VERSION ""

NS_ :

BS_:

BU_: SOBDMB_AWDC BCMC_CPDB BECMB_EPM PACM GWM _delete BCM ACCM DCDC_HEV GENERIC TSTR

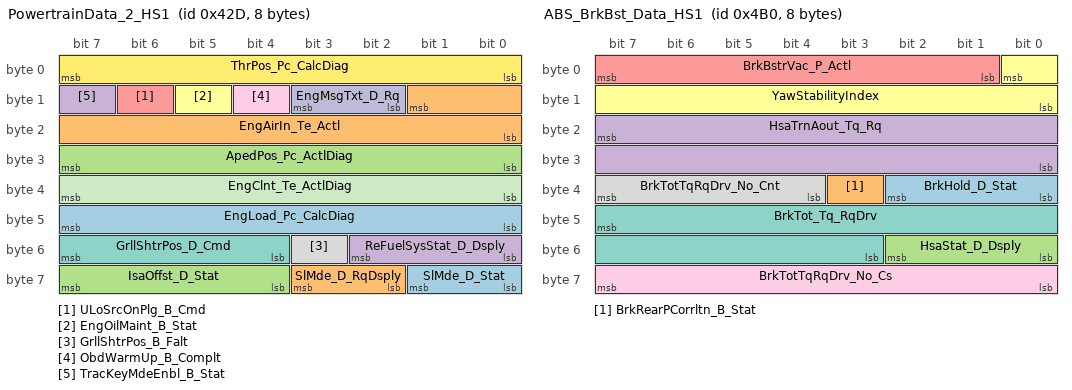
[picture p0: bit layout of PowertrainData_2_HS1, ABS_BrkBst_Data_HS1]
BO_ 1069 PowertrainData_2_HS1: 8 GWM
 SG_ SlMde_D_Stat : 57|2@0+ (1,0) [0|3] "SED" Vector__XXX
 SG_ SlMde_D_RqDsply : 59|2@0+ (1,0) [0|3] "SED" Vector__XXX
 SG_ IsaOffst_D_Stat : 63|4@0+ (1,0) [0|15] "SED" Vector__XXX
 SG_ ReFuelSysStat_D_Dsply : 50|3@0+ (1,0) [0|7] "SED" Vector__XXX
 SG_ ULoSrcOnPlg_B_Cmd : 14|1@0+ (1,0) [0|1] "SED"  DCDC_HEV
 SG_ EngOilMaint_B_Stat : 13|1@0+ (1,0) [0|1] "SED" Vector__XXX
 SG_ GrllShtrPos_D_Cmd : 55|4@0+ (1,0) [0|15] "SED"  BCM
 SG_ GrllShtrPos_B_Falt : 51|1@0+ (1,0) [0|1] "SED"  BCM
 SG_ ObdWarmUp_B_Complt : 12|1@0+ (1,0) [0|1] "SED"  SOBDMB_AWDC,DCDC_HEV
 SG_ EngMsgTxt_D_Rq : 11|2@0+ (1,0) [0|3] "SED" Vector__XXX
 SG_ EngClnt_Te_ActlDiag : 39|8@0+ (1,-40) [-40|215] "degC"  SOBDMB_AWDC
 SG_ ThrPos_Pc_CalcDiag : 7|8@0+ (0.392157,0) [0|100.000035] "%" Vector__XXX
 SG_ EngLoad_Pc_CalcDiag : 47|8@0+ (0.392157,0) [0|100.000035] "%"  SOBDMB_AWDC
 SG_ EngAirIn_Te_Actl : 9|10@0+ (0.25,-128) [-128|127.25] "degC"  BCM
 SG_ ApedPos_Pc_ActlDiag : 31|8@0+ (0.392157,0) [0|100.000035] "%"  SOBDMB_AWDC
 SG_ TracKeyMdeEnbl_B_Stat : 15|1@0+ (1,0) [0|1] "SED" Vector__XXX

BO_ 878 DCACA_Data4_HS1: 8 GWM
 SG_ PwBedPnlEnblScnd_B_Rq : 48|1@0+ (1,0) [0|1] "SED" Vector__XXX
 SG_ DcacSysScnd_B_Falt : 40|1@0+ (1,0) [0|1] "SED" Vector__XXX
 SG_ DcacOnScnd_B_Rq : 32|1@0+ (1,0) [0|1] "SED" Vector__XXX
 SG_ DcacGfciTestScnd_B_Rq : 24|1@0+ (1,0) [0|1] "SED" Vector__XXX
 SG_ EngExhMdeHrStrt_D_Stat : 53|5@0+ (1,0) [0|31] "SED" Vector__XXX
 SG_ EngExhMdeHrEnd_D_Stat : 63|5@0+ (1,0) [0|31] "SED" Vector__XXX
 SG_ EngExhMdeHrEnbl_D_Stat : 58|2@0+ (1,0) [0|3] "SED" Vector__XXX
 SG_ DcacGfciTest_B_Rq : 0|1@0+ (1,0) [0|1] "SED" Vector__XXX
 SG_ DcacOut_Pw_DsplyMx : 23|10@0+ (10,0) [0|10220] "watts"  GENERIC
 SG_ DcacOut1_Pw_Dsply : 39|7@0+ (100,0) [0|12600] "watts"  GENERIC
 SG_ DcacOut2_Pw_Dsply : 47|7@0+ (100,0) [0|12600] "watts"  GENERIC
 SG_ DcacHw_D_Confg : 11|4@0+ (1,0) [0|15] "SED"  GENERIC
 SG_ DcacFaltMsgTxt_D_Rq : 15|4@0+ (1,0) [0|15] "SED" Vector__XXX
 SG_ DcacLoFuelMsgTxt_D_Rq : 29|5@0+ (1,0) [0|31] "SED"  GENERIC
 SG_ DcacEngOnMsgTxt_D_Rq : 55|2@0+ (1,0) [0|3] "SED"  GENERIC
 SG_ DcacElPw_D_Stat : 2|2@0+ (1,0) [0|3] "SED" Vector__XXX
 SG_ PwBedPnlEnbl_B_Rq : 3|1@0+ (1,0) [0|1] "SED" Vector__XXX
 SG_ DcacOn_B_Rq : 4|1@0+ (1,0) [0|1] "SED" Vector__XXX
 SG_ DcacSys_B_Falt : 5|1@0+ (1,0) [0|1] "SED" Vector__XXX
 SG_ DcacLedCtl_D_Rq : 7|2@0+ (1,0) [0|3] "SED" Vector__XXX

BO_ 1200 ABS_BrkBst_Data_HS1: 8 GWM
 SG_ BrkHold_D_Stat : 34|3@0+ (1,0) [0|7] "SED" Vector__XXX
 SG_ BrkRearPCorrltn_B_Stat : 35|1@0+ (1,0) [0|1] "SED"  GENERIC
 SG_ HsaStat_D_Dsply : 50|3@0+ (1,0) [0|7] "SED"  GENERIC
 SG_ HsaTrnAout_Tq_Rq : 23|16@0+ (4,-131072) [-131072|131060] "Nm" Vector__XXX
 SG_ BrkBstrVac_P_Actl : 7|7@0+ (8,0) [0|1008] "Millibar" Vector__XXX
 SG_ YawStabilityIndex : 0|9@0+ (1,-256) [-256|255] "%"  GENERIC
 SG_ BrkTot_Tq_RqDrv : 47|13@0+ (4,0) [0|32760] "Nm" Vector__XXX
 SG_ BrkTotTqRqDrv_No_Cnt : 39|4@0+ (1,0) [0|15] "unitless" Vector__XXX
 SG_ BrkTotTqRqDrv_No_Cs : 63|8@0+ (1,0) [0|255] "unitless" Vector__XXX

BO_ 2015 TesterFunctionalReq_H1: 8 TSTR
 SG_ TesterFunctionalReq : 7|64@0+ (1,0) [0|1.84467E+019] "unitless"  SOBDMB_AWDC,BCMC_CPDB,BECMB_EPM,PACM,ACCM,GWM,GENERIC,DCDC_HEV,BCM

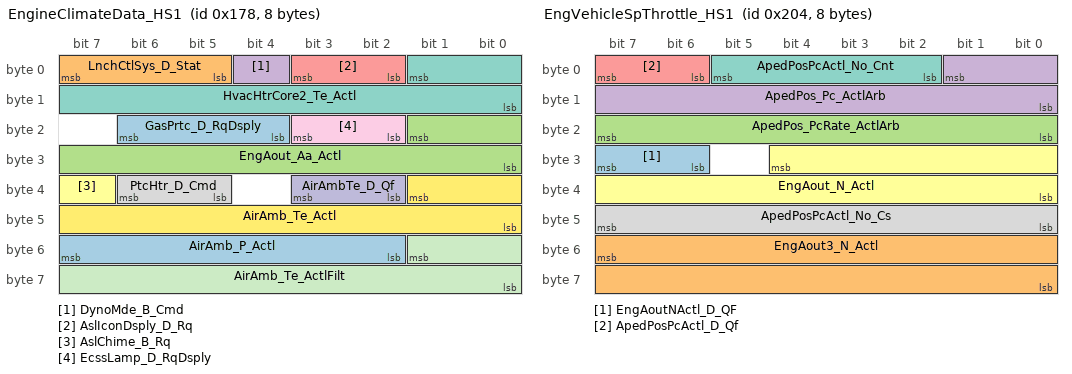
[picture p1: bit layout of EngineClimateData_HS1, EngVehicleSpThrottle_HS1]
BO_ 376 EngineClimateData_HS1: 8 GWM
 SG_ GasPrtc_D_RqDsply : 22|3@0+ (1,0) [0|7] "SED"  GENERIC
 SG_ LnchCtlSys_D_Stat : 7|3@0+ (1,0) [0|7] "SED"  GENERIC
 SG_ EngAout_Aa_Actl : 17|10@0+ (0.05,-25.6) [-25.6|25.55] "rpm/ms"  GENERIC
 SG_ DynoMde_B_Cmd : 4|1@0+ (1,0) [0|1] "SED"  GENERIC
 SG_ AslIconDsply_D_Rq : 3|2@0+ (1,0) [0|3] "SED"  GENERIC
 SG_ AslChime_B_Rq : 39|1@0+ (1,0) [0|1] "SED"  GENERIC
 SG_ HvacHtrCore2_Te_Actl : 1|10@0+ (0.25,-50) [-50|205.5] "degC"  GENERIC
 SG_ PtcHtr_D_Cmd : 38|2@0+ (1,0) [0|3] "SED"  GENERIC
 SG_ EcssLamp_D_RqDsply : 19|2@0+ (1,0) [0|3] "SED"  GENERIC
 SG_ AirAmbTe_D_Qf : 35|2@0+ (1,0) [0|3] "SED"  BCM
 SG_ AirAmb_Te_ActlFilt : 49|10@0+ (0.25,-128) [-128|127.75] "deg C"  GWM,ACCM,BCM
 SG_ AirAmb_Te_Actl : 33|10@0+ (0.25,-128) [-128|127.75] "degC"  BCM
 SG_ AirAmb_P_Actl : 55|6@0+ (10,500) [500|1110] "mbar"  BCM

BO_ 516 EngVehicleSpThrottle_HS1: 8 GWM
 SG_ EngAoutNActl_D_QF : 31|2@0+ (1,0) [0|3] "SED"  GENERIC
 SG_ EngAout3_N_Actl : 55|16@0+ (0.25,0) [0|16383.5] "RPM"  SOBDMB_AWDC
 SG_ ApedPos_PcRate_ActlArb : 23|8@0+ (0.04,-5) [-5|5.12] "%/ms"  GENERIC
 SG_ ApedPos_Pc_ActlArb : 1|10@0+ (0.1,0) [0|102.3] "%"  SOBDMB_AWDC,BCM
 SG_ ApedPosPcActl_D_Qf : 7|2@0+ (1,0) [0|3] "SED"  GENERIC
 SG_ EngAout_N_Actl : 28|13@0+ (2,0) [0|16382] "rpm"  BCM
 SG_ ApedPosPcActl_No_Cnt : 5|4@0+ (1,0) [0|15] "Unitless"  GENERIC
 SG_ ApedPosPcActl_No_Cs : 47|8@0+ (1,0) [0|255] "Unitless"  GENERIC

BO_ 377 EngineData_7_HS1: 8 GWM
 SG_ HvacAirFullOut_B_Rq : 23|1@0+ (1,0) [0|1] "SED"  GENERIC
 SG_ TrnManShif_D_IndDrv : 7|3@0+ (1,0) [0|7] "Unitless"  GENERIC
 SG_ EngAout_Tq_Actl : 2|11@0+ (1,-500) [-500|1547] "Nm"  GENERIC
 SG_ TrnManShifGear_D_IndDrv : 54|3@0+ (1,0) [0|7] "SED"  GENERIC
 SG_ EngFuelCutFull_B_Inhbt : 22|1@0+ (1,0) [0|1] "SED"  GENERIC
 SG_ EngDecelFuelCut_B_Allw : 21|1@0+ (1,0) [0|1] "SED"  GENERIC
 SG_ FuelFlw_Vl_Dsply : 49|10@0+ (25,0) [0|25575] "Micro_Liter"  GENERIC
 SG_ FuelFillInlet_B_Dsply : 32|1@0+ (1,0) [0|1] "SED"  GENERIC
 SG_ EngSrvcRqd_B_Rq : 19|1@0+ (1,0) [0|1] "SED"  GENERIC
 SG_ OdoCount : 47|8@0+ (0.2,0) [0|50.8] "Meters"  GENERIC
 SG_ EngOilLife_Pc_Actl : 39|7@0+ (1,0) [0|100] "Percent"  GENERIC
 SG_ EngTqSlwDly_T_Est : 18|11@0+ (1,0) [0|2047] "ms"  GENERIC
 SG_ TrnKickDown_B_RqDrv : 20|1@0+ (1,0) [0|1] "SED"  GENERIC
 SG_ FuelFilterLamp_B_Dsply : 50|1@0+ (1,0) [0|1] "SED"  GENERIC
 SG_ AirCondRec_B_Rq : 55|1@0+ (1,0) [0|1] "SED"  GENERIC
 SG_ AirCondClutch_B_Stats : 51|1@0+ (1,0) [0|1] "SED" Vector__XXX
 SG_ EngAoutTqActl_D_Qf : 4|2@0+ (1,0) [0|3] "SED"  GENERIC

BO_ 76 RCMStatusMessage2_HS1: 8 GWM
 SG_ RstrnPsngrOn_D_Stat : 39|4@0+ (1,0) [0|15] "SED"  GENERIC
 SG_ FirstRowBuckle_No_Cs : 47|8@0+ (1,0) [0|255] "unitless"  GENERIC
 SG_ RCMStatusMsg2_No_Cnt : 35|4@0+ (1,0) [0|15] "Unitless"  GENERIC
 SG_ PsngrFmidDetct_D_Actl : 26|2@0+ (1,0) [0|3] "SED"  GENERIC
 SG_ FirstRowBuckleMid : 28|2@0+ (1,0) [0|3] "SED"  GENERIC
 SG_ ThirdRowBucklePsngr : 17|2@0+ (1,0) [0|3] "SED"  GENERIC
 SG_ ThirdRowBuckleMid : 19|2@0+ (1,0) [0|3] "SED"  GENERIC
 SG_ ThirdRowBuckleDriver : 21|2@0+ (1,0) [0|3] "SED"  GENERIC
 SG_ SecondRowBucklePsngr : 23|2@0+ (1,0) [0|3] "SED"  GENERIC
 SG_ SecondRowBuckleMid : 9|2@0+ (1,0) [0|3] "SED"  GENERIC
 SG_ SecondRowBuckleDriver : 11|2@0+ (1,0) [0|3] "SED"  GENERIC
 SG_ FirstRowBuckleDriver : 15|2@0+ (1,0) [0|3] "SED"  BCM
 SG_ RILReq : 7|2@0+ (1,0) [0|3] "SED"  GENERIC
 SG_ FirstRowBucklePsngr : 13|2@0+ (1,0) [0|3] "SED" Vector__XXX
 SG_ RstrnImpactEvntStatus : 3|3@0+ (1,0) [0|7] "SED"  ACCM,BCM
 SG_ PsngrFrntDetct_D_Actl : 5|2@0+ (1,0) [0|3] "SED"  GENERIC
 SG_ EDRTriggerEvntSync : 29|1@0+ (1,0) [0|1] "SED"  GENERIC
 SG_ PassRstrnInd_Req : 31|2@0+ (1,0) [0|3] "SED"  GENERIC

BO_ 1870 TesterPhysicalResDCDC: 8 DCDC_HEV
 SG_ TesterPhysicalResDCDC : 7|64@0+ (1,0) [0|1.84467E+019] "unitless"  TSTR

BO_ 1862 TesterPhysicalReqDCDC: 8 TSTR
 SG_ TesterPhysicalReqDCDC : 7|64@0+ (1,0) [0|1.84467E+019] "unitless"  DCDC_HEV

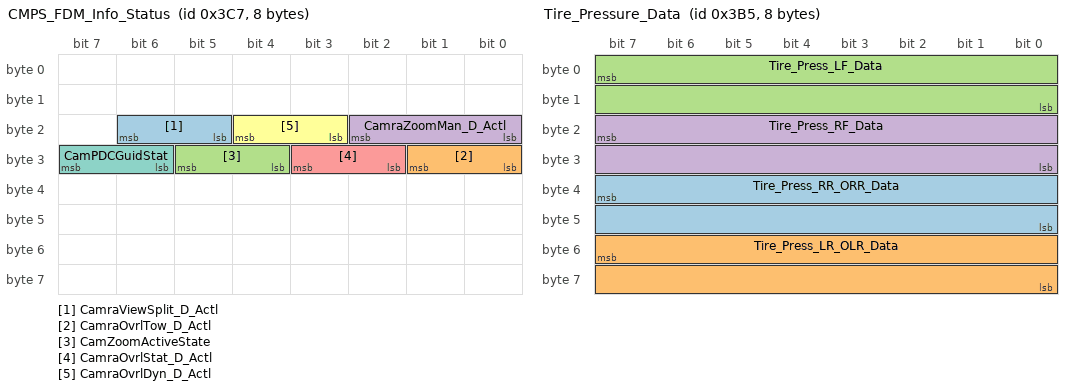
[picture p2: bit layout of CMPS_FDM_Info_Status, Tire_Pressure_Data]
BO_ 967 CMPS_FDM_Info_Status: 8 BCM
 SG_ CamraViewSplit_D_Actl : 22|2@0+ (1,0) [0|3] "SED"  GWM
 SG_ CamraOvrlTow_D_Actl : 25|2@0+ (1,0) [0|3] "SED"  GENERIC,GWM
 SG_ CamZoomActiveState : 29|2@0+ (1,0) [0|3] "SED"  GWM
 SG_ CamraZoomMan_D_Actl : 18|3@0+ (1,0) [0|7] "SED"  GWM
 SG_ CamraOvrlStat_D_Actl : 27|2@0+ (1,0) [0|3] "SED"  GWM
 SG_ CamraOvrlDyn_D_Actl : 20|2@0+ (1,0) [0|3] "SED"  GWM
 SG_ CamPDCGuidStat : 31|2@0+ (1,0) [0|3] "SED"  GWM

BO_ 949 Tire_Pressure_Data: 8 BCM
 SG_ Tire_Press_RR_ORR_Data : 39|16@0+ (1,0) [0|65533] "kilopascal"  GWM
 SG_ Tire_Press_LR_OLR_Data : 55|16@0+ (1,0) [0|65533] "kilopascal"  GWM
 SG_ Tire_Press_LF_Data : 7|16@0+ (1,0) [0|65533] "kilopascal"  GWM
 SG_ Tire_Press_RF_Data : 23|16@0+ (1,0) [0|65533] "kilopascal"  GWM

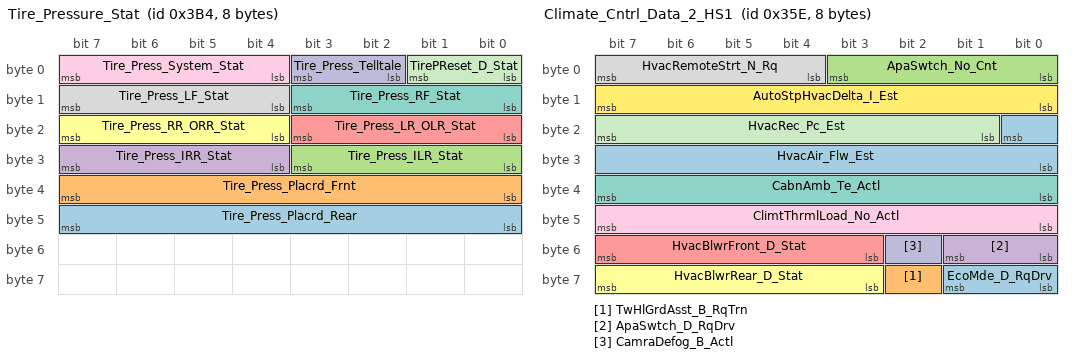
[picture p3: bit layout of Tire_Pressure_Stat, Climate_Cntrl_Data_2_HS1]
BO_ 948 Tire_Pressure_Stat: 8 BCM
 SG_ Tire_Press_Placrd_Rear : 47|8@0+ (1,0) [0|255] "pounds/inch^2"  GWM
 SG_ Tire_Press_Placrd_Frnt : 39|8@0+ (1,0) [0|255] "pounds/inch^2"  GWM
 SG_ Tire_Press_ILR_Stat : 27|4@0+ (1,0) [0|15] "SED"  GWM
 SG_ Tire_Press_IRR_Stat : 31|4@0+ (1,0) [0|15] "SED"  GWM
 SG_ Tire_Press_LR_OLR_Stat : 19|4@0+ (1,0) [0|15] "SED"  GWM
 SG_ Tire_Press_RR_ORR_Stat : 23|4@0+ (1,0) [0|15] "SED"  GWM
 SG_ Tire_Press_RF_Stat : 11|4@0+ (1,0) [0|15] "SED"  GWM
 SG_ Tire_Press_LF_Stat : 15|4@0+ (1,0) [0|15] "SED"  GWM
 SG_ Tire_Press_System_Stat : 7|4@0+ (1,0) [0|15] "SED"  GWM
 SG_ Tire_Press_Telltale : 3|2@0+ (1,0) [0|3] "SED"  GWM
 SG_ TirePReset_D_Stat : 1|2@0+ (1,0) [0|3] "Discrete"  GWM

BO_ 1077 Cluster_Info4_HS1: 8 GWM
 SG_ PrkLckCtlEnbl_D_RqIpc_UB : 48|1@0+ (1,0) [0|1] "SED"  BCM
 SG_ PrkLckCtlEnbl_D_RqIpc : 50|2@0+ (1,0) [0|3] "SED"  BCM
 SG_ FuelLvl_Pc_Dsply_UB : 45|1@0+ (1,0) [0|1] "SED"  GENERIC
 SG_ PtWakeupActv1_B_Rq : 44|1@0+ (1,0) [0|1] "SED"  BCM
 SG_ PtWakeupActv1_B_Rq_UB : 43|1@0+ (1,0) [0|1] "SED"  BCM
 SG_ Remote_Start_Req_UB : 23|1@0+ (1,0) [0|1] "SED"  BCM
 SG_ Remote_Start_Req : 9|2@0+ (1,0) [0|3] "SED"  BCM
 SG_ TurnLampTrlrRr_B_Stat_UB : 16|1@0+ (1,0) [0|1] "SED"  BCM
 SG_ DistanceBarSetting_UB : 12|1@0+ (1,0) [0|1] "SED"  BCM
 SG_ CamraZoomMan_D_Rq_UB : 14|1@0+ (1,0) [0|1] "SED"  BCM
 SG_ CamraOvrlStat_D_Rq_UB : 2|1@0+ (1,0) [0|1] "SED"  BCM
 SG_ CamraOvrlDyn_D_Rq_UB : 4|1@0+ (1,0) [0|1] "SED"  BCM
 SG_ CamAutoTowbarZoom_UB : 6|1@0+ (1,0) [0|1] "SED"  BCM
 SG_ DistanceBarSetting : 13|1@0+ (1,0) [0|1] "SED"  BCM
 SG_ CamraZoomMan_D_Rq : 1|3@0+ (1,0) [0|7] "SED"  BCM
 SG_ CamraOvrlStat_D_Rq : 3|1@0+ (1,0) [0|1] "SED"  BCM
 SG_ CamraOvrlDyn_D_Rq : 5|1@0+ (1,0) [0|1] "SED"  BCM
 SG_ CamAutoTowbarZoom : 7|1@0+ (1,0) [0|1] "SED"  BCM
 SG_ PwLftgtIntSw_B_Stat_UB : 10|1@0+ (1,0) [0|1] "SED"  BCM
 SG_ PwLftgtIntSw_B_Stat : 11|1@0+ (1,0) [0|1] "SED"  BCM
 SG_ TurnLampTrlrRl_B_Stat_UB : 18|1@0+ (1,0) [0|1] "SED"  BCM
 SG_ TurnLampTrlrRr_B_Stat : 17|1@0+ (1,0) [0|1] "SED"  BCM
 SG_ TurnLampTrlrRl_B_Stat : 22|1@0+ (1,0) [0|1] "SED"  BCM
 SG_ FuelLvl_Pc_Dsply : 25|10@0+ (0.108696,-5.217408) [-5.217408|105.9786] "Percent" Vector__XXX

BO_ 862 Climate_Cntrl_Data_2_HS1: 8 GWM
 SG_ EcoMde_D_RqDrv : 57|2@0+ (1,0) [0|3] "SED" Vector__XXX
 SG_ TwHlGrdAsst_B_RqTrn : 58|1@0+ (1,0) [0|1] "SED" Vector__XXX
 SG_ ApaSwtch_No_Cnt : 3|4@0+ (1,0) [0|15] "Unitless" Vector__XXX
 SG_ ApaSwtch_D_RqDrv : 49|2@0+ (1,0) [0|3] "SED" Vector__XXX
 SG_ HvacBlwrFront_D_Stat : 55|5@0+ (1,0) [0|31] "SED"  BCM
 SG_ HvacBlwrRear_D_Stat : 63|5@0+ (1,0) [0|31] "SED"  BCM
 SG_ CabnAmb_Te_Actl : 39|8@0+ (0.5,-57) [-57|70] "degreesC" Vector__XXX
 SG_ HvacRemoteStrt_N_Rq : 7|4@0+ (100,450) [450|1950] "RPM" Vector__XXX
 SG_ ClimtThrmlLoad_No_Actl : 47|8@0+ (1,0) [0|254] "unitless" Vector__XXX
 SG_ CamraDefog_B_Actl : 50|1@0+ (1,0) [0|1] "SED"  GENERIC
 SG_ HvacRec_Pc_Est : 23|7@0+ (1,0) [0|127] "Percent" Vector__XXX
 SG_ AutoStpHvacDelta_I_Est : 15|8@0+ (1,-192) [-192|62] "ampere"  BCM
 SG_ HvacAir_Flw_Est : 16|9@0+ (0.5,0) [0|255.5] "liter/second" Vector__XXX

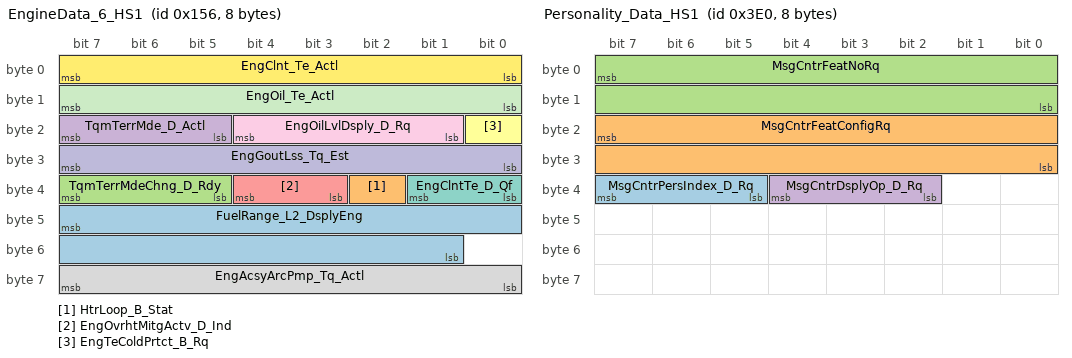
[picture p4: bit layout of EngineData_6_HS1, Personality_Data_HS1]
BO_ 342 EngineData_6_HS1: 8 GWM
 SG_ FuelRange_L2_DsplyEng : 47|15@0+ (0.1,0) [0|3276.7] "kilometer"  GENERIC
 SG_ HtrLoop_B_Stat : 34|1@0+ (1,0) [0|1] "SED"  GENERIC
 SG_ TqmTerrMdeChng_D_Rdy : 39|3@0+ (1,0) [0|7] "SED"  GENERIC
 SG_ TqmTerrMde_D_Actl : 23|3@0+ (1,0) [0|7] "SED"  GENERIC
 SG_ EngOvrhtMitgActv_D_Ind : 36|2@0+ (1,0) [0|3] "SED"  GENERIC
 SG_ EngTeColdPrtct_B_Rq : 16|1@0+ (1,0) [0|1] "SED"  GENERIC
 SG_ EngClntTe_D_Qf : 33|2@0+ (1,0) [0|3] "SED"  BCM
 SG_ EngAcsyArcPmp_Tq_Actl : 63|8@0+ (0.5,0) [0|126.5] "Nm"  GENERIC
 SG_ EngOilLvlDsply_D_Rq : 20|4@0+ (1,0) [0|15] "SED"  GENERIC
 SG_ EngGoutLss_Tq_Est : 31|8@0+ (1,0) [0|255] "Nm"  GENERIC
 SG_ EngOil_Te_Actl : 15|8@0+ (1,-60) [-60|193] "degC" Vector__XXX
 SG_ EngClnt_Te_Actl : 7|8@0+ (1,-60) [-60|195] "degC"  BCM

BO_ 992 Personality_Data_HS1: 8 GWM
 SG_ MsgCntrPersIndex_D_Rq : 39|3@0+ (1,0) [0|7] "SED"  BCM
 SG_ MsgCntrFeatConfigRq : 23|16@0+ (1,0) [0|65535] "unitless"  BCM
 SG_ MsgCntrFeatNoRq : 7|16@0+ (1,0) [0|65535] "Number"  BCM
 SG_ MsgCntrDsplyOp_D_Rq : 36|3@0+ (1,0) [0|7] "SED"  BCM

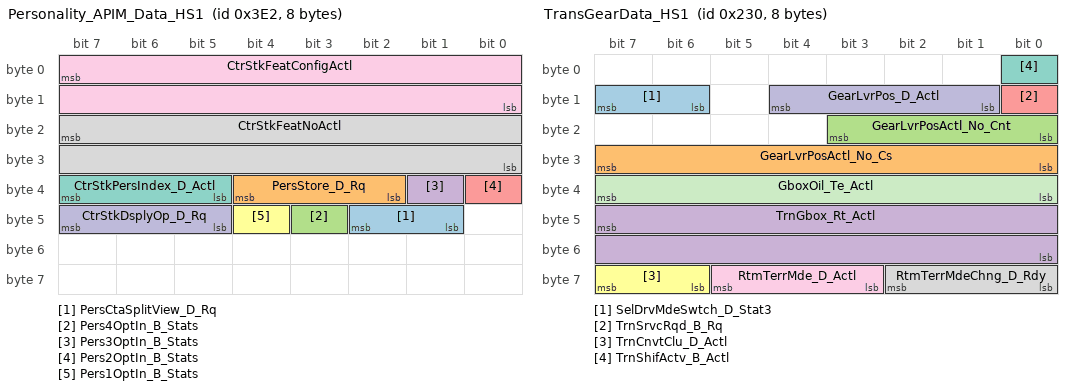
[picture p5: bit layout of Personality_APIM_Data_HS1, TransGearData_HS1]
BO_ 994 Personality_APIM_Data_HS1: 8 GWM
 SG_ PersCtaSplitView_D_Rq : 42|2@0+ (1,0) [0|3] "SED"  GENERIC
 SG_ PersStore_D_Rq : 36|3@0+ (1,0) [0|7] "SED"  GENERIC
 SG_ Pers4OptIn_B_Stats : 43|1@0+ (1,0) [0|1] "SED"  BCM
 SG_ Pers3OptIn_B_Stats : 33|1@0+ (1,0) [0|1] "SED"  BCM
 SG_ Pers2OptIn_B_Stats : 32|1@0+ (1,0) [0|1] "SED"  BCM
 SG_ Pers1OptIn_B_Stats : 44|1@0+ (1,0) [0|1] "SED"  BCM
 SG_ CtrStkPersIndex_D_Actl : 39|3@0+ (1,0) [0|7] "SED"  BCM
 SG_ CtrStkFeatNoActl : 23|16@0+ (1,0) [0|65535] "Undefined"  BCM
 SG_ CtrStkFeatConfigActl : 7|16@0+ (1,0) [0|65535] "Undefined"  BCM
 SG_ CtrStkDsplyOp_D_Rq : 47|3@0+ (1,0) [0|7] "SED"  BCM

BO_ 65 Global_PATS_Control_Info: 8 BCM
 SG_ immoControlData_T1 : 15|40@0+ (1,0) [0|1099511627775] "Encrypted"  GWM
 SG_ immoControlCmd_T1 : 7|3@0+ (1,0) [0|7] "SED"  GWM

BO_ 66 Global_PATS_Control_Info2: 8 BCM
 SG_ immoControlData_T2 : 15|40@0+ (1,0) [0|1099511627775] "Encrypted"  SOBDMB_AWDC,GWM
 SG_ immoControlCmd_T2 : 7|3@0+ (1,0) [0|7] "SED"  SOBDMB_AWDC,GWM

BO_ 1838 TesterPhysicalResBCM: 8 BCM
 SG_ TesterPhysicalResBCM : 7|64@0+ (1,0) [0|1.84467E+019] "unitless"  TSTR

BO_ 1830 TesterPhysicalReqBCM: 8 TSTR
 SG_ TesterPhysicalReqBCM : 7|64@0+ (1,0) [0|1.84467E+019] "unitless"  BCM

BO_ 560 TransGearData_HS1: 8 GWM
 SG_ SelDrvMdeSwtch_D_Stat3 : 15|2@0+ (1,0) [0|3] "SED" Vector__XXX
 SG_ GearLvrPosActl_No_Cs : 31|8@0+ (1,0) [0|255] "Unitless" Vector__XXX
 SG_ GearLvrPosActl_No_Cnt : 19|4@0+ (1,0) [0|15] "Unitless" Vector__XXX
 SG_ TrnGbox_Rt_Actl : 47|16@0+ (0.001,0) [0|65.533] "Unitless" Vector__XXX
 SG_ TrnSrvcRqd_B_Rq : 8|1@0+ (1,0) [0|1] "SED" Vector__XXX
 SG_ TrnCnvtClu_D_Actl : 63|2@0+ (1,0) [0|3] "SED" Vector__XXX
 SG_ TrnShifActv_B_Actl : 0|1@0+ (1,0) [0|1] "SED" Vector__XXX
 SG_ RtmTerrMdeChng_D_Rdy : 58|3@0+ (1,0) [0|7] "SED" Vector__XXX
 SG_ RtmTerrMde_D_Actl : 61|3@0+ (1,0) [0|7] "SED" Vector__XXX
 SG_ GearLvrPos_D_Actl : 12|4@0+ (1,0) [0|15] "SED"  PACM,DCDC_HEV,BCM
 SG_ GboxOil_Te_Actl : 39|8@0+ (1,-60) [-60|193] "degC" Vector__XXX

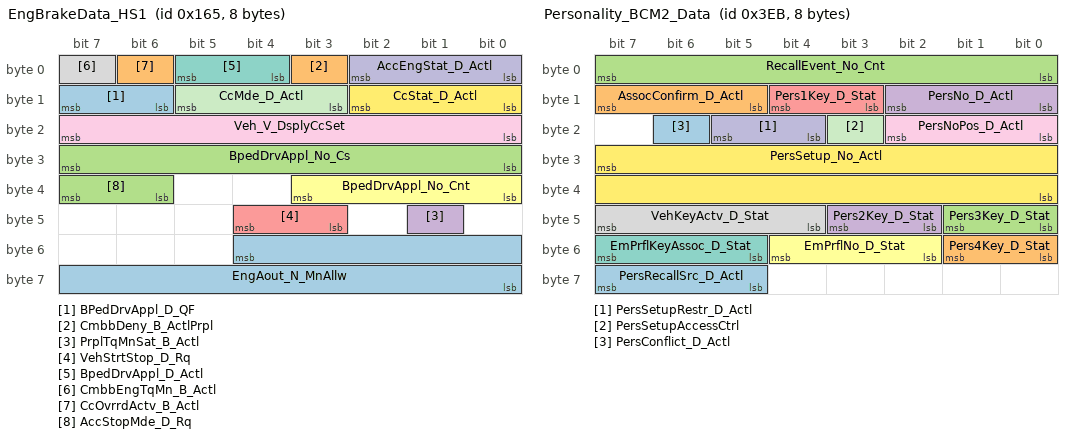
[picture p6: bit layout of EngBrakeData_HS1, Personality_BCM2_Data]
BO_ 357 EngBrakeData_HS1: 8 GWM
 SG_ BPedDrvAppl_D_QF : 15|2@0+ (1,0) [0|3] "SED"  GENERIC
 SG_ CmbbDeny_B_ActlPrpl : 3|1@0+ (1,0) [0|1] "SED"  GENERIC
 SG_ BpedDrvAppl_No_Cs : 31|8@0+ (1,0) [0|255] "Unitless"  GENERIC
 SG_ PrplTqMnSat_B_Actl : 41|1@0+ (1,0) [0|1] "SED"  GENERIC
 SG_ VehStrtStop_D_Rq : 44|2@0+ (1,0) [0|3] "SED"  GENERIC
 SG_ BpedDrvAppl_No_Cnt : 35|4@0+ (1,0) [0|15] "Unitless"  GENERIC
 SG_ BpedDrvAppl_D_Actl : 5|2@0+ (1,0) [0|3] "SED" Vector__XXX
 SG_ CmbbEngTqMn_B_Actl : 7|1@0+ (1,0) [0|1] "SED"  GENERIC
 SG_ Veh_V_DsplyCcSet : 23|8@0+ (1,0) [0|253] "Unitless"  GENERIC
 SG_ AccEngStat_D_Actl : 2|3@0+ (1,0) [0|7] "SED"  GENERIC
 SG_ CcMde_D_Actl : 13|3@0+ (1,0) [0|7] "SED" Vector__XXX
 SG_ CcStat_D_Actl : 10|3@0+ (1,0) [0|7] "SED"  GENERIC
 SG_ EngAout_N_MnAllw : 52|13@0+ (2,0) [0|16382] "rpm"  GENERIC
 SG_ CcOvrrdActv_B_Actl : 6|1@0+ (1,0) [0|1] "SED"  GENERIC
 SG_ AccStopMde_D_Rq : 39|2@0+ (1,0) [0|3] "SED"  GENERIC

BO_ 1003 Personality_BCM2_Data: 8 BCM
 SG_ PersRecallSrc_D_Actl : 63|3@0+ (1,0) [0|7] "SED"  GWM
 SG_ Pers4Key_D_Stat : 49|2@0+ (1,0) [0|3] "SED"  GWM
 SG_ Pers3Key_D_Stat : 41|2@0+ (1,0) [0|3] "SED"  GWM
 SG_ Pers2Key_D_Stat : 43|2@0+ (1,0) [0|3] "SED"  GWM
 SG_ Pers1Key_D_Stat : 12|2@0+ (1,0) [0|3] "SED"  GWM
 SG_ EmPrflNo_D_Stat : 52|3@0+ (1,0) [0|7] "SED"  GWM
 SG_ EmPrflKeyAssoc_D_Stat : 55|3@0+ (1,0) [0|7] "SED"  GWM
 SG_ VehKeyActv_D_Stat : 47|4@0+ (1,0) [0|15] "SED"  GWM
 SG_ PersNoPos_D_Actl : 18|3@0+ (1,0) [0|7] "SED"  GWM
 SG_ PersSetupRestr_D_Actl : 21|2@0+ (1,0) [0|3] "SED"  GWM
 SG_ PersSetupAccessCtrl : 19|1@0+ (1,0) [0|1] "SED"  GWM
 SG_ PersSetup_No_Actl : 31|16@0+ (1,0) [0|65535] "Number"  GWM
 SG_ PersConflict_D_Actl : 22|1@0+ (1,0) [0|1] "SED"  GWM
 SG_ AssocConfirm_D_Actl : 15|3@0+ (1,0) [0|7] "SED"  GWM
 SG_ RecallEvent_No_Cnt : 7|8@0+ (1,0) [0|255] "Counts"  GWM
 SG_ PersNo_D_Actl : 10|3@0+ (1,0) [0|7] "SED"  GWM

BO_ 1034 GGCC_Config_Mgmt_ID_1: 8 BCM
 SG_ VehicleGGCCData : 7|64@0+ (1,0) [0|1.84467E+019] "mixed"  SOBDMB_AWDC,ACCM,DCDC_HEV,GWM

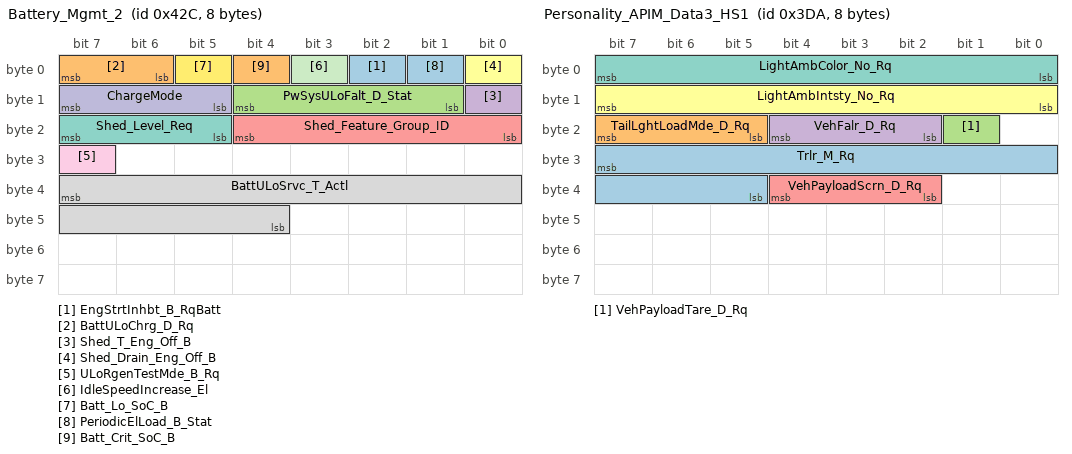
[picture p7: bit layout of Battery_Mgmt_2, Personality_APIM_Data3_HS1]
BO_ 1068 Battery_Mgmt_2: 8 BCM
 SG_ EngStrtInhbt_B_RqBatt : 2|1@0+ (1,0) [0|1] "SED"  GWM
 SG_ BattULoChrg_D_Rq : 7|2@0+ (1,0) [0|3] "SED"  GWM
 SG_ PwSysULoFalt_D_Stat : 12|4@0+ (1,0) [0|15] "SED"  GWM
 SG_ Shed_T_Eng_Off_B : 8|1@0+ (1,0) [0|1] "SED"  GWM
 SG_ Shed_Feature_Group_ID : 20|5@0+ (1,0) [0|31] "SED"  GWM
 SG_ Shed_Drain_Eng_Off_B : 0|1@0+ (1,0) [0|1] "SED"  GWM
 SG_ Shed_Level_Req : 23|3@0+ (1,0) [0|7] "SED"  GWM
 SG_ BattULoSrvc_T_Actl : 39|12@0+ (1,0) [0|4095] "days"  GWM
 SG_ ULoRgenTestMde_B_Rq : 31|1@0+ (1,0) [0|1] "SED"  GWM
 SG_ ChargeMode : 15|3@0+ (1,0) [0|7] "SED"  GWM
 SG_ IdleSpeedIncrease_El : 3|1@0+ (1,0) [0|1] "SED"  GWM
 SG_ Batt_Lo_SoC_B : 5|1@0+ (1,0) [0|1] "SED"  GWM
 SG_ PeriodicElLoad_B_Stat : 1|1@0+ (1,0) [0|1] "SED"  GWM
 SG_ Batt_Crit_SoC_B : 4|1@0+ (1,0) [0|1] "SED"  GWM

BO_ 947 BodyInfo_3: 8 BCM
 SG_ ValetMode_D_Mem : 16|1@0+ (1,0) [0|1] "SED"  GWM
 SG_ DimmingLvlEvnt_No_Actl : 18|2@0+ (1,0) [0|3] "unitless"  GWM
 SG_ DrStatDrvErrCnt_B_Stat : 19|1@0+ (1,0) [0|1] "SED"  GWM
 SG_ TurnLghtRight_D_Rq : 63|2@0+ (1,0) [0|3] "SED"  GWM
 SG_ TurnLghtRightOn_B_Stat : 35|1@0+ (1,0) [0|1] "SED"  GWM
 SG_ TurnLghtLeftOn_B_Stat : 54|1@0+ (1,0) [0|1] "SED"  GWM
 SG_ FogLghtRearOn_B_Stat : 1|1@0+ (1,0) [0|1] "SED"  GWM
 SG_ Backlit_LED_Status : 23|4@0+ (1,0) [0|15] "SED"  GWM
 SG_ TurnLghtLeft_D_Rq : 9|2@0+ (1,0) [0|3] "SED"  GWM
 SG_ FogLghtFrontOn_B_Stat : 56|1@0+ (1,0) [0|1] "SED"  GWM
 SG_ IgnKeyType_D_Actl : 39|4@0+ (1,0) [0|15] "SED"  GWM
 SG_ Parklamp_Status : 3|2@0+ (1,0) [0|3] "SED"  GWM
 SG_ Litval : 47|8@0+ (1,0) [0|253] "SED"  GWM
 SG_ Key_In_Ignition_Stat : 11|1@0+ (1,0) [0|1] "SED"  GWM
 SG_ Ignition_Status : 7|4@0+ (1,0) [0|15] "SED"  BCMC_CPDB,BECMB_EPM,PACM,DCDC_HEV,ACCM,GWM
 SG_ Dimming_Lvl : 31|8@0+ (1,0) [0|253] "SED"  GWM
 SG_ Day_Night_Status : 15|2@0+ (1,0) [0|3] "SED"  GWM
 SG_ Remote_Start_Status : 13|2@0+ (1,0) [0|3] "SED"  SOBDMB_AWDC,BCMC_CPDB,BECMB_EPM,GWM
 SG_ DrStatTgate_B_Actl : 0|1@0+ (1,0) [0|1] "SED"  GWM
 SG_ DrStatRr_B_Actl : 49|1@0+ (1,0) [0|1] "SED"  GWM
 SG_ DrStatRl_B_Actl : 48|1@0+ (1,0) [0|1] "SED"  GWM
 SG_ DrStatPsngr_B_Actl : 60|1@0+ (1,0) [0|1] "SED"  GWM
 SG_ DrStatInnrTgate_B_Actl : 58|1@0+ (1,0) [0|1] "SED"  GWM
 SG_ DrStatHood_B_Actl : 59|1@0+ (1,0) [0|1] "SED"  GWM
 SG_ DrStatDrv_B_Actl : 61|1@0+ (1,0) [0|1] "SED"  GWM
 SG_ PrkBrkActv_B_Actl : 55|1@0+ (1,0) [0|1] "SED"  GWM
 SG_ LifeCycMde_D_Actl : 53|4@0+ (1,0) [0|15] "SED"  SOBDMB_AWDC,BCMC_CPDB,PACM,GWM
 SG_ Delay_Accy : 57|1@0+ (1,0) [0|1] "SED"  GWM
 SG_ CrashEvnt_D_Stat : 34|2@0+ (1,0) [0|3] "SED"  GWM
 SG_ FuelPmpInhbt_B_Stat : 32|1@0+ (1,0) [0|1] "SED"  GWM
 SG_ BodySrvcRqd_B_Rq : 10|1@0+ (1,0) [0|1] "SED"  GWM

BO_ 986 Personality_APIM_Data3_HS1: 8 GWM
 SG_ Trlr_M_Rq : 31|11@0+ (10,0) [0|20450] "kilogram"  GENERIC
 SG_ TailLghtLoadMde_D_Rq : 23|3@0+ (1,0) [0|7] "SED" Vector__XXX
 SG_ VehPayloadTare_D_Rq : 17|1@0+ (1,0) [0|1] "SED"  GENERIC
 SG_ VehFalr_D_Rq : 20|3@0+ (1,0) [0|7] "SED"  GENERIC
 SG_ VehPayloadScrn_D_Rq : 36|3@0+ (1,0) [0|7] "SED"  GENERIC
 SG_ LightAmbIntsty_No_Rq : 15|8@0+ (1,0) [0|255] "unitless"  BCM
 SG_ LightAmbColor_No_Rq : 7|8@0+ (1,0) [0|255] "Discrete"  BCM

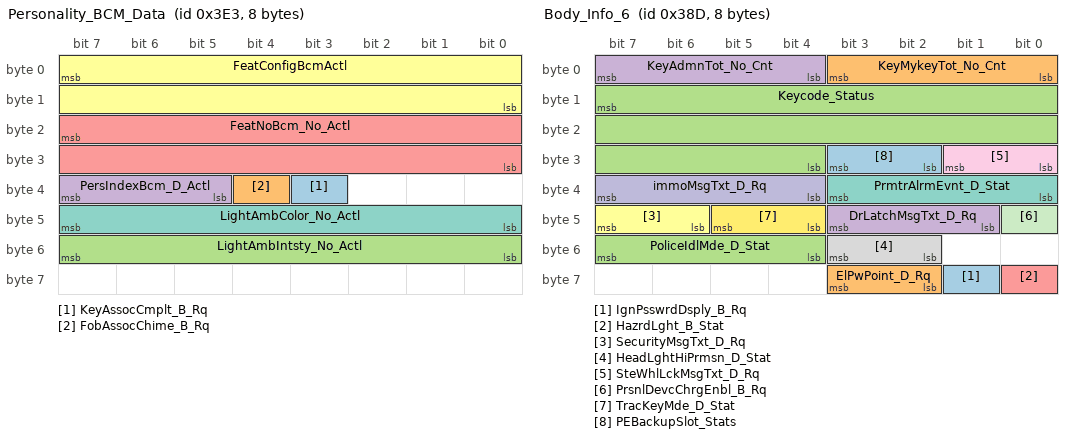
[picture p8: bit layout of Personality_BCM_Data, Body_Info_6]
BO_ 995 Personality_BCM_Data: 8 BCM
 SG_ KeyAssocCmplt_B_Rq : 35|1@0+ (1,0) [0|1] "SED"  GWM
 SG_ FobAssocChime_B_Rq : 36|1@0+ (1,0) [0|1] "SED"  GWM
 SG_ LightAmbIntsty_No_Actl : 55|8@0+ (1,0) [0|255] "unitless"  GWM
 SG_ PersIndexBcm_D_Actl : 39|3@0+ (1,0) [0|7] "SED"  GWM
 SG_ FeatNoBcm_No_Actl : 23|16@0+ (1,0) [0|65535] "Number"  GWM
 SG_ FeatConfigBcmActl : 7|16@0+ (1,0) [0|65535] "Undefined"  GWM
 SG_ LightAmbColor_No_Actl : 47|8@0+ (1,0) [0|255] "Discrete"  GWM

BO_ 963 BCM_Lamp_Stat: 8 BCM
 SG_ Illuminated_Entry_Stat : 63|2@0+ (1,0) [0|3] "SED"  GWM
 SG_ Dr_Courtesy_Light_Stat : 49|2@0+ (1,0) [0|3] "SED"  GWM
 SG_ Courtesy_Delay_Status : 51|2@0+ (1,0) [0|3] "SED"  GWM
 SG_ ImpactEvntFdbck_D_Stat : 53|2@0+ (1,0) [0|3] "SED"  GWM
 SG_ WrlssAcsyChrgInhbt_B_Rq : 40|1@0+ (1,0) [0|1] "SED"  GWM
 SG_ PudLampPsngr_D_Rq : 57|2@0+ (1,0) [0|3] "SED"  GWM
 SG_ HeadLampLoOut_B_Stat : 32|1@0+ (1,0) [0|1] "SED"  GWM
 SG_ CrnrLghtRight_Pc_Rq : 47|7@0+ (1,0) [0|100] "percent"  GWM
 SG_ CrnrLghtLeft_Pc_Rq : 39|7@0+ (1,0) [0|100] "percent"  GWM
 SG_ HeadLghtHiFdbck_D_Stat : 55|2@0+ (1,0) [0|3] "SED"  GWM
 SG_ PudLampDrv_D_Rq : 59|2@0+ (1,0) [0|3] "SED"  GWM
 SG_ TrnNotInPrkChime_B_Rq : 24|1@0+ (1,0) [0|1] "SED"  GWM
 SG_ PrkLightChime_B_Rq : 25|1@0+ (1,0) [0|1] "SED"  GWM
 SG_ KeyInIgnWarn_B_Cmd : 27|1@0+ (1,0) [0|1] "SED"  GWM
 SG_ HomeSafeLtChime_B_Rq : 28|1@0+ (1,0) [0|1] "SED"  GWM
 SG_ StopLghtOn_B_Stat : 8|1@0+ (1,0) [0|1] "SED"  GWM
 SG_ RvrseLghtOn_B_Stat : 9|1@0+ (1,0) [0|1] "SED"  GWM
 SG_ PrkLght_D_Stat : 13|2@0+ (1,0) [0|3] "SED"  GWM
 SG_ HeadLghtSwtch_D_Stat : 15|2@0+ (1,0) [0|3] "SED"  GWM
 SG_ HeadLampLoFrOn_B_Stat : 2|1@0+ (1,0) [0|1] "SED"  GWM
 SG_ HeadLampLoFlOn_B_Stat : 3|1@0+ (1,0) [0|1] "SED"  GWM
 SG_ HeadLampLoActv_B_Stat : 4|1@0+ (1,0) [0|1] "SED"  GWM
 SG_ Headlamp_On_Wrning_Cmd : 29|1@0+ (1,0) [0|1] "SED"  GWM
 SG_ Park_Brake_Chime_Rqst : 26|1@0+ (1,0) [0|1] "SED"  GWM
 SG_ HeadLghtHiOn_B_Stat : 1|1@0+ (1,0) [0|1] "SED"  GWM
 SG_ BrkWarnInd_B_Rq : 20|1@0+ (1,0) [0|1] "SED"  GWM
 SG_ Brk_Fluid_Lvl_Low : 31|2@0+ (1,0) [0|3] "SED"  GWM
 SG_ ReducedGuard_D_Stat : 19|2@0+ (1,0) [0|3] "SED"  GWM
 SG_ Perimeter_Alarm_Status : 17|2@0+ (1,0) [0|3] "SED"  BCMC_CPDB,GWM
 SG_ Courtesy_BSave_Stat : 7|2@0+ (1,0) [0|3] "SED"  GWM
 SG_ DrTgateLck_D_Stat : 61|2@0+ (1,0) [0|3] "SED"  GWM
 SG_ WndwGlbl_D_Cmd : 23|3@0+ (1,0) [0|7] "SED"  GWM
 SG_ PudLamp_D_Rq : 11|2@0+ (1,0) [0|3] "SED"  GWM
 SG_ DayRnngLampOn_B_Stat : 5|1@0+ (1,0) [0|1] "SED"  GWM
 SG_ PerimeterAlarmChimeRq : 0|1@0+ (1,0) [0|1] "SED"  GWM

BO_ 909 Body_Info_6: 8 BCM
 SG_ IgnPsswrdDsply_B_Rq : 57|1@0+ (1,0) [0|1] "SED"  GWM
 SG_ ElPwPoint_D_Rq : 59|2@0+ (1,0) [0|3] "SED"  GWM
 SG_ PoliceIdlMde_D_Stat : 55|4@0+ (1,0) [0|15] "SED"  GWM
 SG_ DrLatchMsgTxt_D_Rq : 43|3@0+ (1,0) [0|7] "SED"  GWM
 SG_ HazrdLght_B_Stat : 56|1@0+ (1,0) [0|1] "SED"  GWM
 SG_ SecurityMsgTxt_D_Rq : 47|2@0+ (1,0) [0|3] "SED"  GWM
 SG_ PrmtrAlrmEvnt_D_Stat : 35|4@0+ (1,0) [0|15] "SED"  GWM
 SG_ HeadLghtHiPrmsn_D_Stat : 51|2@0+ (1,0) [0|3] "SED"  GWM
 SG_ SteWhlLckMsgTxt_D_Rq : 25|2@0+ (1,0) [0|3] "SED"  GWM
 SG_ immoMsgTxt_D_Rq : 39|4@0+ (1,0) [0|15] "SED"  GWM
 SG_ PrsnlDevcChrgEnbl_B_Rq : 40|1@0+ (1,0) [0|1] "SED"  GWM
 SG_ TracKeyMde_D_Stat : 45|2@0+ (1,0) [0|3] "SED"  GWM
 SG_ PEBackupSlot_Stats : 27|2@0+ (1,0) [0|3] "SED"  GWM
 SG_ KeyMykeyTot_No_Cnt : 3|4@0+ (1,0) [0|15] "Counts"  GWM
 SG_ Keycode_Status : 15|20@0+ (1,0) [0|1048575] "unitless"  GWM
 SG_ KeyAdmnTot_No_Cnt : 7|4@0+ (1,0) [0|15] "Counts"  GWM

BO_ 936 ParkAid_Data_HS1: 8 GWM
 SG_ ApaButtnPrssd_B_Stat : 58|1@0+ (1,0) [0|1] "SED"  GENERIC
 SG_ ApaSys_D_Stat : 61|3@0+ (1,0) [0|7] "SED" Vector__XXX
 SG_ ApaSteWhl_D_RqDrv : 63|2@0+ (1,0) [0|3] "SED"  GENERIC
 SG_ ApaSteScanMde_D_Stat : 49|2@0+ (1,0) [0|3] "SED"  BCM
 SG_ ApaSelSapp_D_Stat : 51|2@0+ (1,0) [0|3] "SED"  GENERIC
 SG_ ApaSelPpa_D_Stat : 53|2@0+ (1,0) [0|3] "SED"  GENERIC
 SG_ ApaSelPoa_D_Stat : 55|2@0+ (1,0) [0|3] "SED"  GENERIC
 SG_ ApaScan_D_Stat : 41|2@0+ (1,0) [0|3] "SED"  GENERIC
 SG_ ApaLongCtl_D_RqDrv : 44|3@0+ (1,0) [0|7] "SED"  GENERIC
 SG_ ApaGearShif_D_RqDrv : 47|3@0+ (1,0) [0|7] "SED"  GENERIC
 SG_ ApaActvSide2_D_Stat : 33|2@0+ (1,0) [0|3] "SED"  GENERIC
 SG_ ApaAcsy_D_RqDrv : 36|3@0+ (1,0) [0|7] "SED"  GENERIC
 SG_ ApaTrgtDist_D_Stat : 11|4@0+ (1,0) [0|15] "SED"  GENERIC
 SG_ ApaMsgTxt_D_Rq : 15|4@0+ (1,0) [0|15] "SED"  GENERIC
 SG_ ApaChime_D_Rq : 39|3@0+ (1,0) [0|7] "SED"  GENERIC
 SG_ SAPPStatusCoding : 7|8@0+ (1,0) [0|255] "unitless"  BCM
 SG_ EPASExtAngleStatReq : 23|1@0+ (1,0) [0|1] "SED"  BCM
 SG_ ExtSteeringAngleReq2 : 22|15@0+ (0.1,-1000) [-1000|2276.5] "Degrees"  GENERIC

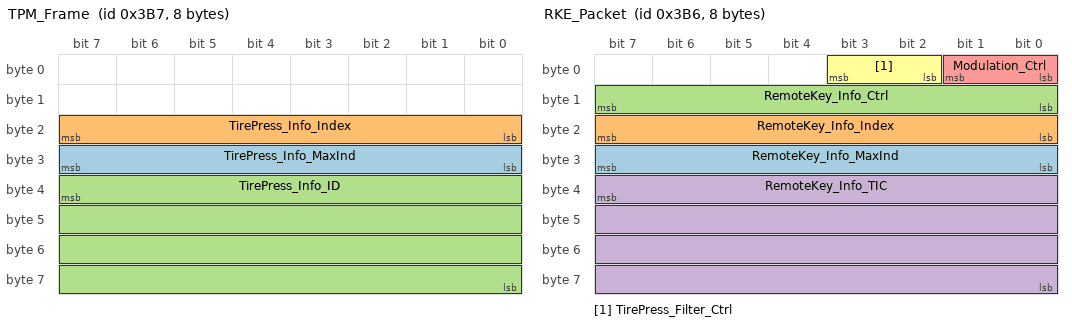
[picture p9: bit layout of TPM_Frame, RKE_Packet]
BO_ 951 TPM_Frame: 8 BCM
 SG_ TirePress_Info_MaxInd : 31|8@0+ (1,0) [0|255] "Unitless"  GWM
 SG_ TirePress_Info_Index : 23|8@0+ (1,0) [0|255] "Unitless"  GWM
 SG_ TirePress_Info_ID : 39|32@0+ (1,0) [0|4294967295] "Unitless"  GWM

BO_ 950 RKE_Packet: 8 BCM
 SG_ RemoteKey_Info_MaxInd : 31|8@0+ (1,0) [0|255] "Unitless"  GWM
 SG_ RemoteKey_Info_Index : 23|8@0+ (1,0) [0|255] "Unitless"  GWM
 SG_ RemoteKey_Info_Ctrl : 15|8@0+ (1,0) [0|255] "Unitless"  GWM
 SG_ RemoteKey_Info_TIC : 39|32@0+ (1,0) [0|4294967295] "Unitless"  GWM
 SG_ Modulation_Ctrl : 1|2@0+ (1,0) [0|3] "SED"  GWM
 SG_ TirePress_Filter_Ctrl : 3|2@0+ (1,0) [0|3] "SED"  GWM

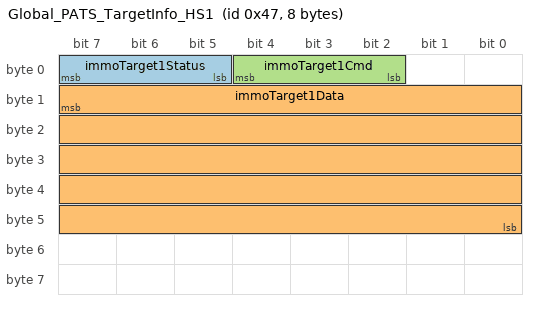
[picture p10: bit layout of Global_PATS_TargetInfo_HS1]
BO_ 71 Global_PATS_TargetInfo_HS1: 8 GWM
 SG_ immoTarget1Status : 7|3@0+ (1,0) [0|7] "SED"  BCM
 SG_ immoTarget1Data : 15|40@0+ (1,0) [0|1099511627775] "Encrypted"  BCM
 SG_ immoTarget1Cmd : 4|3@0+ (1,0) [0|7] "SED"  BCM

CM_ SG_ 1069 SlMde_D_Stat "IPC and HUD_ADV Receve from HS3 FGW 0x42D, not HS3 0x38A, MSG DCR 506.";
CM_ SG_ 1069 SlMde_D_RqDsply "IPC and HUD_ADV Receve from HS3 FGW 0x42D, not HS3 0x38A, MSG DCR 506.";
CM_ SG_ 1069 ObdWarmUp_B_Complt "Signal not transmitted on gas and diesel variants.";
CM_ SG_ 1069 EngMsgTxt_D_Rq "Signal not transmitted on diesel variants.";
CM_ SG_ 1069 EngClnt_Te_ActlDiag "Signal not transmitted on gas variants.";
CM_ SG_ 1069 EngLoad_Pc_CalcDiag "Signal not transmitted on gas variants.";
CM_ SG_ 1069 ApedPos_Pc_ActlDiag "Signal not transmitted on gas variants.";
CM_ BO_ 1200 "DCR 1836 to update Tx from GWM to EP100ms rejected due MPS6 TCM requires BrkTot_Tq_RqDrv at 20ms (bshu1).";
CM_ SG_ 1200 BrkTot_Tq_RqDrv "DCR 1836 to update Tx from GWM to EP100ms rejected due MPS6 TCM requires BrkTot_Tq_RqDrv at 20ms (bshu1).";
CM_ BO_ 2015 "OBDII Request ($7DF) messages are for FNOS 1.0.1 only.
Diagnostic Functional Addressing ($7DF) and Dual Rate Periodic messages are for FNOS I3 only.";
CM_ SG_ 376 EngAout_Aa_Actl "Signal not transmitted on HEV variants.";
CM_ SG_ 516 EngAout3_N_Actl "Signal not transmitted on gas and diesel variants.";
CM_ SG_ 516 ApedPosPcActl_No_Cnt "Signal not transmitted on gas and diesel variants.";
CM_ SG_ 516 ApedPosPcActl_No_Cs "Signal not transmitted on gas and diesel variants.";
CM_ SG_ 377 EngFuelCutFull_B_Inhbt "Signal not transmitted on diesel variants.";
CM_ SG_ 377 FuelFlw_Vl_Dsply "Signal not transmitted on diesel variants.";
CM_ SG_ 377 FuelFillInlet_B_Dsply "Signal not transmitted on diesel variants.";
CM_ SG_ 377 OdoCount "Signal not transmitted on diesel variants.";
CM_ SG_ 377 EngOilLife_Pc_Actl "Signal not transmitted on diesel variants.";
CM_ SG_ 377 TrnKickDown_B_RqDrv "Signal not transmitted on diesel variants.";
CM_ SG_ 377 AirCondRec_B_Rq "Signal not transmitted on diesel variants.";
CM_ SG_ 377 AirCondClutch_B_Stats "Signal not transmitted on diesel variants.";
CM_ BO_ 967 "2008' programs, Tx by IC;  updated on 5/6/05";
CM_ BO_ 949 "For 2010MY and beyond, use for SCT (non-CGEA) and CGEA modules";
CM_ BO_ 948 "$3B4 used by CGEA SPDJB";
CM_ SG_ 1077 PtWakeupActv1_B_Rq "ECG Application signal";
CM_ SG_ 1077 PtWakeupActv1_B_Rq_UB "ECG Application signal";
CM_ SG_ 342 EngOvrhtMitgActv_D_Ind "Signal not transmitted on diesel.";
CM_ SG_ 342 EngGoutLss_Tq_Est "Signal not transmitted on gas and diesel variants.";
CM_ BO_ 65 "Provide control function information to the target function of the Passive Anti-Theft Subsystem";
CM_ BO_ 66 "Provide control function information to the target function of the Passive Anti-Theft Subsystem";
CM_ SG_ 66 immoControlData_T2 "Not transmitted on all vehicle variants";
CM_ SG_ 66 immoControlCmd_T2 "Not transmitted on all vehicle variants";
CM_ BO_ 560 "MHT (U611/625) the HPCM will Rx 0x230 from the PCM_HEV
Powersplit FWD HEV’s (Cx482/3 430) the HPCM will Tx 0x230";
CM_ SG_ 560 SelDrvMdeSwtch_D_Stat3 "ECM_HEV does not support or Transmit signal.";
CM_ SG_ 560 GearLvrPosActl_No_Cs "Signal not transmitted on Gas & HEV variants. MHT(U611/625) HPCM Rx 0x230 from PCM_HEV. Powersplit FWD HEV’s(Cx482/3 430) HPCM Tx 0x230.";
CM_ SG_ 560 GearLvrPosActl_No_Cnt "Signal not transmitted on Gas & HEV variants. MHT(U611/625) HPCM Rx 0x230 from PCM_HEV. Powersplit FWD HEV’s(Cx482/3 430) HPCM Tx 0x230.";
CM_ SG_ 560 TrnGbox_Rt_Actl "Signal not transmitted on Gas & HEV variants. MHT(U611/625) HPCM Rx 0x230 from PCM_HEV. Powersplit FWD HEV’s(Cx482/3 430) HPCM Tx 0x230.";
CM_ SG_ 560 TrnSrvcRqd_B_Rq "Signal not transmitted on Diesel & HEV variants. MHT(U611/625) HPCM Rx 0x230 from PCM_HEV. Powersplit FWD HEV’s(Cx482/3 430) HPCM Tx 0x230.";
CM_ SG_ 560 TrnCnvtClu_D_Actl "Signal not transmitted on Gas & HEV variants. MHT(U611/625) HPCM Rx 0x230 from PCM_HEV. Powersplit FWD HEV’s(Cx482/3 430) HPCM Tx 0x230.";
CM_ SG_ 560 TrnShifActv_B_Actl "Signal not transmitted on HEV variants. MHT(U611/625) HPCM Rx 0x230 from PCM_HEV. Powersplit FWD HEV’s(Cx482/3 430) HPCM Tx 0x230.";
CM_ SG_ 560 GboxOil_Te_Actl "Signal not transmitted on HEV variants. MHT(U611/625) HPCM Rx 0x230 from PCM_HEV. Powersplit FWD HEV’s(Cx482/3 430) HPCM Tx 0x230.";
CM_ SG_ 1034 VehicleGGCCData "RCMGenSigTimeout=6000";
CM_ SG_ 947 Dimming_Lvl "Refer to Vehicle Interior Illum Dimming Ctrl Sys Eng Spec, Table 2

";
CM_ SG_ 947 PrkBrkActv_B_Actl "Signal not transmitted on vehicles with electric park brake. ";
CM_ BO_ 71 "Provide target function info. to control function of PATS";
BA_DEF_ BO_  "FrameRouting" STRING ;
BA_DEF_ BO_  "FrameGatewayNetwork" STRING ;
BA_DEF_ BO_  "NetworkInitialization" ENUM  "No","Yes";
BA_DEF_ BO_  "FrameGatewayId" HEX 0 1407;
BA_DEF_ BO_  "EventRateOfChange" INT 10 10000;
BA_DEF_ BO_  "GenMsgStartDelayTime" INT 0 10000;
BA_DEF_ BO_  "GenMsgNrOfRepetition" INT 0 100;
BA_DEF_ BO_  "GenMsgDelayTime" INT 0 1000;
BA_DEF_ BO_  "GenMsgCycleTime" INT 0 100000;
BA_DEF_ BO_  "GenMsgSendType" ENUM  "FixedPeriodic","Event","EnabledPeriodic","NotUsed","NotUsed","EventPeriodic","NotUsed","NotUsed","NoMsgSendType";
BA_DEF_ SG_  "U_CD764_MY2022_Tx" ENUM  "No","Yes";
BA_DEF_ SG_  "U_U55X_MY2022_Tx" ENUM  "No","Yes";
BA_DEF_ SG_  "U_CD542_MY2021_Tx" ENUM  "No","Yes";
BA_DEF_ SG_  "ECGUsedTxSignal" ENUM  "No","Yes";
BA_DEF_ SG_  "U_T6_MCA_MY2020_Tx" ENUM  "No","Yes";
BA_DEF_ SG_  "U_P702_MY2021_Tx" ENUM  "No","Yes";
BA_DEF_ SG_  "U_CX727_MY2021_Tx" ENUM  "No","Yes";
BA_DEF_ SG_  "U_CD764_MY2022_Rx" ENUM  "No","Yes";
BA_DEF_ SG_  "U_U55X_MY2022_Rx" ENUM  "No","Yes";
BA_DEF_ SG_  "U_CD542_MY2021_Rx" ENUM  "No","Yes";
BA_DEF_ SG_  "ECGUsedRxSignal" ENUM  "No","Yes";
BA_DEF_ SG_  "U_T6_MCA_MY2020_Rx" ENUM  "No","Yes";
BA_DEF_ SG_  "U_P702_MY2021_Rx" ENUM  "No","Yes";
BA_DEF_ SG_  "U_CX727_MY2021_Rx" ENUM  "No","Yes";
BA_DEF_ SG_  "GenSigStartValue" HEX 0 268435455;
BA_DEF_ SG_  "MetaData" ENUM  "No","Yes";
BA_DEF_ SG_  "ContentDependant" ENUM  "No","Yes";
BA_DEF_ SG_  "GenSigStartValueInteger" INT 0 1000000000;
BA_DEF_ SG_  "UsedOnPgmDBC" ENUM  "No","Yes";
BA_DEF_ SG_  "WakeupSignal" ENUM  "No","Yes";
BA_DEF_ SG_  "GenSigInactiveValue" INT 0 100000;
BA_DEF_ SG_  "GenSigSendType" ENUM  "Cyclic","OnWrite","vector_leerstring","OnChange","vector_leerstring","IfActive","vector_leerstring","NoSigSendType";
BA_DEF_ BO_  "OvtpPushApplication" ENUM  "FALSE","TRUE";
BA_DEF_ BO_  "SCP_FreshnessValueLength" INT 0 512;
BA_DEF_ BO_  "SCP_FreshnessValueTxLength" INT 0 512;
BA_DEF_ BO_  "SCP_AuthInfoTxLength" INT 0 512;
BA_DEF_ BO_  "GenMsgRoutingTimeoutTime" INT 0 5000;
BA_DEF_ BO_  "MessageGateway" ENUM  "No","Yes";
BA_DEF_ BO_  "NmAsrMessage" ENUM  "No","Yes";
BA_DEF_ BO_  "TpApplType" STRING ;
BA_DEF_ BO_  "DiagState" ENUM  "No","Yes";
BA_DEF_ BO_  "TpTxIndex" INT 0 536870911;
BA_DEF_ BO_  "DiagRequest" ENUM  "No","Yes";
BA_DEF_ BO_  "DiagResponse" ENUM  "No","Yes";
BA_DEF_ BO_  "GenMsgILSupport" ENUM  "No","Yes";
BA_DEF_DEF_  "FrameRouting" "";
BA_DEF_DEF_  "FrameGatewayNetwork" "NONE";
BA_DEF_DEF_  "NetworkInitialization" "Yes";
BA_DEF_DEF_  "FrameGatewayId" 0;
BA_DEF_DEF_  "EventRateOfChange" 10000;
BA_DEF_DEF_  "GenMsgStartDelayTime" 0;
BA_DEF_DEF_  "GenMsgNrOfRepetition" 1;
BA_DEF_DEF_  "GenMsgDelayTime" 20;
BA_DEF_DEF_  "GenMsgCycleTime" 0;
BA_DEF_DEF_  "GenMsgSendType" "NoMsgSendType";
BA_DEF_DEF_  "U_CD764_MY2022_Tx" "No";
BA_DEF_DEF_  "U_U55X_MY2022_Tx" "No";
BA_DEF_DEF_  "U_CD542_MY2021_Tx" "No";
BA_DEF_DEF_  "ECGUsedTxSignal" "No";
BA_DEF_DEF_  "U_T6_MCA_MY2020_Tx" "No";
BA_DEF_DEF_  "U_P702_MY2021_Tx" "No";
BA_DEF_DEF_  "U_CX727_MY2021_Tx" "No";
BA_DEF_DEF_  "U_CD764_MY2022_Rx" "No";
BA_DEF_DEF_  "U_U55X_MY2022_Rx" "No";
BA_DEF_DEF_  "U_CD542_MY2021_Rx" "No";
BA_DEF_DEF_  "ECGUsedRxSignal" "No";
BA_DEF_DEF_  "U_T6_MCA_MY2020_Rx" "No";
BA_DEF_DEF_  "U_P702_MY2021_Rx" "No";
BA_DEF_DEF_  "U_CX727_MY2021_Rx" "No";
BA_DEF_DEF_  "GenSigStartValue" 0;
BA_DEF_DEF_  "MetaData" "No";
BA_DEF_DEF_  "ContentDependant" "No";
BA_DEF_DEF_  "GenSigStartValueInteger" 0;
BA_DEF_DEF_  "UsedOnPgmDBC" "Yes";
BA_DEF_DEF_  "WakeupSignal" "No";
BA_DEF_DEF_  "GenSigInactiveValue" 0;
BA_DEF_DEF_  "GenSigSendType" "NoSigSendType";
BA_DEF_DEF_  "OvtpPushApplication" "FALSE";
BA_DEF_DEF_  "SCP_FreshnessValueLength" 64;
BA_DEF_DEF_  "SCP_FreshnessValueTxLength" 11;
BA_DEF_DEF_  "SCP_AuthInfoTxLength" 53;
BA_DEF_DEF_  "GenMsgRoutingTimeoutTime" 0;
BA_DEF_DEF_  "MessageGateway" "No";
BA_DEF_DEF_  "NmAsrMessage" "No";
BA_DEF_DEF_  "TpApplType" "";
BA_DEF_DEF_  "DiagState" "No";
BA_DEF_DEF_  "TpTxIndex" 0;
BA_DEF_DEF_  "DiagRequest" "No";
BA_DEF_DEF_  "DiagResponse" "No";
BA_DEF_DEF_  "GenMsgILSupport" "Yes";
BA_ "FrameGatewayId" BO_ 1069 1069;
BA_ "FrameGatewayNetwork" BO_ 1069 "FD1_CAN";
BA_ "FrameRouting" BO_ 1069 "FD1_CAN,0x42D;";
BA_ "FrameGatewayId" BO_ 878 878;
BA_ "FrameGatewayNetwork" BO_ 878 "FD1_CAN";
BA_ "FrameRouting" BO_ 878 "FD1_CAN,0x36E;";
BA_ "GenMsgDelayTime" BO_ 1200 10;
BA_ "FrameGatewayId" BO_ 1200 1200;
BA_ "FrameGatewayNetwork" BO_ 1200 "FD1_CAN";
BA_ "FrameRouting" BO_ 1200 "FD1_CAN,0x4B0;";
BA_ "GenMsgILSupport" BO_ 2015 0;
BA_ "DiagState" BO_ 2015 1;
BA_ "GenMsgSendType" BO_ 2015 1;
BA_ "GenMsgDelayTime" BO_ 2015 0;
BA_ "NetworkInitialization" BO_ 2015 0;
BA_ "FrameGatewayId" BO_ 376 376;
BA_ "FrameGatewayNetwork" BO_ 376 "FD1_CAN";
BA_ "FrameRouting" BO_ 376 "FD1_CAN,0x178;";
BA_ "FrameGatewayId" BO_ 516 516;
BA_ "FrameGatewayNetwork" BO_ 516 "FD1_CAN";
BA_ "FrameRouting" BO_ 516 "FD1_CAN,0x204;";
BA_ "FrameGatewayId" BO_ 377 377;
BA_ "FrameGatewayNetwork" BO_ 377 "FD1_CAN";
BA_ "FrameRouting" BO_ 377 "FD1_CAN,0x179;";
BA_ "GenMsgDelayTime" BO_ 76 10;
BA_ "FrameGatewayId" BO_ 76 76;
BA_ "FrameGatewayNetwork" BO_ 76 "HS2_CAN";
BA_ "FrameRouting" BO_ 76 "HS2_CAN,0x4C;";
BA_ "GenMsgILSupport" BO_ 1870 0;
BA_ "DiagResponse" BO_ 1870 1;
BA_ "GenMsgSendType" BO_ 1870 1;
BA_ "GenMsgDelayTime" BO_ 1870 0;
BA_ "NetworkInitialization" BO_ 1870 0;
BA_ "GenMsgILSupport" BO_ 1862 0;
BA_ "DiagRequest" BO_ 1862 1;
BA_ "GenMsgSendType" BO_ 1862 1;
BA_ "GenMsgDelayTime" BO_ 1862 0;
BA_ "NetworkInitialization" BO_ 1862 0;
BA_ "GenMsgSendType" BO_ 967 5;
BA_ "GenMsgCycleTime" BO_ 967 1000;
BA_ "GenMsgStartDelayTime" BO_ 967 80;
BA_ "GenMsgSendType" BO_ 949 0;
BA_ "GenMsgCycleTime" BO_ 949 500;
BA_ "GenMsgStartDelayTime" BO_ 949 60;
BA_ "GenMsgSendType" BO_ 948 5;
BA_ "GenMsgCycleTime" BO_ 948 1000;
BA_ "GenMsgStartDelayTime" BO_ 948 50;
BA_ "GenMsgSendType" BO_ 1077 5;
BA_ "GenMsgCycleTime" BO_ 1077 100;
BA_ "FrameGatewayId" BO_ 862 862;
BA_ "FrameGatewayNetwork" BO_ 862 "MS1_CAN";
BA_ "FrameRouting" BO_ 862 "MS1_CAN,0x35E;";
BA_ "FrameGatewayId" BO_ 342 342;
BA_ "FrameGatewayNetwork" BO_ 342 "FD1_CAN";
BA_ "FrameRouting" BO_ 342 "FD1_CAN,0x156;";
BA_ "FrameGatewayId" BO_ 992 992;
BA_ "FrameGatewayNetwork" BO_ 992 "HS3_CAN";
BA_ "FrameRouting" BO_ 992 "HS3_CAN,0x3E0;";
BA_ "FrameGatewayId" BO_ 994 994;
BA_ "FrameGatewayNetwork" BO_ 994 "HS3_CAN";
BA_ "FrameRouting" BO_ 994 "HS3_CAN,0x3E2;";
BA_ "GenMsgSendType" BO_ 65 0;
BA_ "GenMsgCycleTime" BO_ 65 20;
BA_ "GenMsgDelayTime" BO_ 65 10;
BA_ "GenMsgSendType" BO_ 66 0;
BA_ "GenMsgCycleTime" BO_ 66 20;
BA_ "GenMsgDelayTime" BO_ 66 10;
BA_ "GenMsgILSupport" BO_ 1838 0;
BA_ "DiagResponse" BO_ 1838 1;
BA_ "GenMsgSendType" BO_ 1838 1;
BA_ "GenMsgDelayTime" BO_ 1838 0;
BA_ "NetworkInitialization" BO_ 1838 0;
BA_ "GenMsgILSupport" BO_ 1830 0;
BA_ "DiagRequest" BO_ 1830 1;
BA_ "GenMsgSendType" BO_ 1830 1;
BA_ "GenMsgDelayTime" BO_ 1830 0;
BA_ "NetworkInitialization" BO_ 1830 0;
BA_ "FrameGatewayId" BO_ 560 560;
BA_ "FrameGatewayNetwork" BO_ 560 "FD1_CAN";
BA_ "FrameRouting" BO_ 560 "FD1_CAN,0x230;";
BA_ "FrameGatewayId" BO_ 357 357;
BA_ "FrameGatewayNetwork" BO_ 357 "FD1_CAN";
BA_ "FrameRouting" BO_ 357 "FD1_CAN,0x165;";
BA_ "GenMsgSendType" BO_ 1003 5;
BA_ "GenMsgCycleTime" BO_ 1003 1000;
BA_ "GenMsgSendType" BO_ 1034 0;
BA_ "GenMsgCycleTime" BO_ 1034 200;
BA_ "GenMsgSendType" BO_ 1068 0;
BA_ "GenMsgCycleTime" BO_ 1068 50;
BA_ "GenMsgSendType" BO_ 947 5;
BA_ "GenMsgCycleTime" BO_ 947 500;
BA_ "GenMsgStartDelayTime" BO_ 947 100;
BA_ "FrameGatewayId" BO_ 986 986;
BA_ "FrameGatewayNetwork" BO_ 986 "HS3_CAN";
BA_ "FrameRouting" BO_ 986 "HS3_CAN,0x3DA;";
BA_ "GenMsgSendType" BO_ 995 5;
BA_ "GenMsgCycleTime" BO_ 995 1000;
BA_ "GenMsgSendType" BO_ 963 5;
BA_ "GenMsgCycleTime" BO_ 963 1000;
BA_ "GenMsgStartDelayTime" BO_ 963 100;
BA_ "GenMsgSendType" BO_ 909 5;
BA_ "GenMsgCycleTime" BO_ 909 1000;
BA_ "FrameRouting" BO_ 936 "FD1_CAN,0x3A8;";
BA_ "GenMsgSendType" BO_ 951 0;
BA_ "GenMsgCycleTime" BO_ 951 250;
BA_ "GenMsgSendType" BO_ 950 5;
BA_ "GenMsgCycleTime" BO_ 950 250;
BA_ "FrameGatewayId" BO_ 71 71;
BA_ "FrameGatewayNetwork" BO_ 71 "FD1_CAN";
BA_ "FrameRouting" BO_ 71 "FD1_CAN,0x47;";
BA_ "WakeupSignal" SG_ 1069 ReFuelSysStat_D_Dsply 1;
BA_ "U_CD542_MY2021_Rx" SG_ 1069 ULoSrcOnPlg_B_Cmd 1;
BA_ "U_CX727_MY2021_Rx" SG_ 1069 ULoSrcOnPlg_B_Cmd 1;
BA_ "U_CX727_MY2021_Rx" SG_ 1069 GrllShtrPos_D_Cmd 1;
BA_ "U_P702_MY2021_Rx" SG_ 1069 GrllShtrPos_D_Cmd 1;
BA_ "U_T6_MCA_MY2020_Rx" SG_ 1069 GrllShtrPos_D_Cmd 1;
BA_ "U_CD542_MY2021_Rx" SG_ 1069 GrllShtrPos_D_Cmd 1;
BA_ "U_U55X_MY2022_Rx" SG_ 1069 GrllShtrPos_D_Cmd 1;
BA_ "U_CD764_MY2022_Rx" SG_ 1069 GrllShtrPos_D_Cmd 1;
BA_ "U_CX727_MY2021_Rx" SG_ 1069 GrllShtrPos_B_Falt 1;
BA_ "U_P702_MY2021_Rx" SG_ 1069 GrllShtrPos_B_Falt 1;
BA_ "U_T6_MCA_MY2020_Rx" SG_ 1069 GrllShtrPos_B_Falt 1;
BA_ "U_CD542_MY2021_Rx" SG_ 1069 GrllShtrPos_B_Falt 1;
BA_ "U_U55X_MY2022_Rx" SG_ 1069 GrllShtrPos_B_Falt 1;
BA_ "U_CD764_MY2022_Rx" SG_ 1069 GrllShtrPos_B_Falt 1;
BA_ "ContentDependant" SG_ 1069 ObdWarmUp_B_Complt 1;
BA_ "U_CX727_MY2021_Rx" SG_ 1069 ObdWarmUp_B_Complt 1;
BA_ "U_P702_MY2021_Rx" SG_ 1069 ObdWarmUp_B_Complt 1;
BA_ "U_CD542_MY2021_Rx" SG_ 1069 ObdWarmUp_B_Complt 1;
BA_ "ContentDependant" SG_ 1069 EngMsgTxt_D_Rq 1;
BA_ "ContentDependant" SG_ 1069 EngClnt_Te_ActlDiag 1;
BA_ "U_CX727_MY2021_Rx" SG_ 1069 EngClnt_Te_ActlDiag 1;
BA_ "U_P702_MY2021_Rx" SG_ 1069 EngClnt_Te_ActlDiag 1;
BA_ "U_CD542_MY2021_Rx" SG_ 1069 EngClnt_Te_ActlDiag 1;
BA_ "ContentDependant" SG_ 1069 EngLoad_Pc_CalcDiag 1;
BA_ "U_CX727_MY2021_Rx" SG_ 1069 EngLoad_Pc_CalcDiag 1;
BA_ "U_P702_MY2021_Rx" SG_ 1069 EngLoad_Pc_CalcDiag 1;
BA_ "U_CD542_MY2021_Rx" SG_ 1069 EngLoad_Pc_CalcDiag 1;
BA_ "U_CX727_MY2021_Rx" SG_ 1069 EngAirIn_Te_Actl 1;
BA_ "U_P702_MY2021_Rx" SG_ 1069 EngAirIn_Te_Actl 1;
BA_ "U_T6_MCA_MY2020_Rx" SG_ 1069 EngAirIn_Te_Actl 1;
BA_ "U_CD542_MY2021_Rx" SG_ 1069 EngAirIn_Te_Actl 1;
BA_ "U_U55X_MY2022_Rx" SG_ 1069 EngAirIn_Te_Actl 1;
BA_ "U_CD764_MY2022_Rx" SG_ 1069 EngAirIn_Te_Actl 1;
BA_ "ContentDependant" SG_ 1069 ApedPos_Pc_ActlDiag 1;
BA_ "U_CX727_MY2021_Rx" SG_ 1069 ApedPos_Pc_ActlDiag 1;
BA_ "U_P702_MY2021_Rx" SG_ 1069 ApedPos_Pc_ActlDiag 1;
BA_ "U_CD542_MY2021_Rx" SG_ 1069 ApedPos_Pc_ActlDiag 1;
BA_ "GenSigStartValueInteger" SG_ 878 DcacHw_D_Confg 1;
BA_ "GenSigStartValueInteger" SG_ 878 DcacFaltMsgTxt_D_Rq 1;
BA_ "U_T6_MCA_MY2020_Rx" SG_ 878 DcacFaltMsgTxt_D_Rq 1;
BA_ "U_U55X_MY2022_Rx" SG_ 878 DcacFaltMsgTxt_D_Rq 1;
BA_ "GenSigStartValueInteger" SG_ 878 DcacElPw_D_Stat 1;
BA_ "GenSigStartValue" SG_ 878 DcacElPw_D_Stat 1;
BA_ "U_T6_MCA_MY2020_Rx" SG_ 878 DcacElPw_D_Stat 1;
BA_ "U_U55X_MY2022_Rx" SG_ 878 DcacElPw_D_Stat 1;
BA_ "U_P702_MY2021_Rx" SG_ 878 DcacOn_B_Rq 1;
BA_ "U_T6_MCA_MY2020_Rx" SG_ 878 DcacSys_B_Falt 1;
BA_ "U_U55X_MY2022_Rx" SG_ 878 DcacSys_B_Falt 1;
BA_ "U_P702_MY2021_Rx" SG_ 878 DcacSys_B_Falt 1;
BA_ "U_P702_MY2021_Rx" SG_ 878 DcacLedCtl_D_Rq 1;
BA_ "U_U55X_MY2022_Rx" SG_ 1200 BrkHold_D_Stat 1;
BA_ "GenSigStartValueInteger" SG_ 1200 HsaTrnAout_Tq_Rq 32768;
BA_ "GenSigStartValueInteger" SG_ 1200 BrkBstrVac_P_Actl 127;
BA_ "GenSigStartValue" SG_ 1200 BrkBstrVac_P_Actl 127;
BA_ "GenSigStartValueInteger" SG_ 1200 YawStabilityIndex 256;
BA_ "U_U55X_MY2022_Rx" SG_ 1200 BrkTot_Tq_RqDrv 1;
BA_ "MetaData" SG_ 1200 BrkTotTqRqDrv_No_Cnt 1;
BA_ "U_U55X_MY2022_Rx" SG_ 1200 BrkTotTqRqDrv_No_Cnt 1;
BA_ "MetaData" SG_ 1200 BrkTotTqRqDrv_No_Cs 1;
BA_ "U_U55X_MY2022_Rx" SG_ 1200 BrkTotTqRqDrv_No_Cs 1;
BA_ "GenSigSendType" SG_ 2015 TesterFunctionalReq 3;
BA_ "U_CX727_MY2021_Rx" SG_ 2015 TesterFunctionalReq 1;
BA_ "U_P702_MY2021_Rx" SG_ 2015 TesterFunctionalReq 1;
BA_ "U_T6_MCA_MY2020_Rx" SG_ 2015 TesterFunctionalReq 1;
BA_ "U_CD542_MY2021_Rx" SG_ 2015 TesterFunctionalReq 1;
BA_ "U_U55X_MY2022_Rx" SG_ 2015 TesterFunctionalReq 1;
BA_ "U_CD764_MY2022_Rx" SG_ 2015 TesterFunctionalReq 1;
BA_ "ECGUsedRxSignal" SG_ 2015 TesterFunctionalReq 1;
BA_ "ContentDependant" SG_ 376 EngAout_Aa_Actl 1;
BA_ "GenSigStartValueInteger" SG_ 376 HvacHtrCore2_Te_Actl 200;
BA_ "GenSigStartValueInteger" SG_ 376 AirAmbTe_D_Qf 1;
BA_ "MetaData" SG_ 376 AirAmbTe_D_Qf 1;
BA_ "GenSigStartValue" SG_ 376 AirAmbTe_D_Qf 1;
BA_ "U_CX727_MY2021_Rx" SG_ 376 AirAmbTe_D_Qf 1;
BA_ "U_P702_MY2021_Rx" SG_ 376 AirAmbTe_D_Qf 1;
BA_ "U_T6_MCA_MY2020_Rx" SG_ 376 AirAmbTe_D_Qf 1;
BA_ "U_CD542_MY2021_Rx" SG_ 376 AirAmbTe_D_Qf 1;
BA_ "U_U55X_MY2022_Rx" SG_ 376 AirAmbTe_D_Qf 1;
BA_ "U_CD764_MY2022_Rx" SG_ 376 AirAmbTe_D_Qf 1;
BA_ "GenSigStartValueInteger" SG_ 376 AirAmb_Te_ActlFilt 512;
BA_ "U_CX727_MY2021_Rx" SG_ 376 AirAmb_Te_ActlFilt 1;
BA_ "U_P702_MY2021_Rx" SG_ 376 AirAmb_Te_ActlFilt 1;
BA_ "U_T6_MCA_MY2020_Rx" SG_ 376 AirAmb_Te_ActlFilt 1;
BA_ "U_CD542_MY2021_Rx" SG_ 376 AirAmb_Te_ActlFilt 1;
BA_ "U_U55X_MY2022_Rx" SG_ 376 AirAmb_Te_ActlFilt 1;
BA_ "U_CD764_MY2022_Rx" SG_ 376 AirAmb_Te_ActlFilt 1;
BA_ "ECGUsedRxSignal" SG_ 376 AirAmb_Te_ActlFilt 1;
BA_ "GenSigStartValueInteger" SG_ 376 AirAmb_Te_Actl 512;
BA_ "U_CX727_MY2021_Rx" SG_ 376 AirAmb_Te_Actl 1;
BA_ "U_CD542_MY2021_Rx" SG_ 376 AirAmb_Te_Actl 1;
BA_ "U_U55X_MY2022_Rx" SG_ 376 AirAmb_Te_Actl 1;
BA_ "U_CD764_MY2022_Rx" SG_ 376 AirAmb_Te_Actl 1;
BA_ "U_P702_MY2021_Rx" SG_ 376 AirAmb_Te_Actl 1;
BA_ "U_CX727_MY2021_Rx" SG_ 376 AirAmb_P_Actl 1;
BA_ "U_P702_MY2021_Rx" SG_ 376 AirAmb_P_Actl 1;
BA_ "U_T6_MCA_MY2020_Rx" SG_ 376 AirAmb_P_Actl 1;
BA_ "U_CD542_MY2021_Rx" SG_ 376 AirAmb_P_Actl 1;
BA_ "U_U55X_MY2022_Rx" SG_ 376 AirAmb_P_Actl 1;
BA_ "U_CD764_MY2022_Rx" SG_ 376 AirAmb_P_Actl 1;
BA_ "GenSigStartValueInteger" SG_ 516 EngAoutNActl_D_QF 1;
BA_ "MetaData" SG_ 516 EngAoutNActl_D_QF 1;
BA_ "GenSigStartValue" SG_ 516 EngAoutNActl_D_QF 1;
BA_ "ContentDependant" SG_ 516 EngAout3_N_Actl 1;
BA_ "U_CX727_MY2021_Rx" SG_ 516 EngAout3_N_Actl 1;
BA_ "U_CX727_MY2021_Rx" SG_ 516 ApedPos_Pc_ActlArb 1;
BA_ "U_P702_MY2021_Rx" SG_ 516 ApedPos_Pc_ActlArb 1;
BA_ "U_T6_MCA_MY2020_Rx" SG_ 516 ApedPos_Pc_ActlArb 1;
BA_ "U_CD542_MY2021_Rx" SG_ 516 ApedPos_Pc_ActlArb 1;
BA_ "U_U55X_MY2022_Rx" SG_ 516 ApedPos_Pc_ActlArb 1;
BA_ "U_CD764_MY2022_Rx" SG_ 516 ApedPos_Pc_ActlArb 1;
BA_ "GenSigStartValueInteger" SG_ 516 ApedPosPcActl_D_Qf 1;
BA_ "MetaData" SG_ 516 ApedPosPcActl_D_Qf 1;
BA_ "GenSigStartValue" SG_ 516 ApedPosPcActl_D_Qf 1;
BA_ "U_CX727_MY2021_Rx" SG_ 516 EngAout_N_Actl 1;
BA_ "U_P702_MY2021_Rx" SG_ 516 EngAout_N_Actl 1;
BA_ "U_T6_MCA_MY2020_Rx" SG_ 516 EngAout_N_Actl 1;
BA_ "U_CD542_MY2021_Rx" SG_ 516 EngAout_N_Actl 1;
BA_ "U_U55X_MY2022_Rx" SG_ 516 EngAout_N_Actl 1;
BA_ "U_CD764_MY2022_Rx" SG_ 516 EngAout_N_Actl 1;
BA_ "ContentDependant" SG_ 516 ApedPosPcActl_No_Cnt 1;
BA_ "MetaData" SG_ 516 ApedPosPcActl_No_Cnt 1;
BA_ "ContentDependant" SG_ 516 ApedPosPcActl_No_Cs 1;
BA_ "MetaData" SG_ 516 ApedPosPcActl_No_Cs 1;
BA_ "ContentDependant" SG_ 377 EngFuelCutFull_B_Inhbt 1;
BA_ "ContentDependant" SG_ 377 FuelFlw_Vl_Dsply 1;
BA_ "ContentDependant" SG_ 377 FuelFillInlet_B_Dsply 1;
BA_ "ContentDependant" SG_ 377 OdoCount 1;
BA_ "ContentDependant" SG_ 377 EngOilLife_Pc_Actl 1;
BA_ "ContentDependant" SG_ 377 TrnKickDown_B_RqDrv 1;
BA_ "ContentDependant" SG_ 377 AirCondRec_B_Rq 1;
BA_ "ContentDependant" SG_ 377 AirCondClutch_B_Stats 1;
BA_ "MetaData" SG_ 377 EngAoutTqActl_D_Qf 1;
BA_ "MetaData" SG_ 76 FirstRowBuckle_No_Cs 1;
BA_ "MetaData" SG_ 76 RCMStatusMsg2_No_Cnt 1;
BA_ "GenSigStartValueInteger" SG_ 76 PsngrFmidDetct_D_Actl 3;
BA_ "GenSigStartValue" SG_ 76 PsngrFmidDetct_D_Actl 3;
BA_ "GenSigStartValueInteger" SG_ 76 FirstRowBuckleMid 3;
BA_ "GenSigStartValue" SG_ 76 FirstRowBuckleMid 3;
BA_ "GenSigStartValueInteger" SG_ 76 ThirdRowBucklePsngr 3;
BA_ "GenSigStartValue" SG_ 76 ThirdRowBucklePsngr 3;
BA_ "GenSigStartValueInteger" SG_ 76 ThirdRowBuckleMid 3;
BA_ "GenSigStartValue" SG_ 76 ThirdRowBuckleMid 3;
BA_ "GenSigStartValueInteger" SG_ 76 ThirdRowBuckleDriver 3;
BA_ "GenSigStartValue" SG_ 76 ThirdRowBuckleDriver 3;
BA_ "GenSigStartValueInteger" SG_ 76 SecondRowBucklePsngr 3;
BA_ "GenSigStartValue" SG_ 76 SecondRowBucklePsngr 3;
BA_ "GenSigStartValueInteger" SG_ 76 SecondRowBuckleMid 3;
BA_ "GenSigStartValue" SG_ 76 SecondRowBuckleMid 3;
BA_ "GenSigStartValueInteger" SG_ 76 SecondRowBuckleDriver 3;
BA_ "GenSigStartValue" SG_ 76 SecondRowBuckleDriver 3;
BA_ "GenSigStartValueInteger" SG_ 76 FirstRowBuckleDriver 3;
BA_ "GenSigStartValue" SG_ 76 FirstRowBuckleDriver 3;
BA_ "U_CX727_MY2021_Rx" SG_ 76 FirstRowBuckleDriver 1;
BA_ "U_P702_MY2021_Rx" SG_ 76 FirstRowBuckleDriver 1;
BA_ "U_T6_MCA_MY2020_Rx" SG_ 76 FirstRowBuckleDriver 1;
BA_ "U_CD542_MY2021_Rx" SG_ 76 FirstRowBuckleDriver 1;
BA_ "U_U55X_MY2022_Rx" SG_ 76 FirstRowBuckleDriver 1;
BA_ "U_CD764_MY2022_Rx" SG_ 76 FirstRowBuckleDriver 1;
BA_ "GenSigStartValueInteger" SG_ 76 FirstRowBucklePsngr 3;
BA_ "GenSigStartValue" SG_ 76 FirstRowBucklePsngr 3;
BA_ "U_T6_MCA_MY2020_Rx" SG_ 76 FirstRowBucklePsngr 1;
BA_ "U_U55X_MY2022_Rx" SG_ 76 FirstRowBucklePsngr 1;
BA_ "WakeupSignal" SG_ 76 RstrnImpactEvntStatus 1;
BA_ "U_CX727_MY2021_Rx" SG_ 76 RstrnImpactEvntStatus 1;
BA_ "U_P702_MY2021_Rx" SG_ 76 RstrnImpactEvntStatus 1;
BA_ "U_CD542_MY2021_Rx" SG_ 76 RstrnImpactEvntStatus 1;
BA_ "U_T6_MCA_MY2020_Rx" SG_ 76 RstrnImpactEvntStatus 1;
BA_ "U_U55X_MY2022_Rx" SG_ 76 RstrnImpactEvntStatus 1;
BA_ "U_CD764_MY2022_Rx" SG_ 76 RstrnImpactEvntStatus 1;
BA_ "GenSigStartValueInteger" SG_ 76 PsngrFrntDetct_D_Actl 3;
BA_ "GenSigStartValue" SG_ 76 PsngrFrntDetct_D_Actl 3;
BA_ "GenSigStartValueInteger" SG_ 76 PassRstrnInd_Req 3;
BA_ "GenSigStartValue" SG_ 76 PassRstrnInd_Req 3;
BA_ "GenSigSendType" SG_ 1870 TesterPhysicalResDCDC 3;
BA_ "U_CX727_MY2021_Tx" SG_ 1870 TesterPhysicalResDCDC 1;
BA_ "U_P702_MY2021_Tx" SG_ 1870 TesterPhysicalResDCDC 1;
BA_ "U_CD542_MY2021_Tx" SG_ 1870 TesterPhysicalResDCDC 1;
BA_ "U_T6_MCA_MY2020_Tx" SG_ 1870 TesterPhysicalResDCDC 1;
BA_ "GenSigSendType" SG_ 1862 TesterPhysicalReqDCDC 3;
BA_ "U_CX727_MY2021_Rx" SG_ 1862 TesterPhysicalReqDCDC 1;
BA_ "U_P702_MY2021_Rx" SG_ 1862 TesterPhysicalReqDCDC 1;
BA_ "U_CD542_MY2021_Rx" SG_ 1862 TesterPhysicalReqDCDC 1;
BA_ "U_T6_MCA_MY2020_Rx" SG_ 1862 TesterPhysicalReqDCDC 1;
BA_ "GenSigStartValueInteger" SG_ 967 CamraViewSplit_D_Actl 2;
BA_ "GenSigStartValue" SG_ 967 CamraViewSplit_D_Actl 2;
BA_ "GenSigSendType" SG_ 967 CamraViewSplit_D_Actl 3;
BA_ "U_CX727_MY2021_Tx" SG_ 967 CamraViewSplit_D_Actl 1;
BA_ "U_P702_MY2021_Tx" SG_ 967 CamraViewSplit_D_Actl 1;
BA_ "U_T6_MCA_MY2020_Tx" SG_ 967 CamraViewSplit_D_Actl 1;
BA_ "U_CD542_MY2021_Tx" SG_ 967 CamraViewSplit_D_Actl 1;
BA_ "U_U55X_MY2022_Tx" SG_ 967 CamraViewSplit_D_Actl 1;
BA_ "U_CD764_MY2022_Tx" SG_ 967 CamraViewSplit_D_Actl 1;
BA_ "GenSigSendType" SG_ 967 CamraOvrlTow_D_Actl 3;
BA_ "U_CX727_MY2021_Tx" SG_ 967 CamraOvrlTow_D_Actl 1;
BA_ "U_P702_MY2021_Tx" SG_ 967 CamraOvrlTow_D_Actl 1;
BA_ "U_T6_MCA_MY2020_Tx" SG_ 967 CamraOvrlTow_D_Actl 1;
BA_ "U_CD542_MY2021_Tx" SG_ 967 CamraOvrlTow_D_Actl 1;
BA_ "U_U55X_MY2022_Tx" SG_ 967 CamraOvrlTow_D_Actl 1;
BA_ "U_CD764_MY2022_Tx" SG_ 967 CamraOvrlTow_D_Actl 1;
BA_ "GenSigSendType" SG_ 967 CamZoomActiveState 3;
BA_ "U_CX727_MY2021_Tx" SG_ 967 CamZoomActiveState 1;
BA_ "U_P702_MY2021_Tx" SG_ 967 CamZoomActiveState 1;
BA_ "U_T6_MCA_MY2020_Tx" SG_ 967 CamZoomActiveState 1;
BA_ "U_CD542_MY2021_Tx" SG_ 967 CamZoomActiveState 1;
BA_ "U_U55X_MY2022_Tx" SG_ 967 CamZoomActiveState 1;
BA_ "U_CD764_MY2022_Tx" SG_ 967 CamZoomActiveState 1;
BA_ "GenSigSendType" SG_ 967 CamraZoomMan_D_Actl 3;
BA_ "U_CX727_MY2021_Tx" SG_ 967 CamraZoomMan_D_Actl 1;
BA_ "U_P702_MY2021_Tx" SG_ 967 CamraZoomMan_D_Actl 1;
BA_ "U_T6_MCA_MY2020_Tx" SG_ 967 CamraZoomMan_D_Actl 1;
BA_ "U_CD542_MY2021_Tx" SG_ 967 CamraZoomMan_D_Actl 1;
BA_ "U_U55X_MY2022_Tx" SG_ 967 CamraZoomMan_D_Actl 1;
BA_ "U_CD764_MY2022_Tx" SG_ 967 CamraZoomMan_D_Actl 1;
BA_ "GenSigSendType" SG_ 967 CamraOvrlStat_D_Actl 3;
BA_ "U_CX727_MY2021_Tx" SG_ 967 CamraOvrlStat_D_Actl 1;
BA_ "U_P702_MY2021_Tx" SG_ 967 CamraOvrlStat_D_Actl 1;
BA_ "U_T6_MCA_MY2020_Tx" SG_ 967 CamraOvrlStat_D_Actl 1;
BA_ "U_CD542_MY2021_Tx" SG_ 967 CamraOvrlStat_D_Actl 1;
BA_ "U_U55X_MY2022_Tx" SG_ 967 CamraOvrlStat_D_Actl 1;
BA_ "U_CD764_MY2022_Tx" SG_ 967 CamraOvrlStat_D_Actl 1;
BA_ "GenSigSendType" SG_ 967 CamraOvrlDyn_D_Actl 3;
BA_ "U_CX727_MY2021_Tx" SG_ 967 CamraOvrlDyn_D_Actl 1;
BA_ "U_P702_MY2021_Tx" SG_ 967 CamraOvrlDyn_D_Actl 1;
BA_ "U_T6_MCA_MY2020_Tx" SG_ 967 CamraOvrlDyn_D_Actl 1;
BA_ "U_CD542_MY2021_Tx" SG_ 967 CamraOvrlDyn_D_Actl 1;
BA_ "U_U55X_MY2022_Tx" SG_ 967 CamraOvrlDyn_D_Actl 1;
BA_ "U_CD764_MY2022_Tx" SG_ 967 CamraOvrlDyn_D_Actl 1;
BA_ "GenSigSendType" SG_ 967 CamPDCGuidStat 3;
BA_ "U_CX727_MY2021_Tx" SG_ 967 CamPDCGuidStat 1;
BA_ "U_P702_MY2021_Tx" SG_ 967 CamPDCGuidStat 1;
BA_ "U_T6_MCA_MY2020_Tx" SG_ 967 CamPDCGuidStat 1;
BA_ "U_CD542_MY2021_Tx" SG_ 967 CamPDCGuidStat 1;
BA_ "U_U55X_MY2022_Tx" SG_ 967 CamPDCGuidStat 1;
BA_ "U_CD764_MY2022_Tx" SG_ 967 CamPDCGuidStat 1;
BA_ "GenSigStartValueInteger" SG_ 949 Tire_Press_RR_ORR_Data 65533;
BA_ "GenSigStartValue" SG_ 949 Tire_Press_RR_ORR_Data 65533;
BA_ "U_T6_MCA_MY2020_Rx" SG_ 949 Tire_Press_RR_ORR_Data 1;
BA_ "ECGUsedRxSignal" SG_ 949 Tire_Press_RR_ORR_Data 1;
BA_ "U_CD542_MY2021_Rx" SG_ 949 Tire_Press_RR_ORR_Data 1;
BA_ "U_U55X_MY2022_Rx" SG_ 949 Tire_Press_RR_ORR_Data 1;
BA_ "U_CD764_MY2022_Rx" SG_ 949 Tire_Press_RR_ORR_Data 1;
BA_ "U_CX727_MY2021_Tx" SG_ 949 Tire_Press_RR_ORR_Data 1;
BA_ "U_P702_MY2021_Tx" SG_ 949 Tire_Press_RR_ORR_Data 1;
BA_ "U_T6_MCA_MY2020_Tx" SG_ 949 Tire_Press_RR_ORR_Data 1;
BA_ "U_CD542_MY2021_Tx" SG_ 949 Tire_Press_RR_ORR_Data 1;
BA_ "U_U55X_MY2022_Tx" SG_ 949 Tire_Press_RR_ORR_Data 1;
BA_ "U_CD764_MY2022_Tx" SG_ 949 Tire_Press_RR_ORR_Data 1;
BA_ "GenSigStartValueInteger" SG_ 949 Tire_Press_LR_OLR_Data 65533;
BA_ "GenSigStartValue" SG_ 949 Tire_Press_LR_OLR_Data 65533;
BA_ "U_T6_MCA_MY2020_Rx" SG_ 949 Tire_Press_LR_OLR_Data 1;
BA_ "ECGUsedRxSignal" SG_ 949 Tire_Press_LR_OLR_Data 1;
BA_ "U_CD542_MY2021_Rx" SG_ 949 Tire_Press_LR_OLR_Data 1;
BA_ "U_U55X_MY2022_Rx" SG_ 949 Tire_Press_LR_OLR_Data 1;
BA_ "U_CD764_MY2022_Rx" SG_ 949 Tire_Press_LR_OLR_Data 1;
BA_ "U_CX727_MY2021_Tx" SG_ 949 Tire_Press_LR_OLR_Data 1;
BA_ "U_P702_MY2021_Tx" SG_ 949 Tire_Press_LR_OLR_Data 1;
BA_ "U_T6_MCA_MY2020_Tx" SG_ 949 Tire_Press_LR_OLR_Data 1;
BA_ "U_CD542_MY2021_Tx" SG_ 949 Tire_Press_LR_OLR_Data 1;
BA_ "U_U55X_MY2022_Tx" SG_ 949 Tire_Press_LR_OLR_Data 1;
BA_ "U_CD764_MY2022_Tx" SG_ 949 Tire_Press_LR_OLR_Data 1;
BA_ "GenSigStartValueInteger" SG_ 949 Tire_Press_LF_Data 65533;
BA_ "GenSigStartValue" SG_ 949 Tire_Press_LF_Data 65533;
BA_ "U_T6_MCA_MY2020_Rx" SG_ 949 Tire_Press_LF_Data 1;
BA_ "ECGUsedRxSignal" SG_ 949 Tire_Press_LF_Data 1;
BA_ "U_CD542_MY2021_Rx" SG_ 949 Tire_Press_LF_Data 1;
BA_ "U_U55X_MY2022_Rx" SG_ 949 Tire_Press_LF_Data 1;
BA_ "U_CD764_MY2022_Rx" SG_ 949 Tire_Press_LF_Data 1;
BA_ "U_CX727_MY2021_Tx" SG_ 949 Tire_Press_LF_Data 1;
BA_ "U_P702_MY2021_Tx" SG_ 949 Tire_Press_LF_Data 1;
BA_ "U_T6_MCA_MY2020_Tx" SG_ 949 Tire_Press_LF_Data 1;
BA_ "U_CD542_MY2021_Tx" SG_ 949 Tire_Press_LF_Data 1;
BA_ "U_U55X_MY2022_Tx" SG_ 949 Tire_Press_LF_Data 1;
BA_ "U_CD764_MY2022_Tx" SG_ 949 Tire_Press_LF_Data 1;
BA_ "GenSigStartValueInteger" SG_ 949 Tire_Press_RF_Data 65533;
BA_ "GenSigStartValue" SG_ 949 Tire_Press_RF_Data 65533;
BA_ "U_T6_MCA_MY2020_Rx" SG_ 949 Tire_Press_RF_Data 1;
BA_ "ECGUsedRxSignal" SG_ 949 Tire_Press_RF_Data 1;
BA_ "U_CD542_MY2021_Rx" SG_ 949 Tire_Press_RF_Data 1;
BA_ "U_U55X_MY2022_Rx" SG_ 949 Tire_Press_RF_Data 1;
BA_ "U_CD764_MY2022_Rx" SG_ 949 Tire_Press_RF_Data 1;
BA_ "U_CX727_MY2021_Tx" SG_ 949 Tire_Press_RF_Data 1;
BA_ "U_P702_MY2021_Tx" SG_ 949 Tire_Press_RF_Data 1;
BA_ "U_T6_MCA_MY2020_Tx" SG_ 949 Tire_Press_RF_Data 1;
BA_ "U_CD542_MY2021_Tx" SG_ 949 Tire_Press_RF_Data 1;
BA_ "U_U55X_MY2022_Tx" SG_ 949 Tire_Press_RF_Data 1;
BA_ "U_CD764_MY2022_Tx" SG_ 949 Tire_Press_RF_Data 1;
BA_ "GenSigStartValueInteger" SG_ 948 Tire_Press_Placrd_Rear 255;
BA_ "GenSigStartValue" SG_ 948 Tire_Press_Placrd_Rear 255;
BA_ "GenSigSendType" SG_ 948 Tire_Press_Placrd_Rear 3;
BA_ "U_T6_MCA_MY2020_Rx" SG_ 948 Tire_Press_Placrd_Rear 1;
BA_ "ECGUsedRxSignal" SG_ 948 Tire_Press_Placrd_Rear 1;
BA_ "U_CD542_MY2021_Rx" SG_ 948 Tire_Press_Placrd_Rear 1;
BA_ "U_U55X_MY2022_Rx" SG_ 948 Tire_Press_Placrd_Rear 1;
BA_ "U_CD764_MY2022_Rx" SG_ 948 Tire_Press_Placrd_Rear 1;
BA_ "U_CX727_MY2021_Tx" SG_ 948 Tire_Press_Placrd_Rear 1;
BA_ "U_P702_MY2021_Tx" SG_ 948 Tire_Press_Placrd_Rear 1;
BA_ "U_T6_MCA_MY2020_Tx" SG_ 948 Tire_Press_Placrd_Rear 1;
BA_ "U_CD542_MY2021_Tx" SG_ 948 Tire_Press_Placrd_Rear 1;
BA_ "U_U55X_MY2022_Tx" SG_ 948 Tire_Press_Placrd_Rear 1;
BA_ "U_CD764_MY2022_Tx" SG_ 948 Tire_Press_Placrd_Rear 1;
BA_ "GenSigStartValueInteger" SG_ 948 Tire_Press_Placrd_Frnt 255;
BA_ "GenSigStartValue" SG_ 948 Tire_Press_Placrd_Frnt 255;
BA_ "GenSigSendType" SG_ 948 Tire_Press_Placrd_Frnt 3;
BA_ "U_T6_MCA_MY2020_Rx" SG_ 948 Tire_Press_Placrd_Frnt 1;
BA_ "ECGUsedRxSignal" SG_ 948 Tire_Press_Placrd_Frnt 1;
BA_ "U_CD542_MY2021_Rx" SG_ 948 Tire_Press_Placrd_Frnt 1;
BA_ "U_U55X_MY2022_Rx" SG_ 948 Tire_Press_Placrd_Frnt 1;
BA_ "U_CD764_MY2022_Rx" SG_ 948 Tire_Press_Placrd_Frnt 1;
BA_ "U_CX727_MY2021_Tx" SG_ 948 Tire_Press_Placrd_Frnt 1;
BA_ "U_P702_MY2021_Tx" SG_ 948 Tire_Press_Placrd_Frnt 1;
BA_ "U_T6_MCA_MY2020_Tx" SG_ 948 Tire_Press_Placrd_Frnt 1;
BA_ "U_CD542_MY2021_Tx" SG_ 948 Tire_Press_Placrd_Frnt 1;
BA_ "U_U55X_MY2022_Tx" SG_ 948 Tire_Press_Placrd_Frnt 1;
BA_ "U_CD764_MY2022_Tx" SG_ 948 Tire_Press_Placrd_Frnt 1;
BA_ "GenSigSendType" SG_ 948 Tire_Press_ILR_Stat 3;
BA_ "U_T6_MCA_MY2020_Rx" SG_ 948 Tire_Press_ILR_Stat 1;
BA_ "ECGUsedRxSignal" SG_ 948 Tire_Press_ILR_Stat 1;
BA_ "U_CD542_MY2021_Rx" SG_ 948 Tire_Press_ILR_Stat 1;
BA_ "U_U55X_MY2022_Rx" SG_ 948 Tire_Press_ILR_Stat 1;
BA_ "U_CD764_MY2022_Rx" SG_ 948 Tire_Press_ILR_Stat 1;
BA_ "U_CX727_MY2021_Tx" SG_ 948 Tire_Press_ILR_Stat 1;
BA_ "U_P702_MY2021_Tx" SG_ 948 Tire_Press_ILR_Stat 1;
BA_ "U_T6_MCA_MY2020_Tx" SG_ 948 Tire_Press_ILR_Stat 1;
BA_ "U_CD542_MY2021_Tx" SG_ 948 Tire_Press_ILR_Stat 1;
BA_ "U_U55X_MY2022_Tx" SG_ 948 Tire_Press_ILR_Stat 1;
BA_ "U_CD764_MY2022_Tx" SG_ 948 Tire_Press_ILR_Stat 1;
BA_ "GenSigSendType" SG_ 948 Tire_Press_IRR_Stat 3;
BA_ "U_T6_MCA_MY2020_Rx" SG_ 948 Tire_Press_IRR_Stat 1;
BA_ "ECGUsedRxSignal" SG_ 948 Tire_Press_IRR_Stat 1;
BA_ "U_CD542_MY2021_Rx" SG_ 948 Tire_Press_IRR_Stat 1;
BA_ "U_U55X_MY2022_Rx" SG_ 948 Tire_Press_IRR_Stat 1;
BA_ "U_CD764_MY2022_Rx" SG_ 948 Tire_Press_IRR_Stat 1;
BA_ "U_CX727_MY2021_Tx" SG_ 948 Tire_Press_IRR_Stat 1;
BA_ "U_P702_MY2021_Tx" SG_ 948 Tire_Press_IRR_Stat 1;
BA_ "U_T6_MCA_MY2020_Tx" SG_ 948 Tire_Press_IRR_Stat 1;
BA_ "U_CD542_MY2021_Tx" SG_ 948 Tire_Press_IRR_Stat 1;
BA_ "U_U55X_MY2022_Tx" SG_ 948 Tire_Press_IRR_Stat 1;
BA_ "U_CD764_MY2022_Tx" SG_ 948 Tire_Press_IRR_Stat 1;
BA_ "GenSigSendType" SG_ 948 Tire_Press_LR_OLR_Stat 3;
BA_ "U_T6_MCA_MY2020_Rx" SG_ 948 Tire_Press_LR_OLR_Stat 1;
BA_ "ECGUsedRxSignal" SG_ 948 Tire_Press_LR_OLR_Stat 1;
BA_ "U_CD542_MY2021_Rx" SG_ 948 Tire_Press_LR_OLR_Stat 1;
BA_ "U_U55X_MY2022_Rx" SG_ 948 Tire_Press_LR_OLR_Stat 1;
BA_ "U_CD764_MY2022_Rx" SG_ 948 Tire_Press_LR_OLR_Stat 1;
BA_ "U_CX727_MY2021_Tx" SG_ 948 Tire_Press_LR_OLR_Stat 1;
BA_ "U_P702_MY2021_Tx" SG_ 948 Tire_Press_LR_OLR_Stat 1;
BA_ "U_T6_MCA_MY2020_Tx" SG_ 948 Tire_Press_LR_OLR_Stat 1;
BA_ "U_CD542_MY2021_Tx" SG_ 948 Tire_Press_LR_OLR_Stat 1;
BA_ "U_U55X_MY2022_Tx" SG_ 948 Tire_Press_LR_OLR_Stat 1;
BA_ "U_CD764_MY2022_Tx" SG_ 948 Tire_Press_LR_OLR_Stat 1;
BA_ "GenSigSendType" SG_ 948 Tire_Press_RR_ORR_Stat 3;
BA_ "U_T6_MCA_MY2020_Rx" SG_ 948 Tire_Press_RR_ORR_Stat 1;
BA_ "ECGUsedRxSignal" SG_ 948 Tire_Press_RR_ORR_Stat 1;
BA_ "U_CD542_MY2021_Rx" SG_ 948 Tire_Press_RR_ORR_Stat 1;
BA_ "U_U55X_MY2022_Rx" SG_ 948 Tire_Press_RR_ORR_Stat 1;
BA_ "U_CD764_MY2022_Rx" SG_ 948 Tire_Press_RR_ORR_Stat 1;
BA_ "U_CX727_MY2021_Tx" SG_ 948 Tire_Press_RR_ORR_Stat 1;
BA_ "U_P702_MY2021_Tx" SG_ 948 Tire_Press_RR_ORR_Stat 1;
BA_ "U_T6_MCA_MY2020_Tx" SG_ 948 Tire_Press_RR_ORR_Stat 1;
BA_ "U_CD542_MY2021_Tx" SG_ 948 Tire_Press_RR_ORR_Stat 1;
BA_ "U_U55X_MY2022_Tx" SG_ 948 Tire_Press_RR_ORR_Stat 1;
BA_ "U_CD764_MY2022_Tx" SG_ 948 Tire_Press_RR_ORR_Stat 1;
BA_ "GenSigSendType" SG_ 948 Tire_Press_RF_Stat 3;
BA_ "U_T6_MCA_MY2020_Rx" SG_ 948 Tire_Press_RF_Stat 1;
BA_ "ECGUsedRxSignal" SG_ 948 Tire_Press_RF_Stat 1;
BA_ "U_CD542_MY2021_Rx" SG_ 948 Tire_Press_RF_Stat 1;
BA_ "U_U55X_MY2022_Rx" SG_ 948 Tire_Press_RF_Stat 1;
BA_ "U_CD764_MY2022_Rx" SG_ 948 Tire_Press_RF_Stat 1;
BA_ "U_CX727_MY2021_Tx" SG_ 948 Tire_Press_RF_Stat 1;
BA_ "U_P702_MY2021_Tx" SG_ 948 Tire_Press_RF_Stat 1;
BA_ "U_T6_MCA_MY2020_Tx" SG_ 948 Tire_Press_RF_Stat 1;
BA_ "U_CD542_MY2021_Tx" SG_ 948 Tire_Press_RF_Stat 1;
BA_ "U_U55X_MY2022_Tx" SG_ 948 Tire_Press_RF_Stat 1;
BA_ "U_CD764_MY2022_Tx" SG_ 948 Tire_Press_RF_Stat 1;
BA_ "GenSigSendType" SG_ 948 Tire_Press_LF_Stat 3;
BA_ "U_T6_MCA_MY2020_Rx" SG_ 948 Tire_Press_LF_Stat 1;
BA_ "ECGUsedRxSignal" SG_ 948 Tire_Press_LF_Stat 1;
BA_ "U_CD542_MY2021_Rx" SG_ 948 Tire_Press_LF_Stat 1;
BA_ "U_U55X_MY2022_Rx" SG_ 948 Tire_Press_LF_Stat 1;
BA_ "U_CD764_MY2022_Rx" SG_ 948 Tire_Press_LF_Stat 1;
BA_ "U_CX727_MY2021_Tx" SG_ 948 Tire_Press_LF_Stat 1;
BA_ "U_P702_MY2021_Tx" SG_ 948 Tire_Press_LF_Stat 1;
BA_ "U_T6_MCA_MY2020_Tx" SG_ 948 Tire_Press_LF_Stat 1;
BA_ "U_CD542_MY2021_Tx" SG_ 948 Tire_Press_LF_Stat 1;
BA_ "U_U55X_MY2022_Tx" SG_ 948 Tire_Press_LF_Stat 1;
BA_ "U_CD764_MY2022_Tx" SG_ 948 Tire_Press_LF_Stat 1;
BA_ "GenSigSendType" SG_ 948 Tire_Press_System_Stat 3;
BA_ "U_T6_MCA_MY2020_Rx" SG_ 948 Tire_Press_System_Stat 1;
BA_ "ECGUsedRxSignal" SG_ 948 Tire_Press_System_Stat 1;
BA_ "U_CD542_MY2021_Rx" SG_ 948 Tire_Press_System_Stat 1;
BA_ "U_U55X_MY2022_Rx" SG_ 948 Tire_Press_System_Stat 1;
BA_ "U_CD764_MY2022_Rx" SG_ 948 Tire_Press_System_Stat 1;
BA_ "U_CX727_MY2021_Tx" SG_ 948 Tire_Press_System_Stat 1;
BA_ "U_P702_MY2021_Tx" SG_ 948 Tire_Press_System_Stat 1;
BA_ "U_T6_MCA_MY2020_Tx" SG_ 948 Tire_Press_System_Stat 1;
BA_ "U_CD542_MY2021_Tx" SG_ 948 Tire_Press_System_Stat 1;
BA_ "U_U55X_MY2022_Tx" SG_ 948 Tire_Press_System_Stat 1;
BA_ "U_CD764_MY2022_Tx" SG_ 948 Tire_Press_System_Stat 1;
BA_ "GenSigSendType" SG_ 948 Tire_Press_Telltale 3;
BA_ "U_CX727_MY2021_Tx" SG_ 948 Tire_Press_Telltale 1;
BA_ "U_P702_MY2021_Tx" SG_ 948 Tire_Press_Telltale 1;
BA_ "U_T6_MCA_MY2020_Tx" SG_ 948 Tire_Press_Telltale 1;
BA_ "U_CD542_MY2021_Tx" SG_ 948 Tire_Press_Telltale 1;
BA_ "U_U55X_MY2022_Tx" SG_ 948 Tire_Press_Telltale 1;
BA_ "U_CD764_MY2022_Tx" SG_ 948 Tire_Press_Telltale 1;
BA_ "GenSigSendType" SG_ 948 TirePReset_D_Stat 3;
BA_ "U_CX727_MY2021_Tx" SG_ 948 TirePReset_D_Stat 1;
BA_ "U_P702_MY2021_Tx" SG_ 948 TirePReset_D_Stat 1;
BA_ "U_T6_MCA_MY2020_Tx" SG_ 948 TirePReset_D_Stat 1;
BA_ "U_CD542_MY2021_Tx" SG_ 948 TirePReset_D_Stat 1;
BA_ "U_U55X_MY2022_Tx" SG_ 948 TirePReset_D_Stat 1;
BA_ "U_CD764_MY2022_Tx" SG_ 948 TirePReset_D_Stat 1;
BA_ "U_CX727_MY2021_Rx" SG_ 1077 PrkLckCtlEnbl_D_RqIpc_UB 1;
BA_ "U_P702_MY2021_Rx" SG_ 1077 PrkLckCtlEnbl_D_RqIpc_UB 1;
BA_ "U_T6_MCA_MY2020_Rx" SG_ 1077 PrkLckCtlEnbl_D_RqIpc_UB 1;
BA_ "U_CD542_MY2021_Rx" SG_ 1077 PrkLckCtlEnbl_D_RqIpc_UB 1;
BA_ "U_U55X_MY2022_Rx" SG_ 1077 PrkLckCtlEnbl_D_RqIpc_UB 1;
BA_ "U_CD764_MY2022_Rx" SG_ 1077 PrkLckCtlEnbl_D_RqIpc_UB 1;
BA_ "U_T6_MCA_MY2020_Tx" SG_ 1077 PrkLckCtlEnbl_D_RqIpc_UB 1;
BA_ "U_CD542_MY2021_Tx" SG_ 1077 PrkLckCtlEnbl_D_RqIpc_UB 1;
BA_ "U_U55X_MY2022_Tx" SG_ 1077 PrkLckCtlEnbl_D_RqIpc_UB 1;
BA_ "U_CD764_MY2022_Tx" SG_ 1077 PrkLckCtlEnbl_D_RqIpc_UB 1;
BA_ "GenSigSendType" SG_ 1077 PrkLckCtlEnbl_D_RqIpc 3;
BA_ "U_CX727_MY2021_Rx" SG_ 1077 PrkLckCtlEnbl_D_RqIpc 1;
BA_ "U_P702_MY2021_Rx" SG_ 1077 PrkLckCtlEnbl_D_RqIpc 1;
BA_ "U_T6_MCA_MY2020_Rx" SG_ 1077 PrkLckCtlEnbl_D_RqIpc 1;
BA_ "U_CD542_MY2021_Rx" SG_ 1077 PrkLckCtlEnbl_D_RqIpc 1;
BA_ "U_U55X_MY2022_Rx" SG_ 1077 PrkLckCtlEnbl_D_RqIpc 1;
BA_ "U_CD764_MY2022_Rx" SG_ 1077 PrkLckCtlEnbl_D_RqIpc 1;
BA_ "U_T6_MCA_MY2020_Tx" SG_ 1077 PrkLckCtlEnbl_D_RqIpc 1;
BA_ "U_CD542_MY2021_Tx" SG_ 1077 PrkLckCtlEnbl_D_RqIpc 1;
BA_ "U_U55X_MY2022_Tx" SG_ 1077 PrkLckCtlEnbl_D_RqIpc 1;
BA_ "U_CD764_MY2022_Tx" SG_ 1077 PrkLckCtlEnbl_D_RqIpc 1;
BA_ "U_T6_MCA_MY2020_Tx" SG_ 1077 FuelLvl_Pc_Dsply_UB 1;
BA_ "U_CD542_MY2021_Tx" SG_ 1077 FuelLvl_Pc_Dsply_UB 1;
BA_ "U_U55X_MY2022_Tx" SG_ 1077 FuelLvl_Pc_Dsply_UB 1;
BA_ "U_CD764_MY2022_Tx" SG_ 1077 FuelLvl_Pc_Dsply_UB 1;
BA_ "WakeupSignal" SG_ 1077 PtWakeupActv1_B_Rq 1;
BA_ "GenSigSendType" SG_ 1077 PtWakeupActv1_B_Rq 3;
BA_ "U_CX727_MY2021_Rx" SG_ 1077 PtWakeupActv1_B_Rq 1;
BA_ "U_P702_MY2021_Rx" SG_ 1077 PtWakeupActv1_B_Rq 1;
BA_ "U_T6_MCA_MY2020_Rx" SG_ 1077 PtWakeupActv1_B_Rq 1;
BA_ "U_CD542_MY2021_Rx" SG_ 1077 PtWakeupActv1_B_Rq 1;
BA_ "U_U55X_MY2022_Rx" SG_ 1077 PtWakeupActv1_B_Rq 1;
BA_ "U_CD764_MY2022_Rx" SG_ 1077 PtWakeupActv1_B_Rq 1;
BA_ "U_T6_MCA_MY2020_Tx" SG_ 1077 PtWakeupActv1_B_Rq 1;
BA_ "ECGUsedTxSignal" SG_ 1077 PtWakeupActv1_B_Rq 1;
BA_ "U_CD542_MY2021_Tx" SG_ 1077 PtWakeupActv1_B_Rq 1;
BA_ "U_U55X_MY2022_Tx" SG_ 1077 PtWakeupActv1_B_Rq 1;
BA_ "U_CD764_MY2022_Tx" SG_ 1077 PtWakeupActv1_B_Rq 1;
BA_ "U_CX727_MY2021_Rx" SG_ 1077 PtWakeupActv1_B_Rq_UB 1;
BA_ "U_P702_MY2021_Rx" SG_ 1077 PtWakeupActv1_B_Rq_UB 1;
BA_ "U_T6_MCA_MY2020_Rx" SG_ 1077 PtWakeupActv1_B_Rq_UB 1;
BA_ "U_CD542_MY2021_Rx" SG_ 1077 PtWakeupActv1_B_Rq_UB 1;
BA_ "U_U55X_MY2022_Rx" SG_ 1077 PtWakeupActv1_B_Rq_UB 1;
BA_ "U_CD764_MY2022_Rx" SG_ 1077 PtWakeupActv1_B_Rq_UB 1;
BA_ "U_T6_MCA_MY2020_Tx" SG_ 1077 PtWakeupActv1_B_Rq_UB 1;
BA_ "ECGUsedTxSignal" SG_ 1077 PtWakeupActv1_B_Rq_UB 1;
BA_ "U_CD542_MY2021_Tx" SG_ 1077 PtWakeupActv1_B_Rq_UB 1;
BA_ "U_U55X_MY2022_Tx" SG_ 1077 PtWakeupActv1_B_Rq_UB 1;
BA_ "U_CD764_MY2022_Tx" SG_ 1077 PtWakeupActv1_B_Rq_UB 1;
BA_ "U_CX727_MY2021_Rx" SG_ 1077 Remote_Start_Req_UB 1;
BA_ "U_P702_MY2021_Rx" SG_ 1077 Remote_Start_Req_UB 1;
BA_ "U_T6_MCA_MY2020_Rx" SG_ 1077 Remote_Start_Req_UB 1;
BA_ "U_CD542_MY2021_Rx" SG_ 1077 Remote_Start_Req_UB 1;
BA_ "U_U55X_MY2022_Rx" SG_ 1077 Remote_Start_Req_UB 1;
BA_ "U_CD764_MY2022_Rx" SG_ 1077 Remote_Start_Req_UB 1;
BA_ "U_T6_MCA_MY2020_Tx" SG_ 1077 Remote_Start_Req_UB 1;
BA_ "U_CD542_MY2021_Tx" SG_ 1077 Remote_Start_Req_UB 1;
BA_ "U_U55X_MY2022_Tx" SG_ 1077 Remote_Start_Req_UB 1;
BA_ "U_CD764_MY2022_Tx" SG_ 1077 Remote_Start_Req_UB 1;
BA_ "WakeupSignal" SG_ 1077 Remote_Start_Req 1;
BA_ "GenSigSendType" SG_ 1077 Remote_Start_Req 3;
BA_ "U_CX727_MY2021_Rx" SG_ 1077 Remote_Start_Req 1;
BA_ "U_P702_MY2021_Rx" SG_ 1077 Remote_Start_Req 1;
BA_ "U_T6_MCA_MY2020_Rx" SG_ 1077 Remote_Start_Req 1;
BA_ "U_CD542_MY2021_Rx" SG_ 1077 Remote_Start_Req 1;
BA_ "U_U55X_MY2022_Rx" SG_ 1077 Remote_Start_Req 1;
BA_ "U_CD764_MY2022_Rx" SG_ 1077 Remote_Start_Req 1;
BA_ "U_T6_MCA_MY2020_Tx" SG_ 1077 Remote_Start_Req 1;
BA_ "U_CD542_MY2021_Tx" SG_ 1077 Remote_Start_Req 1;
BA_ "U_U55X_MY2022_Tx" SG_ 1077 Remote_Start_Req 1;
BA_ "U_CD764_MY2022_Tx" SG_ 1077 Remote_Start_Req 1;
BA_ "U_CX727_MY2021_Rx" SG_ 1077 TurnLampTrlrRr_B_Stat_UB 1;
BA_ "U_P702_MY2021_Rx" SG_ 1077 TurnLampTrlrRr_B_Stat_UB 1;
BA_ "U_T6_MCA_MY2020_Rx" SG_ 1077 TurnLampTrlrRr_B_Stat_UB 1;
BA_ "U_CD542_MY2021_Rx" SG_ 1077 TurnLampTrlrRr_B_Stat_UB 1;
BA_ "U_U55X_MY2022_Rx" SG_ 1077 TurnLampTrlrRr_B_Stat_UB 1;
BA_ "U_CD764_MY2022_Rx" SG_ 1077 TurnLampTrlrRr_B_Stat_UB 1;
BA_ "U_T6_MCA_MY2020_Tx" SG_ 1077 TurnLampTrlrRr_B_Stat_UB 1;
BA_ "U_CD542_MY2021_Tx" SG_ 1077 TurnLampTrlrRr_B_Stat_UB 1;
BA_ "U_U55X_MY2022_Tx" SG_ 1077 TurnLampTrlrRr_B_Stat_UB 1;
BA_ "U_CD764_MY2022_Tx" SG_ 1077 TurnLampTrlrRr_B_Stat_UB 1;
BA_ "U_CX727_MY2021_Rx" SG_ 1077 DistanceBarSetting_UB 1;
BA_ "U_P702_MY2021_Rx" SG_ 1077 DistanceBarSetting_UB 1;
BA_ "U_T6_MCA_MY2020_Rx" SG_ 1077 DistanceBarSetting_UB 1;
BA_ "U_CD542_MY2021_Rx" SG_ 1077 DistanceBarSetting_UB 1;
BA_ "U_U55X_MY2022_Rx" SG_ 1077 DistanceBarSetting_UB 1;
BA_ "U_CD764_MY2022_Rx" SG_ 1077 DistanceBarSetting_UB 1;
BA_ "U_T6_MCA_MY2020_Tx" SG_ 1077 DistanceBarSetting_UB 1;
BA_ "U_CD542_MY2021_Tx" SG_ 1077 DistanceBarSetting_UB 1;
BA_ "U_U55X_MY2022_Tx" SG_ 1077 DistanceBarSetting_UB 1;
BA_ "U_CD764_MY2022_Tx" SG_ 1077 DistanceBarSetting_UB 1;
BA_ "U_CX727_MY2021_Rx" SG_ 1077 CamraZoomMan_D_Rq_UB 1;
BA_ "U_P702_MY2021_Rx" SG_ 1077 CamraZoomMan_D_Rq_UB 1;
BA_ "U_T6_MCA_MY2020_Rx" SG_ 1077 CamraZoomMan_D_Rq_UB 1;
BA_ "U_CD542_MY2021_Rx" SG_ 1077 CamraZoomMan_D_Rq_UB 1;
BA_ "U_U55X_MY2022_Rx" SG_ 1077 CamraZoomMan_D_Rq_UB 1;
BA_ "U_CD764_MY2022_Rx" SG_ 1077 CamraZoomMan_D_Rq_UB 1;
BA_ "U_T6_MCA_MY2020_Tx" SG_ 1077 CamraZoomMan_D_Rq_UB 1;
BA_ "U_CD542_MY2021_Tx" SG_ 1077 CamraZoomMan_D_Rq_UB 1;
BA_ "U_U55X_MY2022_Tx" SG_ 1077 CamraZoomMan_D_Rq_UB 1;
BA_ "U_CD764_MY2022_Tx" SG_ 1077 CamraZoomMan_D_Rq_UB 1;
BA_ "U_CX727_MY2021_Rx" SG_ 1077 CamraOvrlStat_D_Rq_UB 1;
BA_ "U_P702_MY2021_Rx" SG_ 1077 CamraOvrlStat_D_Rq_UB 1;
BA_ "U_T6_MCA_MY2020_Rx" SG_ 1077 CamraOvrlStat_D_Rq_UB 1;
BA_ "U_CD542_MY2021_Rx" SG_ 1077 CamraOvrlStat_D_Rq_UB 1;
BA_ "U_U55X_MY2022_Rx" SG_ 1077 CamraOvrlStat_D_Rq_UB 1;
BA_ "U_CD764_MY2022_Rx" SG_ 1077 CamraOvrlStat_D_Rq_UB 1;
BA_ "U_T6_MCA_MY2020_Tx" SG_ 1077 CamraOvrlStat_D_Rq_UB 1;
BA_ "U_CD542_MY2021_Tx" SG_ 1077 CamraOvrlStat_D_Rq_UB 1;
BA_ "U_U55X_MY2022_Tx" SG_ 1077 CamraOvrlStat_D_Rq_UB 1;
BA_ "U_CD764_MY2022_Tx" SG_ 1077 CamraOvrlStat_D_Rq_UB 1;
BA_ "U_CX727_MY2021_Rx" SG_ 1077 CamraOvrlDyn_D_Rq_UB 1;
BA_ "U_P702_MY2021_Rx" SG_ 1077 CamraOvrlDyn_D_Rq_UB 1;
BA_ "U_T6_MCA_MY2020_Rx" SG_ 1077 CamraOvrlDyn_D_Rq_UB 1;
BA_ "U_CD542_MY2021_Rx" SG_ 1077 CamraOvrlDyn_D_Rq_UB 1;
BA_ "U_U55X_MY2022_Rx" SG_ 1077 CamraOvrlDyn_D_Rq_UB 1;
BA_ "U_CD764_MY2022_Rx" SG_ 1077 CamraOvrlDyn_D_Rq_UB 1;
BA_ "U_T6_MCA_MY2020_Tx" SG_ 1077 CamraOvrlDyn_D_Rq_UB 1;
BA_ "U_CD542_MY2021_Tx" SG_ 1077 CamraOvrlDyn_D_Rq_UB 1;
BA_ "U_U55X_MY2022_Tx" SG_ 1077 CamraOvrlDyn_D_Rq_UB 1;
BA_ "U_CD764_MY2022_Tx" SG_ 1077 CamraOvrlDyn_D_Rq_UB 1;
BA_ "U_CX727_MY2021_Rx" SG_ 1077 CamAutoTowbarZoom_UB 1;
BA_ "U_P702_MY2021_Rx" SG_ 1077 CamAutoTowbarZoom_UB 1;
BA_ "U_T6_MCA_MY2020_Rx" SG_ 1077 CamAutoTowbarZoom_UB 1;
BA_ "U_CD542_MY2021_Rx" SG_ 1077 CamAutoTowbarZoom_UB 1;
BA_ "U_U55X_MY2022_Rx" SG_ 1077 CamAutoTowbarZoom_UB 1;
BA_ "U_CD764_MY2022_Rx" SG_ 1077 CamAutoTowbarZoom_UB 1;
BA_ "U_T6_MCA_MY2020_Tx" SG_ 1077 CamAutoTowbarZoom_UB 1;
BA_ "U_CD542_MY2021_Tx" SG_ 1077 CamAutoTowbarZoom_UB 1;
BA_ "U_U55X_MY2022_Tx" SG_ 1077 CamAutoTowbarZoom_UB 1;
BA_ "U_CD764_MY2022_Tx" SG_ 1077 CamAutoTowbarZoom_UB 1;
BA_ "GenSigSendType" SG_ 1077 DistanceBarSetting 3;
BA_ "U_CX727_MY2021_Rx" SG_ 1077 DistanceBarSetting 1;
BA_ "U_P702_MY2021_Rx" SG_ 1077 DistanceBarSetting 1;
BA_ "U_T6_MCA_MY2020_Rx" SG_ 1077 DistanceBarSetting 1;
BA_ "U_CD542_MY2021_Rx" SG_ 1077 DistanceBarSetting 1;
BA_ "U_U55X_MY2022_Rx" SG_ 1077 DistanceBarSetting 1;
BA_ "U_CD764_MY2022_Rx" SG_ 1077 DistanceBarSetting 1;
BA_ "U_T6_MCA_MY2020_Tx" SG_ 1077 DistanceBarSetting 1;
BA_ "U_CD542_MY2021_Tx" SG_ 1077 DistanceBarSetting 1;
BA_ "U_U55X_MY2022_Tx" SG_ 1077 DistanceBarSetting 1;
BA_ "U_CD764_MY2022_Tx" SG_ 1077 DistanceBarSetting 1;
BA_ "GenSigSendType" SG_ 1077 CamraZoomMan_D_Rq 3;
BA_ "U_CX727_MY2021_Rx" SG_ 1077 CamraZoomMan_D_Rq 1;
BA_ "U_P702_MY2021_Rx" SG_ 1077 CamraZoomMan_D_Rq 1;
BA_ "U_T6_MCA_MY2020_Rx" SG_ 1077 CamraZoomMan_D_Rq 1;
BA_ "U_CD542_MY2021_Rx" SG_ 1077 CamraZoomMan_D_Rq 1;
BA_ "U_U55X_MY2022_Rx" SG_ 1077 CamraZoomMan_D_Rq 1;
BA_ "U_CD764_MY2022_Rx" SG_ 1077 CamraZoomMan_D_Rq 1;
BA_ "U_T6_MCA_MY2020_Tx" SG_ 1077 CamraZoomMan_D_Rq 1;
BA_ "U_CD542_MY2021_Tx" SG_ 1077 CamraZoomMan_D_Rq 1;
BA_ "U_U55X_MY2022_Tx" SG_ 1077 CamraZoomMan_D_Rq 1;
BA_ "U_CD764_MY2022_Tx" SG_ 1077 CamraZoomMan_D_Rq 1;
BA_ "GenSigSendType" SG_ 1077 CamraOvrlStat_D_Rq 3;
BA_ "U_CX727_MY2021_Rx" SG_ 1077 CamraOvrlStat_D_Rq 1;
BA_ "U_P702_MY2021_Rx" SG_ 1077 CamraOvrlStat_D_Rq 1;
BA_ "U_T6_MCA_MY2020_Rx" SG_ 1077 CamraOvrlStat_D_Rq 1;
BA_ "U_CD542_MY2021_Rx" SG_ 1077 CamraOvrlStat_D_Rq 1;
BA_ "U_U55X_MY2022_Rx" SG_ 1077 CamraOvrlStat_D_Rq 1;
BA_ "U_CD764_MY2022_Rx" SG_ 1077 CamraOvrlStat_D_Rq 1;
BA_ "U_T6_MCA_MY2020_Tx" SG_ 1077 CamraOvrlStat_D_Rq 1;
BA_ "U_CD542_MY2021_Tx" SG_ 1077 CamraOvrlStat_D_Rq 1;
BA_ "U_U55X_MY2022_Tx" SG_ 1077 CamraOvrlStat_D_Rq 1;
BA_ "U_CD764_MY2022_Tx" SG_ 1077 CamraOvrlStat_D_Rq 1;
BA_ "GenSigSendType" SG_ 1077 CamraOvrlDyn_D_Rq 3;
BA_ "U_CX727_MY2021_Rx" SG_ 1077 CamraOvrlDyn_D_Rq 1;
BA_ "U_P702_MY2021_Rx" SG_ 1077 CamraOvrlDyn_D_Rq 1;
BA_ "U_T6_MCA_MY2020_Rx" SG_ 1077 CamraOvrlDyn_D_Rq 1;
BA_ "U_CD542_MY2021_Rx" SG_ 1077 CamraOvrlDyn_D_Rq 1;
BA_ "U_U55X_MY2022_Rx" SG_ 1077 CamraOvrlDyn_D_Rq 1;
BA_ "U_CD764_MY2022_Rx" SG_ 1077 CamraOvrlDyn_D_Rq 1;
BA_ "U_T6_MCA_MY2020_Tx" SG_ 1077 CamraOvrlDyn_D_Rq 1;
BA_ "U_CD542_MY2021_Tx" SG_ 1077 CamraOvrlDyn_D_Rq 1;
BA_ "U_U55X_MY2022_Tx" SG_ 1077 CamraOvrlDyn_D_Rq 1;
BA_ "U_CD764_MY2022_Tx" SG_ 1077 CamraOvrlDyn_D_Rq 1;
BA_ "GenSigSendType" SG_ 1077 CamAutoTowbarZoom 3;
BA_ "U_CX727_MY2021_Rx" SG_ 1077 CamAutoTowbarZoom 1;
BA_ "U_P702_MY2021_Rx" SG_ 1077 CamAutoTowbarZoom 1;
BA_ "U_T6_MCA_MY2020_Rx" SG_ 1077 CamAutoTowbarZoom 1;
BA_ "U_CD542_MY2021_Rx" SG_ 1077 CamAutoTowbarZoom 1;
BA_ "U_U55X_MY2022_Rx" SG_ 1077 CamAutoTowbarZoom 1;
BA_ "U_CD764_MY2022_Rx" SG_ 1077 CamAutoTowbarZoom 1;
BA_ "U_T6_MCA_MY2020_Tx" SG_ 1077 CamAutoTowbarZoom 1;
BA_ "U_CD542_MY2021_Tx" SG_ 1077 CamAutoTowbarZoom 1;
BA_ "U_U55X_MY2022_Tx" SG_ 1077 CamAutoTowbarZoom 1;
BA_ "U_CD764_MY2022_Tx" SG_ 1077 CamAutoTowbarZoom 1;
BA_ "U_CX727_MY2021_Rx" SG_ 1077 PwLftgtIntSw_B_Stat_UB 1;
BA_ "U_P702_MY2021_Rx" SG_ 1077 PwLftgtIntSw_B_Stat_UB 1;
BA_ "U_T6_MCA_MY2020_Rx" SG_ 1077 PwLftgtIntSw_B_Stat_UB 1;
BA_ "U_CD542_MY2021_Rx" SG_ 1077 PwLftgtIntSw_B_Stat_UB 1;
BA_ "U_U55X_MY2022_Rx" SG_ 1077 PwLftgtIntSw_B_Stat_UB 1;
BA_ "U_CD764_MY2022_Rx" SG_ 1077 PwLftgtIntSw_B_Stat_UB 1;
BA_ "U_T6_MCA_MY2020_Tx" SG_ 1077 PwLftgtIntSw_B_Stat_UB 1;
BA_ "U_CD542_MY2021_Tx" SG_ 1077 PwLftgtIntSw_B_Stat_UB 1;
BA_ "U_U55X_MY2022_Tx" SG_ 1077 PwLftgtIntSw_B_Stat_UB 1;
BA_ "U_CD764_MY2022_Tx" SG_ 1077 PwLftgtIntSw_B_Stat_UB 1;
BA_ "WakeupSignal" SG_ 1077 PwLftgtIntSw_B_Stat 1;
BA_ "GenSigSendType" SG_ 1077 PwLftgtIntSw_B_Stat 3;
BA_ "U_CX727_MY2021_Rx" SG_ 1077 PwLftgtIntSw_B_Stat 1;
BA_ "U_P702_MY2021_Rx" SG_ 1077 PwLftgtIntSw_B_Stat 1;
BA_ "U_T6_MCA_MY2020_Rx" SG_ 1077 PwLftgtIntSw_B_Stat 1;
BA_ "U_CD542_MY2021_Rx" SG_ 1077 PwLftgtIntSw_B_Stat 1;
BA_ "U_U55X_MY2022_Rx" SG_ 1077 PwLftgtIntSw_B_Stat 1;
BA_ "U_CD764_MY2022_Rx" SG_ 1077 PwLftgtIntSw_B_Stat 1;
BA_ "U_T6_MCA_MY2020_Tx" SG_ 1077 PwLftgtIntSw_B_Stat 1;
BA_ "U_CD542_MY2021_Tx" SG_ 1077 PwLftgtIntSw_B_Stat 1;
BA_ "U_U55X_MY2022_Tx" SG_ 1077 PwLftgtIntSw_B_Stat 1;
BA_ "U_CD764_MY2022_Tx" SG_ 1077 PwLftgtIntSw_B_Stat 1;
BA_ "U_CX727_MY2021_Rx" SG_ 1077 TurnLampTrlrRl_B_Stat_UB 1;
BA_ "U_P702_MY2021_Rx" SG_ 1077 TurnLampTrlrRl_B_Stat_UB 1;
BA_ "U_T6_MCA_MY2020_Rx" SG_ 1077 TurnLampTrlrRl_B_Stat_UB 1;
BA_ "U_CD542_MY2021_Rx" SG_ 1077 TurnLampTrlrRl_B_Stat_UB 1;
BA_ "U_U55X_MY2022_Rx" SG_ 1077 TurnLampTrlrRl_B_Stat_UB 1;
BA_ "U_CD764_MY2022_Rx" SG_ 1077 TurnLampTrlrRl_B_Stat_UB 1;
BA_ "U_T6_MCA_MY2020_Tx" SG_ 1077 TurnLampTrlrRl_B_Stat_UB 1;
BA_ "U_CD542_MY2021_Tx" SG_ 1077 TurnLampTrlrRl_B_Stat_UB 1;
BA_ "U_U55X_MY2022_Tx" SG_ 1077 TurnLampTrlrRl_B_Stat_UB 1;
BA_ "U_CD764_MY2022_Tx" SG_ 1077 TurnLampTrlrRl_B_Stat_UB 1;
BA_ "GenSigSendType" SG_ 1077 TurnLampTrlrRr_B_Stat 3;
BA_ "U_CX727_MY2021_Rx" SG_ 1077 TurnLampTrlrRr_B_Stat 1;
BA_ "U_P702_MY2021_Rx" SG_ 1077 TurnLampTrlrRr_B_Stat 1;
BA_ "U_T6_MCA_MY2020_Rx" SG_ 1077 TurnLampTrlrRr_B_Stat 1;
BA_ "U_CD542_MY2021_Rx" SG_ 1077 TurnLampTrlrRr_B_Stat 1;
BA_ "U_U55X_MY2022_Rx" SG_ 1077 TurnLampTrlrRr_B_Stat 1;
BA_ "U_CD764_MY2022_Rx" SG_ 1077 TurnLampTrlrRr_B_Stat 1;
BA_ "U_T6_MCA_MY2020_Tx" SG_ 1077 TurnLampTrlrRr_B_Stat 1;
BA_ "U_CD542_MY2021_Tx" SG_ 1077 TurnLampTrlrRr_B_Stat 1;
BA_ "U_U55X_MY2022_Tx" SG_ 1077 TurnLampTrlrRr_B_Stat 1;
BA_ "U_CD764_MY2022_Tx" SG_ 1077 TurnLampTrlrRr_B_Stat 1;
BA_ "GenSigSendType" SG_ 1077 TurnLampTrlrRl_B_Stat 3;
BA_ "U_CX727_MY2021_Rx" SG_ 1077 TurnLampTrlrRl_B_Stat 1;
BA_ "U_P702_MY2021_Rx" SG_ 1077 TurnLampTrlrRl_B_Stat 1;
BA_ "U_T6_MCA_MY2020_Rx" SG_ 1077 TurnLampTrlrRl_B_Stat 1;
BA_ "U_CD542_MY2021_Rx" SG_ 1077 TurnLampTrlrRl_B_Stat 1;
BA_ "U_U55X_MY2022_Rx" SG_ 1077 TurnLampTrlrRl_B_Stat 1;
BA_ "U_CD764_MY2022_Rx" SG_ 1077 TurnLampTrlrRl_B_Stat 1;
BA_ "U_T6_MCA_MY2020_Tx" SG_ 1077 TurnLampTrlrRl_B_Stat 1;
BA_ "U_CD542_MY2021_Tx" SG_ 1077 TurnLampTrlrRl_B_Stat 1;
BA_ "U_U55X_MY2022_Tx" SG_ 1077 TurnLampTrlrRl_B_Stat 1;
BA_ "U_CD764_MY2022_Tx" SG_ 1077 TurnLampTrlrRl_B_Stat 1;
BA_ "U_T6_MCA_MY2020_Tx" SG_ 1077 FuelLvl_Pc_Dsply 1;
BA_ "U_CD542_MY2021_Tx" SG_ 1077 FuelLvl_Pc_Dsply 1;
BA_ "U_U55X_MY2022_Tx" SG_ 1077 FuelLvl_Pc_Dsply 1;
BA_ "U_CD764_MY2022_Tx" SG_ 1077 FuelLvl_Pc_Dsply 1;
BA_ "MetaData" SG_ 862 ApaSwtch_No_Cnt 1;
BA_ "U_CX727_MY2021_Rx" SG_ 862 HvacBlwrFront_D_Stat 1;
BA_ "U_P702_MY2021_Rx" SG_ 862 HvacBlwrFront_D_Stat 1;
BA_ "U_T6_MCA_MY2020_Rx" SG_ 862 HvacBlwrFront_D_Stat 1;
BA_ "U_CD542_MY2021_Rx" SG_ 862 HvacBlwrFront_D_Stat 1;
BA_ "U_U55X_MY2022_Rx" SG_ 862 HvacBlwrFront_D_Stat 1;
BA_ "U_CD764_MY2022_Rx" SG_ 862 HvacBlwrFront_D_Stat 1;
BA_ "U_CX727_MY2021_Rx" SG_ 862 HvacBlwrRear_D_Stat 1;
BA_ "U_P702_MY2021_Rx" SG_ 862 HvacBlwrRear_D_Stat 1;
BA_ "U_T6_MCA_MY2020_Rx" SG_ 862 HvacBlwrRear_D_Stat 1;
BA_ "U_CD542_MY2021_Rx" SG_ 862 HvacBlwrRear_D_Stat 1;
BA_ "U_U55X_MY2022_Rx" SG_ 862 HvacBlwrRear_D_Stat 1;
BA_ "U_CD764_MY2022_Rx" SG_ 862 HvacBlwrRear_D_Stat 1;
BA_ "GenSigStartValueInteger" SG_ 862 CabnAmb_Te_Actl 114;
BA_ "U_CX727_MY2021_Rx" SG_ 862 CabnAmb_Te_Actl 1;
BA_ "U_CD542_MY2021_Rx" SG_ 862 CabnAmb_Te_Actl 1;
BA_ "GenSigStartValueInteger" SG_ 862 ClimtThrmlLoad_No_Actl 255;
BA_ "GenSigStartValue" SG_ 862 ClimtThrmlLoad_No_Actl 255;
BA_ "GenSigStartValueInteger" SG_ 862 AutoStpHvacDelta_I_Est 192;
BA_ "U_CX727_MY2021_Rx" SG_ 862 AutoStpHvacDelta_I_Est 1;
BA_ "U_P702_MY2021_Rx" SG_ 862 AutoStpHvacDelta_I_Est 1;
BA_ "U_T6_MCA_MY2020_Rx" SG_ 862 AutoStpHvacDelta_I_Est 1;
BA_ "U_CD542_MY2021_Rx" SG_ 862 AutoStpHvacDelta_I_Est 1;
BA_ "U_U55X_MY2022_Rx" SG_ 862 AutoStpHvacDelta_I_Est 1;
BA_ "U_CD764_MY2022_Rx" SG_ 862 AutoStpHvacDelta_I_Est 1;
BA_ "ContentDependant" SG_ 342 EngOvrhtMitgActv_D_Ind 1;
BA_ "MetaData" SG_ 342 EngClntTe_D_Qf 1;
BA_ "U_CX727_MY2021_Rx" SG_ 342 EngClntTe_D_Qf 1;
BA_ "U_P702_MY2021_Rx" SG_ 342 EngClntTe_D_Qf 1;
BA_ "U_T6_MCA_MY2020_Rx" SG_ 342 EngClntTe_D_Qf 1;
BA_ "U_CD542_MY2021_Rx" SG_ 342 EngClntTe_D_Qf 1;
BA_ "U_U55X_MY2022_Rx" SG_ 342 EngClntTe_D_Qf 1;
BA_ "U_CD764_MY2022_Rx" SG_ 342 EngClntTe_D_Qf 1;
BA_ "ContentDependant" SG_ 342 EngGoutLss_Tq_Est 1;
BA_ "U_CX727_MY2021_Rx" SG_ 342 EngClnt_Te_Actl 1;
BA_ "U_P702_MY2021_Rx" SG_ 342 EngClnt_Te_Actl 1;
BA_ "U_T6_MCA_MY2020_Rx" SG_ 342 EngClnt_Te_Actl 1;
BA_ "U_CD542_MY2021_Rx" SG_ 342 EngClnt_Te_Actl 1;
BA_ "U_U55X_MY2022_Rx" SG_ 342 EngClnt_Te_Actl 1;
BA_ "U_CD764_MY2022_Rx" SG_ 342 EngClnt_Te_Actl 1;
BA_ "GenSigStartValueInteger" SG_ 992 MsgCntrPersIndex_D_Rq 4;
BA_ "GenSigStartValue" SG_ 992 MsgCntrPersIndex_D_Rq 4;
BA_ "U_CX727_MY2021_Rx" SG_ 992 MsgCntrPersIndex_D_Rq 1;
BA_ "U_P702_MY2021_Rx" SG_ 992 MsgCntrPersIndex_D_Rq 1;
BA_ "U_T6_MCA_MY2020_Rx" SG_ 992 MsgCntrPersIndex_D_Rq 1;
BA_ "U_CD542_MY2021_Rx" SG_ 992 MsgCntrPersIndex_D_Rq 1;
BA_ "U_U55X_MY2022_Rx" SG_ 992 MsgCntrPersIndex_D_Rq 1;
BA_ "U_CD764_MY2022_Rx" SG_ 992 MsgCntrPersIndex_D_Rq 1;
BA_ "U_CX727_MY2021_Rx" SG_ 992 MsgCntrFeatConfigRq 1;
BA_ "U_P702_MY2021_Rx" SG_ 992 MsgCntrFeatConfigRq 1;
BA_ "U_T6_MCA_MY2020_Rx" SG_ 992 MsgCntrFeatConfigRq 1;
BA_ "U_CD542_MY2021_Rx" SG_ 992 MsgCntrFeatConfigRq 1;
BA_ "U_U55X_MY2022_Rx" SG_ 992 MsgCntrFeatConfigRq 1;
BA_ "U_CD764_MY2022_Rx" SG_ 992 MsgCntrFeatConfigRq 1;
BA_ "U_CX727_MY2021_Rx" SG_ 992 MsgCntrFeatNoRq 1;
BA_ "U_P702_MY2021_Rx" SG_ 992 MsgCntrFeatNoRq 1;
BA_ "U_T6_MCA_MY2020_Rx" SG_ 992 MsgCntrFeatNoRq 1;
BA_ "U_CD542_MY2021_Rx" SG_ 992 MsgCntrFeatNoRq 1;
BA_ "U_U55X_MY2022_Rx" SG_ 992 MsgCntrFeatNoRq 1;
BA_ "U_CD764_MY2022_Rx" SG_ 992 MsgCntrFeatNoRq 1;
BA_ "U_CX727_MY2021_Rx" SG_ 992 MsgCntrDsplyOp_D_Rq 1;
BA_ "U_P702_MY2021_Rx" SG_ 992 MsgCntrDsplyOp_D_Rq 1;
BA_ "U_T6_MCA_MY2020_Rx" SG_ 992 MsgCntrDsplyOp_D_Rq 1;
BA_ "U_CD542_MY2021_Rx" SG_ 992 MsgCntrDsplyOp_D_Rq 1;
BA_ "U_U55X_MY2022_Rx" SG_ 992 MsgCntrDsplyOp_D_Rq 1;
BA_ "U_CD764_MY2022_Rx" SG_ 992 MsgCntrDsplyOp_D_Rq 1;
BA_ "WakeupSignal" SG_ 994 Pers4OptIn_B_Stats 1;
BA_ "U_CX727_MY2021_Rx" SG_ 994 Pers4OptIn_B_Stats 1;
BA_ "U_P702_MY2021_Rx" SG_ 994 Pers4OptIn_B_Stats 1;
BA_ "U_T6_MCA_MY2020_Rx" SG_ 994 Pers4OptIn_B_Stats 1;
BA_ "U_CD542_MY2021_Rx" SG_ 994 Pers4OptIn_B_Stats 1;
BA_ "U_U55X_MY2022_Rx" SG_ 994 Pers4OptIn_B_Stats 1;
BA_ "U_CD764_MY2022_Rx" SG_ 994 Pers4OptIn_B_Stats 1;
BA_ "WakeupSignal" SG_ 994 Pers3OptIn_B_Stats 1;
BA_ "U_CX727_MY2021_Rx" SG_ 994 Pers3OptIn_B_Stats 1;
BA_ "U_P702_MY2021_Rx" SG_ 994 Pers3OptIn_B_Stats 1;
BA_ "U_T6_MCA_MY2020_Rx" SG_ 994 Pers3OptIn_B_Stats 1;
BA_ "U_CD542_MY2021_Rx" SG_ 994 Pers3OptIn_B_Stats 1;
BA_ "U_U55X_MY2022_Rx" SG_ 994 Pers3OptIn_B_Stats 1;
BA_ "U_CD764_MY2022_Rx" SG_ 994 Pers3OptIn_B_Stats 1;
BA_ "WakeupSignal" SG_ 994 Pers2OptIn_B_Stats 1;
BA_ "U_CX727_MY2021_Rx" SG_ 994 Pers2OptIn_B_Stats 1;
BA_ "U_P702_MY2021_Rx" SG_ 994 Pers2OptIn_B_Stats 1;
BA_ "U_T6_MCA_MY2020_Rx" SG_ 994 Pers2OptIn_B_Stats 1;
BA_ "U_CD542_MY2021_Rx" SG_ 994 Pers2OptIn_B_Stats 1;
BA_ "U_U55X_MY2022_Rx" SG_ 994 Pers2OptIn_B_Stats 1;
BA_ "U_CD764_MY2022_Rx" SG_ 994 Pers2OptIn_B_Stats 1;
BA_ "WakeupSignal" SG_ 994 Pers1OptIn_B_Stats 1;
BA_ "U_CX727_MY2021_Rx" SG_ 994 Pers1OptIn_B_Stats 1;
BA_ "U_P702_MY2021_Rx" SG_ 994 Pers1OptIn_B_Stats 1;
BA_ "U_T6_MCA_MY2020_Rx" SG_ 994 Pers1OptIn_B_Stats 1;
BA_ "U_CD542_MY2021_Rx" SG_ 994 Pers1OptIn_B_Stats 1;
BA_ "U_U55X_MY2022_Rx" SG_ 994 Pers1OptIn_B_Stats 1;
BA_ "U_CD764_MY2022_Rx" SG_ 994 Pers1OptIn_B_Stats 1;
BA_ "GenSigStartValueInteger" SG_ 994 CtrStkPersIndex_D_Actl 4;
BA_ "GenSigStartValue" SG_ 994 CtrStkPersIndex_D_Actl 4;
BA_ "U_CX727_MY2021_Rx" SG_ 994 CtrStkPersIndex_D_Actl 1;
BA_ "U_P702_MY2021_Rx" SG_ 994 CtrStkPersIndex_D_Actl 1;
BA_ "U_T6_MCA_MY2020_Rx" SG_ 994 CtrStkPersIndex_D_Actl 1;
BA_ "U_CD542_MY2021_Rx" SG_ 994 CtrStkPersIndex_D_Actl 1;
BA_ "U_U55X_MY2022_Rx" SG_ 994 CtrStkPersIndex_D_Actl 1;
BA_ "U_CD764_MY2022_Rx" SG_ 994 CtrStkPersIndex_D_Actl 1;
BA_ "U_CX727_MY2021_Rx" SG_ 994 CtrStkFeatNoActl 1;
BA_ "U_P702_MY2021_Rx" SG_ 994 CtrStkFeatNoActl 1;
BA_ "U_T6_MCA_MY2020_Rx" SG_ 994 CtrStkFeatNoActl 1;
BA_ "U_CD542_MY2021_Rx" SG_ 994 CtrStkFeatNoActl 1;
BA_ "U_U55X_MY2022_Rx" SG_ 994 CtrStkFeatNoActl 1;
BA_ "U_CD764_MY2022_Rx" SG_ 994 CtrStkFeatNoActl 1;
BA_ "U_CX727_MY2021_Rx" SG_ 994 CtrStkFeatConfigActl 1;
BA_ "U_P702_MY2021_Rx" SG_ 994 CtrStkFeatConfigActl 1;
BA_ "U_T6_MCA_MY2020_Rx" SG_ 994 CtrStkFeatConfigActl 1;
BA_ "U_CD542_MY2021_Rx" SG_ 994 CtrStkFeatConfigActl 1;
BA_ "U_U55X_MY2022_Rx" SG_ 994 CtrStkFeatConfigActl 1;
BA_ "U_CD764_MY2022_Rx" SG_ 994 CtrStkFeatConfigActl 1;
BA_ "U_CX727_MY2021_Rx" SG_ 994 CtrStkDsplyOp_D_Rq 1;
BA_ "U_P702_MY2021_Rx" SG_ 994 CtrStkDsplyOp_D_Rq 1;
BA_ "U_T6_MCA_MY2020_Rx" SG_ 994 CtrStkDsplyOp_D_Rq 1;
BA_ "U_CD542_MY2021_Rx" SG_ 994 CtrStkDsplyOp_D_Rq 1;
BA_ "U_U55X_MY2022_Rx" SG_ 994 CtrStkDsplyOp_D_Rq 1;
BA_ "U_CD764_MY2022_Rx" SG_ 994 CtrStkDsplyOp_D_Rq 1;
BA_ "U_CX727_MY2021_Tx" SG_ 65 immoControlData_T1 1;
BA_ "U_P702_MY2021_Tx" SG_ 65 immoControlData_T1 1;
BA_ "U_T6_MCA_MY2020_Tx" SG_ 65 immoControlData_T1 1;
BA_ "U_CD542_MY2021_Tx" SG_ 65 immoControlData_T1 1;
BA_ "U_U55X_MY2022_Tx" SG_ 65 immoControlData_T1 1;
BA_ "U_CD764_MY2022_Tx" SG_ 65 immoControlData_T1 1;
BA_ "U_CX727_MY2021_Tx" SG_ 65 immoControlCmd_T1 1;
BA_ "U_P702_MY2021_Tx" SG_ 65 immoControlCmd_T1 1;
BA_ "U_T6_MCA_MY2020_Tx" SG_ 65 immoControlCmd_T1 1;
BA_ "U_CD542_MY2021_Tx" SG_ 65 immoControlCmd_T1 1;
BA_ "U_U55X_MY2022_Tx" SG_ 65 immoControlCmd_T1 1;
BA_ "U_CD764_MY2022_Tx" SG_ 65 immoControlCmd_T1 1;
BA_ "ContentDependant" SG_ 66 immoControlData_T2 1;
BA_ "U_CX727_MY2021_Rx" SG_ 66 immoControlData_T2 1;
BA_ "U_CX727_MY2021_Tx" SG_ 66 immoControlData_T2 1;
BA_ "U_P702_MY2021_Tx" SG_ 66 immoControlData_T2 1;
BA_ "U_T6_MCA_MY2020_Tx" SG_ 66 immoControlData_T2 1;
BA_ "U_CD542_MY2021_Tx" SG_ 66 immoControlData_T2 1;
BA_ "U_U55X_MY2022_Tx" SG_ 66 immoControlData_T2 1;
BA_ "U_CD764_MY2022_Tx" SG_ 66 immoControlData_T2 1;
BA_ "ContentDependant" SG_ 66 immoControlCmd_T2 1;
BA_ "U_CX727_MY2021_Rx" SG_ 66 immoControlCmd_T2 1;
BA_ "U_CX727_MY2021_Tx" SG_ 66 immoControlCmd_T2 1;
BA_ "U_P702_MY2021_Tx" SG_ 66 immoControlCmd_T2 1;
BA_ "U_T6_MCA_MY2020_Tx" SG_ 66 immoControlCmd_T2 1;
BA_ "U_CD542_MY2021_Tx" SG_ 66 immoControlCmd_T2 1;
BA_ "U_U55X_MY2022_Tx" SG_ 66 immoControlCmd_T2 1;
BA_ "U_CD764_MY2022_Tx" SG_ 66 immoControlCmd_T2 1;
BA_ "GenSigSendType" SG_ 1838 TesterPhysicalResBCM 3;
BA_ "U_CX727_MY2021_Tx" SG_ 1838 TesterPhysicalResBCM 1;
BA_ "U_P702_MY2021_Tx" SG_ 1838 TesterPhysicalResBCM 1;
BA_ "U_T6_MCA_MY2020_Tx" SG_ 1838 TesterPhysicalResBCM 1;
BA_ "U_CD542_MY2021_Tx" SG_ 1838 TesterPhysicalResBCM 1;
BA_ "U_U55X_MY2022_Tx" SG_ 1838 TesterPhysicalResBCM 1;
BA_ "U_CD764_MY2022_Tx" SG_ 1838 TesterPhysicalResBCM 1;
BA_ "GenSigSendType" SG_ 1830 TesterPhysicalReqBCM 3;
BA_ "U_CX727_MY2021_Rx" SG_ 1830 TesterPhysicalReqBCM 1;
BA_ "U_P702_MY2021_Rx" SG_ 1830 TesterPhysicalReqBCM 1;
BA_ "U_T6_MCA_MY2020_Rx" SG_ 1830 TesterPhysicalReqBCM 1;
BA_ "U_CD542_MY2021_Rx" SG_ 1830 TesterPhysicalReqBCM 1;
BA_ "U_U55X_MY2022_Rx" SG_ 1830 TesterPhysicalReqBCM 1;
BA_ "U_CD764_MY2022_Rx" SG_ 1830 TesterPhysicalReqBCM 1;
BA_ "ContentDependant" SG_ 560 SelDrvMdeSwtch_D_Stat3 1;
BA_ "ContentDependant" SG_ 560 GearLvrPosActl_No_Cs 1;
BA_ "MetaData" SG_ 560 GearLvrPosActl_No_Cs 1;
BA_ "ContentDependant" SG_ 560 GearLvrPosActl_No_Cnt 1;
BA_ "MetaData" SG_ 560 GearLvrPosActl_No_Cnt 1;
BA_ "ContentDependant" SG_ 560 TrnGbox_Rt_Actl 1;
BA_ "ContentDependant" SG_ 560 TrnSrvcRqd_B_Rq 1;
BA_ "ContentDependant" SG_ 560 TrnCnvtClu_D_Actl 1;
BA_ "ContentDependant" SG_ 560 TrnShifActv_B_Actl 1;
BA_ "GenSigStartValueInteger" SG_ 560 GearLvrPos_D_Actl 14;
BA_ "GenSigStartValue" SG_ 560 GearLvrPos_D_Actl 14;
BA_ "U_CX727_MY2021_Rx" SG_ 560 GearLvrPos_D_Actl 1;
BA_ "U_P702_MY2021_Rx" SG_ 560 GearLvrPos_D_Actl 1;
BA_ "U_T6_MCA_MY2020_Rx" SG_ 560 GearLvrPos_D_Actl 1;
BA_ "U_CD542_MY2021_Rx" SG_ 560 GearLvrPos_D_Actl 1;
BA_ "U_U55X_MY2022_Rx" SG_ 560 GearLvrPos_D_Actl 1;
BA_ "U_CD764_MY2022_Rx" SG_ 560 GearLvrPos_D_Actl 1;
BA_ "GenSigStartValueInteger" SG_ 560 GboxOil_Te_Actl 254;
BA_ "ContentDependant" SG_ 560 GboxOil_Te_Actl 1;
BA_ "GenSigStartValue" SG_ 560 GboxOil_Te_Actl 254;
BA_ "GenSigStartValueInteger" SG_ 357 BPedDrvAppl_D_QF 1;
BA_ "MetaData" SG_ 357 BPedDrvAppl_D_QF 1;
BA_ "GenSigStartValue" SG_ 357 BPedDrvAppl_D_QF 1;
BA_ "MetaData" SG_ 357 BpedDrvAppl_No_Cs 1;
BA_ "MetaData" SG_ 357 BpedDrvAppl_No_Cnt 1;
BA_ "GenSigStartValueInteger" SG_ 357 BpedDrvAppl_D_Actl 1;
BA_ "GenSigStartValue" SG_ 357 BpedDrvAppl_D_Actl 1;
BA_ "GenSigSendType" SG_ 1003 PersRecallSrc_D_Actl 3;
BA_ "U_CX727_MY2021_Tx" SG_ 1003 PersRecallSrc_D_Actl 1;
BA_ "U_P702_MY2021_Tx" SG_ 1003 PersRecallSrc_D_Actl 1;
BA_ "U_T6_MCA_MY2020_Tx" SG_ 1003 PersRecallSrc_D_Actl 1;
BA_ "U_CD542_MY2021_Tx" SG_ 1003 PersRecallSrc_D_Actl 1;
BA_ "U_U55X_MY2022_Tx" SG_ 1003 PersRecallSrc_D_Actl 1;
BA_ "U_CD764_MY2022_Tx" SG_ 1003 PersRecallSrc_D_Actl 1;
BA_ "GenSigSendType" SG_ 1003 Pers4Key_D_Stat 3;
BA_ "U_CX727_MY2021_Tx" SG_ 1003 Pers4Key_D_Stat 1;
BA_ "U_P702_MY2021_Tx" SG_ 1003 Pers4Key_D_Stat 1;
BA_ "U_T6_MCA_MY2020_Tx" SG_ 1003 Pers4Key_D_Stat 1;
BA_ "U_CD542_MY2021_Tx" SG_ 1003 Pers4Key_D_Stat 1;
BA_ "U_U55X_MY2022_Tx" SG_ 1003 Pers4Key_D_Stat 1;
BA_ "U_CD764_MY2022_Tx" SG_ 1003 Pers4Key_D_Stat 1;
BA_ "GenSigSendType" SG_ 1003 Pers3Key_D_Stat 3;
BA_ "U_CX727_MY2021_Tx" SG_ 1003 Pers3Key_D_Stat 1;
BA_ "U_P702_MY2021_Tx" SG_ 1003 Pers3Key_D_Stat 1;
BA_ "U_T6_MCA_MY2020_Tx" SG_ 1003 Pers3Key_D_Stat 1;
BA_ "U_CD542_MY2021_Tx" SG_ 1003 Pers3Key_D_Stat 1;
BA_ "U_U55X_MY2022_Tx" SG_ 1003 Pers3Key_D_Stat 1;
BA_ "U_CD764_MY2022_Tx" SG_ 1003 Pers3Key_D_Stat 1;
BA_ "GenSigSendType" SG_ 1003 Pers2Key_D_Stat 3;
BA_ "U_CX727_MY2021_Tx" SG_ 1003 Pers2Key_D_Stat 1;
BA_ "U_P702_MY2021_Tx" SG_ 1003 Pers2Key_D_Stat 1;
BA_ "U_T6_MCA_MY2020_Tx" SG_ 1003 Pers2Key_D_Stat 1;
BA_ "U_CD542_MY2021_Tx" SG_ 1003 Pers2Key_D_Stat 1;
BA_ "U_U55X_MY2022_Tx" SG_ 1003 Pers2Key_D_Stat 1;
BA_ "U_CD764_MY2022_Tx" SG_ 1003 Pers2Key_D_Stat 1;
BA_ "GenSigSendType" SG_ 1003 Pers1Key_D_Stat 3;
BA_ "U_CX727_MY2021_Tx" SG_ 1003 Pers1Key_D_Stat 1;
BA_ "U_P702_MY2021_Tx" SG_ 1003 Pers1Key_D_Stat 1;
BA_ "U_T6_MCA_MY2020_Tx" SG_ 1003 Pers1Key_D_Stat 1;
BA_ "U_CD542_MY2021_Tx" SG_ 1003 Pers1Key_D_Stat 1;
BA_ "U_U55X_MY2022_Tx" SG_ 1003 Pers1Key_D_Stat 1;
BA_ "U_CD764_MY2022_Tx" SG_ 1003 Pers1Key_D_Stat 1;
BA_ "GenSigSendType" SG_ 1003 EmPrflNo_D_Stat 3;
BA_ "U_CX727_MY2021_Tx" SG_ 1003 EmPrflNo_D_Stat 1;
BA_ "U_P702_MY2021_Tx" SG_ 1003 EmPrflNo_D_Stat 1;
BA_ "U_T6_MCA_MY2020_Tx" SG_ 1003 EmPrflNo_D_Stat 1;
BA_ "U_CD542_MY2021_Tx" SG_ 1003 EmPrflNo_D_Stat 1;
BA_ "U_U55X_MY2022_Tx" SG_ 1003 EmPrflNo_D_Stat 1;
BA_ "U_CD764_MY2022_Tx" SG_ 1003 EmPrflNo_D_Stat 1;
BA_ "GenSigSendType" SG_ 1003 EmPrflKeyAssoc_D_Stat 3;
BA_ "U_CX727_MY2021_Tx" SG_ 1003 EmPrflKeyAssoc_D_Stat 1;
BA_ "U_P702_MY2021_Tx" SG_ 1003 EmPrflKeyAssoc_D_Stat 1;
BA_ "U_T6_MCA_MY2020_Tx" SG_ 1003 EmPrflKeyAssoc_D_Stat 1;
BA_ "U_CD542_MY2021_Tx" SG_ 1003 EmPrflKeyAssoc_D_Stat 1;
BA_ "U_U55X_MY2022_Tx" SG_ 1003 EmPrflKeyAssoc_D_Stat 1;
BA_ "U_CD764_MY2022_Tx" SG_ 1003 EmPrflKeyAssoc_D_Stat 1;
BA_ "GenSigSendType" SG_ 1003 VehKeyActv_D_Stat 3;
BA_ "U_T6_MCA_MY2020_Rx" SG_ 1003 VehKeyActv_D_Stat 1;
BA_ "ECGUsedRxSignal" SG_ 1003 VehKeyActv_D_Stat 1;
BA_ "U_CD542_MY2021_Rx" SG_ 1003 VehKeyActv_D_Stat 1;
BA_ "U_U55X_MY2022_Rx" SG_ 1003 VehKeyActv_D_Stat 1;
BA_ "U_CD764_MY2022_Rx" SG_ 1003 VehKeyActv_D_Stat 1;
BA_ "U_CX727_MY2021_Tx" SG_ 1003 VehKeyActv_D_Stat 1;
BA_ "U_P702_MY2021_Tx" SG_ 1003 VehKeyActv_D_Stat 1;
BA_ "U_T6_MCA_MY2020_Tx" SG_ 1003 VehKeyActv_D_Stat 1;
BA_ "U_CD542_MY2021_Tx" SG_ 1003 VehKeyActv_D_Stat 1;
BA_ "U_U55X_MY2022_Tx" SG_ 1003 VehKeyActv_D_Stat 1;
BA_ "U_CD764_MY2022_Tx" SG_ 1003 VehKeyActv_D_Stat 1;
BA_ "GenSigStartValueInteger" SG_ 1003 PersNoPos_D_Actl 4;
BA_ "GenSigStartValue" SG_ 1003 PersNoPos_D_Actl 4;
BA_ "GenSigSendType" SG_ 1003 PersNoPos_D_Actl 3;
BA_ "U_CX727_MY2021_Tx" SG_ 1003 PersNoPos_D_Actl 1;
BA_ "U_P702_MY2021_Tx" SG_ 1003 PersNoPos_D_Actl 1;
BA_ "U_T6_MCA_MY2020_Tx" SG_ 1003 PersNoPos_D_Actl 1;
BA_ "U_CD542_MY2021_Tx" SG_ 1003 PersNoPos_D_Actl 1;
BA_ "U_U55X_MY2022_Tx" SG_ 1003 PersNoPos_D_Actl 1;
BA_ "U_CD764_MY2022_Tx" SG_ 1003 PersNoPos_D_Actl 1;
BA_ "GenSigSendType" SG_ 1003 PersSetupRestr_D_Actl 3;
BA_ "U_CX727_MY2021_Tx" SG_ 1003 PersSetupRestr_D_Actl 1;
BA_ "U_P702_MY2021_Tx" SG_ 1003 PersSetupRestr_D_Actl 1;
BA_ "U_T6_MCA_MY2020_Tx" SG_ 1003 PersSetupRestr_D_Actl 1;
BA_ "U_CD542_MY2021_Tx" SG_ 1003 PersSetupRestr_D_Actl 1;
BA_ "U_U55X_MY2022_Tx" SG_ 1003 PersSetupRestr_D_Actl 1;
BA_ "U_CD764_MY2022_Tx" SG_ 1003 PersSetupRestr_D_Actl 1;
BA_ "GenSigSendType" SG_ 1003 PersSetupAccessCtrl 3;
BA_ "U_CX727_MY2021_Tx" SG_ 1003 PersSetupAccessCtrl 1;
BA_ "U_P702_MY2021_Tx" SG_ 1003 PersSetupAccessCtrl 1;
BA_ "U_T6_MCA_MY2020_Tx" SG_ 1003 PersSetupAccessCtrl 1;
BA_ "U_CD542_MY2021_Tx" SG_ 1003 PersSetupAccessCtrl 1;
BA_ "U_U55X_MY2022_Tx" SG_ 1003 PersSetupAccessCtrl 1;
BA_ "U_CD764_MY2022_Tx" SG_ 1003 PersSetupAccessCtrl 1;
BA_ "GenSigSendType" SG_ 1003 PersSetup_No_Actl 3;
BA_ "U_CX727_MY2021_Tx" SG_ 1003 PersSetup_No_Actl 1;
BA_ "U_P702_MY2021_Tx" SG_ 1003 PersSetup_No_Actl 1;
BA_ "U_T6_MCA_MY2020_Tx" SG_ 1003 PersSetup_No_Actl 1;
BA_ "U_CD542_MY2021_Tx" SG_ 1003 PersSetup_No_Actl 1;
BA_ "U_U55X_MY2022_Tx" SG_ 1003 PersSetup_No_Actl 1;
BA_ "U_CD764_MY2022_Tx" SG_ 1003 PersSetup_No_Actl 1;
BA_ "GenSigStartValueInteger" SG_ 1003 PersConflict_D_Actl 1;
BA_ "GenSigStartValue" SG_ 1003 PersConflict_D_Actl 1;
BA_ "GenSigSendType" SG_ 1003 PersConflict_D_Actl 3;
BA_ "U_CX727_MY2021_Tx" SG_ 1003 PersConflict_D_Actl 1;
BA_ "U_P702_MY2021_Tx" SG_ 1003 PersConflict_D_Actl 1;
BA_ "U_T6_MCA_MY2020_Tx" SG_ 1003 PersConflict_D_Actl 1;
BA_ "U_CD542_MY2021_Tx" SG_ 1003 PersConflict_D_Actl 1;
BA_ "U_U55X_MY2022_Tx" SG_ 1003 PersConflict_D_Actl 1;
BA_ "U_CD764_MY2022_Tx" SG_ 1003 PersConflict_D_Actl 1;
BA_ "GenSigSendType" SG_ 1003 AssocConfirm_D_Actl 3;
BA_ "U_CX727_MY2021_Tx" SG_ 1003 AssocConfirm_D_Actl 1;
BA_ "U_P702_MY2021_Tx" SG_ 1003 AssocConfirm_D_Actl 1;
BA_ "U_T6_MCA_MY2020_Tx" SG_ 1003 AssocConfirm_D_Actl 1;
BA_ "U_CD542_MY2021_Tx" SG_ 1003 AssocConfirm_D_Actl 1;
BA_ "U_U55X_MY2022_Tx" SG_ 1003 AssocConfirm_D_Actl 1;
BA_ "U_CD764_MY2022_Tx" SG_ 1003 AssocConfirm_D_Actl 1;
BA_ "MetaData" SG_ 1003 RecallEvent_No_Cnt 1;
BA_ "GenSigSendType" SG_ 1003 RecallEvent_No_Cnt 3;
BA_ "U_CX727_MY2021_Tx" SG_ 1003 RecallEvent_No_Cnt 1;
BA_ "U_P702_MY2021_Tx" SG_ 1003 RecallEvent_No_Cnt 1;
BA_ "U_T6_MCA_MY2020_Tx" SG_ 1003 RecallEvent_No_Cnt 1;
BA_ "U_CD542_MY2021_Tx" SG_ 1003 RecallEvent_No_Cnt 1;
BA_ "U_U55X_MY2022_Tx" SG_ 1003 RecallEvent_No_Cnt 1;
BA_ "GenSigStartValueInteger" SG_ 1003 PersNo_D_Actl 4;
BA_ "GenSigStartValue" SG_ 1003 PersNo_D_Actl 4;
BA_ "GenSigSendType" SG_ 1003 PersNo_D_Actl 3;
BA_ "U_CX727_MY2021_Tx" SG_ 1003 PersNo_D_Actl 1;
BA_ "U_P702_MY2021_Tx" SG_ 1003 PersNo_D_Actl 1;
BA_ "U_T6_MCA_MY2020_Tx" SG_ 1003 PersNo_D_Actl 1;
BA_ "U_CD542_MY2021_Tx" SG_ 1003 PersNo_D_Actl 1;
BA_ "U_U55X_MY2022_Tx" SG_ 1003 PersNo_D_Actl 1;
BA_ "U_CD764_MY2022_Tx" SG_ 1003 PersNo_D_Actl 1;
BA_ "U_CX727_MY2021_Rx" SG_ 1034 VehicleGGCCData 1;
BA_ "U_P702_MY2021_Rx" SG_ 1034 VehicleGGCCData 1;
BA_ "U_CD542_MY2021_Rx" SG_ 1034 VehicleGGCCData 1;
BA_ "U_U55X_MY2022_Rx" SG_ 1034 VehicleGGCCData 1;
BA_ "U_T6_MCA_MY2020_Rx" SG_ 1034 VehicleGGCCData 1;
BA_ "U_CX727_MY2021_Tx" SG_ 1034 VehicleGGCCData 1;
BA_ "U_P702_MY2021_Tx" SG_ 1034 VehicleGGCCData 1;
BA_ "U_T6_MCA_MY2020_Tx" SG_ 1034 VehicleGGCCData 1;
BA_ "U_CD542_MY2021_Tx" SG_ 1034 VehicleGGCCData 1;
BA_ "U_U55X_MY2022_Tx" SG_ 1034 VehicleGGCCData 1;
BA_ "U_CD764_MY2022_Tx" SG_ 1034 VehicleGGCCData 1;
BA_ "U_CX727_MY2021_Tx" SG_ 1068 EngStrtInhbt_B_RqBatt 1;
BA_ "U_P702_MY2021_Tx" SG_ 1068 EngStrtInhbt_B_RqBatt 1;
BA_ "U_T6_MCA_MY2020_Tx" SG_ 1068 EngStrtInhbt_B_RqBatt 1;
BA_ "U_CD542_MY2021_Tx" SG_ 1068 EngStrtInhbt_B_RqBatt 1;
BA_ "U_U55X_MY2022_Tx" SG_ 1068 EngStrtInhbt_B_RqBatt 1;
BA_ "U_CD764_MY2022_Tx" SG_ 1068 EngStrtInhbt_B_RqBatt 1;
BA_ "U_CX727_MY2021_Tx" SG_ 1068 BattULoChrg_D_Rq 1;
BA_ "U_P702_MY2021_Tx" SG_ 1068 BattULoChrg_D_Rq 1;
BA_ "U_T6_MCA_MY2020_Tx" SG_ 1068 BattULoChrg_D_Rq 1;
BA_ "U_CD542_MY2021_Tx" SG_ 1068 BattULoChrg_D_Rq 1;
BA_ "U_U55X_MY2022_Tx" SG_ 1068 BattULoChrg_D_Rq 1;
BA_ "U_CD764_MY2022_Tx" SG_ 1068 BattULoChrg_D_Rq 1;
BA_ "WakeupSignal" SG_ 1068 PwSysULoFalt_D_Stat 1;
BA_ "U_T6_MCA_MY2020_Rx" SG_ 1068 PwSysULoFalt_D_Stat 1;
BA_ "ECGUsedRxSignal" SG_ 1068 PwSysULoFalt_D_Stat 1;
BA_ "U_CD542_MY2021_Rx" SG_ 1068 PwSysULoFalt_D_Stat 1;
BA_ "U_U55X_MY2022_Rx" SG_ 1068 PwSysULoFalt_D_Stat 1;
BA_ "U_CD764_MY2022_Rx" SG_ 1068 PwSysULoFalt_D_Stat 1;
BA_ "U_CX727_MY2021_Tx" SG_ 1068 PwSysULoFalt_D_Stat 1;
BA_ "U_P702_MY2021_Tx" SG_ 1068 PwSysULoFalt_D_Stat 1;
BA_ "U_T6_MCA_MY2020_Tx" SG_ 1068 PwSysULoFalt_D_Stat 1;
BA_ "U_CD542_MY2021_Tx" SG_ 1068 PwSysULoFalt_D_Stat 1;
BA_ "U_U55X_MY2022_Tx" SG_ 1068 PwSysULoFalt_D_Stat 1;
BA_ "U_CD764_MY2022_Tx" SG_ 1068 PwSysULoFalt_D_Stat 1;
BA_ "U_CX727_MY2021_Tx" SG_ 1068 Shed_T_Eng_Off_B 1;
BA_ "U_P702_MY2021_Tx" SG_ 1068 Shed_T_Eng_Off_B 1;
BA_ "U_T6_MCA_MY2020_Tx" SG_ 1068 Shed_T_Eng_Off_B 1;
BA_ "U_CD542_MY2021_Tx" SG_ 1068 Shed_T_Eng_Off_B 1;
BA_ "U_U55X_MY2022_Tx" SG_ 1068 Shed_T_Eng_Off_B 1;
BA_ "U_CD764_MY2022_Tx" SG_ 1068 Shed_T_Eng_Off_B 1;
BA_ "WakeupSignal" SG_ 1068 Shed_Feature_Group_ID 1;
BA_ "U_T6_MCA_MY2020_Rx" SG_ 1068 Shed_Feature_Group_ID 1;
BA_ "U_CX727_MY2021_Tx" SG_ 1068 Shed_Feature_Group_ID 1;
BA_ "U_P702_MY2021_Tx" SG_ 1068 Shed_Feature_Group_ID 1;
BA_ "U_T6_MCA_MY2020_Tx" SG_ 1068 Shed_Feature_Group_ID 1;
BA_ "U_CD542_MY2021_Tx" SG_ 1068 Shed_Feature_Group_ID 1;
BA_ "U_U55X_MY2022_Tx" SG_ 1068 Shed_Feature_Group_ID 1;
BA_ "U_CD764_MY2022_Tx" SG_ 1068 Shed_Feature_Group_ID 1;
BA_ "U_CX727_MY2021_Tx" SG_ 1068 Shed_Drain_Eng_Off_B 1;
BA_ "U_P702_MY2021_Tx" SG_ 1068 Shed_Drain_Eng_Off_B 1;
BA_ "U_T6_MCA_MY2020_Tx" SG_ 1068 Shed_Drain_Eng_Off_B 1;
BA_ "U_CD542_MY2021_Tx" SG_ 1068 Shed_Drain_Eng_Off_B 1;
BA_ "U_U55X_MY2022_Tx" SG_ 1068 Shed_Drain_Eng_Off_B 1;
BA_ "U_CD764_MY2022_Tx" SG_ 1068 Shed_Drain_Eng_Off_B 1;
BA_ "WakeupSignal" SG_ 1068 Shed_Level_Req 1;
BA_ "U_T6_MCA_MY2020_Rx" SG_ 1068 Shed_Level_Req 1;
BA_ "ECGUsedRxSignal" SG_ 1068 Shed_Level_Req 1;
BA_ "U_CD542_MY2021_Rx" SG_ 1068 Shed_Level_Req 1;
BA_ "U_U55X_MY2022_Rx" SG_ 1068 Shed_Level_Req 1;
BA_ "U_CD764_MY2022_Rx" SG_ 1068 Shed_Level_Req 1;
BA_ "U_CX727_MY2021_Tx" SG_ 1068 Shed_Level_Req 1;
BA_ "U_P702_MY2021_Tx" SG_ 1068 Shed_Level_Req 1;
BA_ "U_T6_MCA_MY2020_Tx" SG_ 1068 Shed_Level_Req 1;
BA_ "U_CD542_MY2021_Tx" SG_ 1068 Shed_Level_Req 1;
BA_ "U_U55X_MY2022_Tx" SG_ 1068 Shed_Level_Req 1;
BA_ "U_CD764_MY2022_Tx" SG_ 1068 Shed_Level_Req 1;
BA_ "U_CX727_MY2021_Tx" SG_ 1068 BattULoSrvc_T_Actl 1;
BA_ "U_P702_MY2021_Tx" SG_ 1068 BattULoSrvc_T_Actl 1;
BA_ "U_T6_MCA_MY2020_Tx" SG_ 1068 BattULoSrvc_T_Actl 1;
BA_ "U_CD542_MY2021_Tx" SG_ 1068 BattULoSrvc_T_Actl 1;
BA_ "U_U55X_MY2022_Tx" SG_ 1068 BattULoSrvc_T_Actl 1;
BA_ "U_CD764_MY2022_Tx" SG_ 1068 BattULoSrvc_T_Actl 1;
BA_ "U_CX727_MY2021_Tx" SG_ 1068 ULoRgenTestMde_B_Rq 1;
BA_ "U_P702_MY2021_Tx" SG_ 1068 ULoRgenTestMde_B_Rq 1;
BA_ "U_T6_MCA_MY2020_Tx" SG_ 1068 ULoRgenTestMde_B_Rq 1;
BA_ "U_CD542_MY2021_Tx" SG_ 1068 ULoRgenTestMde_B_Rq 1;
BA_ "U_U55X_MY2022_Tx" SG_ 1068 ULoRgenTestMde_B_Rq 1;
BA_ "U_CD764_MY2022_Tx" SG_ 1068 ULoRgenTestMde_B_Rq 1;
BA_ "U_CX727_MY2021_Tx" SG_ 1068 ChargeMode 1;
BA_ "U_P702_MY2021_Tx" SG_ 1068 ChargeMode 1;
BA_ "U_T6_MCA_MY2020_Tx" SG_ 1068 ChargeMode 1;
BA_ "U_CD542_MY2021_Tx" SG_ 1068 ChargeMode 1;
BA_ "U_U55X_MY2022_Tx" SG_ 1068 ChargeMode 1;
BA_ "U_CD764_MY2022_Tx" SG_ 1068 ChargeMode 1;
BA_ "U_CX727_MY2021_Tx" SG_ 1068 IdleSpeedIncrease_El 1;
BA_ "U_P702_MY2021_Tx" SG_ 1068 IdleSpeedIncrease_El 1;
BA_ "U_T6_MCA_MY2020_Tx" SG_ 1068 IdleSpeedIncrease_El 1;
BA_ "U_CD542_MY2021_Tx" SG_ 1068 IdleSpeedIncrease_El 1;
BA_ "U_U55X_MY2022_Tx" SG_ 1068 IdleSpeedIncrease_El 1;
BA_ "U_CD764_MY2022_Tx" SG_ 1068 IdleSpeedIncrease_El 1;
BA_ "U_CX727_MY2021_Tx" SG_ 1068 Batt_Lo_SoC_B 1;
BA_ "U_P702_MY2021_Tx" SG_ 1068 Batt_Lo_SoC_B 1;
BA_ "U_T6_MCA_MY2020_Tx" SG_ 1068 Batt_Lo_SoC_B 1;
BA_ "U_CD542_MY2021_Tx" SG_ 1068 Batt_Lo_SoC_B 1;
BA_ "U_U55X_MY2022_Tx" SG_ 1068 Batt_Lo_SoC_B 1;
BA_ "U_CD764_MY2022_Tx" SG_ 1068 Batt_Lo_SoC_B 1;
BA_ "U_CX727_MY2021_Tx" SG_ 1068 PeriodicElLoad_B_Stat 1;
BA_ "U_P702_MY2021_Tx" SG_ 1068 PeriodicElLoad_B_Stat 1;
BA_ "U_T6_MCA_MY2020_Tx" SG_ 1068 PeriodicElLoad_B_Stat 1;
BA_ "U_CD542_MY2021_Tx" SG_ 1068 PeriodicElLoad_B_Stat 1;
BA_ "U_U55X_MY2022_Tx" SG_ 1068 PeriodicElLoad_B_Stat 1;
BA_ "U_CD764_MY2022_Tx" SG_ 1068 PeriodicElLoad_B_Stat 1;
BA_ "U_T6_MCA_MY2020_Rx" SG_ 1068 Batt_Crit_SoC_B 1;
BA_ "ECGUsedRxSignal" SG_ 1068 Batt_Crit_SoC_B 1;
BA_ "U_CD542_MY2021_Rx" SG_ 1068 Batt_Crit_SoC_B 1;
BA_ "U_U55X_MY2022_Rx" SG_ 1068 Batt_Crit_SoC_B 1;
BA_ "U_CD764_MY2022_Rx" SG_ 1068 Batt_Crit_SoC_B 1;
BA_ "U_CX727_MY2021_Tx" SG_ 1068 Batt_Crit_SoC_B 1;
BA_ "U_P702_MY2021_Tx" SG_ 1068 Batt_Crit_SoC_B 1;
BA_ "U_T6_MCA_MY2020_Tx" SG_ 1068 Batt_Crit_SoC_B 1;
BA_ "U_CD542_MY2021_Tx" SG_ 1068 Batt_Crit_SoC_B 1;
BA_ "U_U55X_MY2022_Tx" SG_ 1068 Batt_Crit_SoC_B 1;
BA_ "U_CD764_MY2022_Tx" SG_ 1068 Batt_Crit_SoC_B 1;
BA_ "GenSigSendType" SG_ 947 ValetMode_D_Mem 3;
BA_ "U_CX727_MY2021_Tx" SG_ 947 ValetMode_D_Mem 1;
BA_ "U_P702_MY2021_Tx" SG_ 947 ValetMode_D_Mem 1;
BA_ "U_T6_MCA_MY2020_Tx" SG_ 947 ValetMode_D_Mem 1;
BA_ "U_CD542_MY2021_Tx" SG_ 947 ValetMode_D_Mem 1;
BA_ "U_U55X_MY2022_Tx" SG_ 947 ValetMode_D_Mem 1;
BA_ "U_CD764_MY2022_Tx" SG_ 947 ValetMode_D_Mem 1;
BA_ "WakeupSignal" SG_ 947 DimmingLvlEvnt_No_Actl 1;
BA_ "GenSigSendType" SG_ 947 DimmingLvlEvnt_No_Actl 3;
BA_ "U_CX727_MY2021_Tx" SG_ 947 DimmingLvlEvnt_No_Actl 1;
BA_ "U_P702_MY2021_Tx" SG_ 947 DimmingLvlEvnt_No_Actl 1;
BA_ "U_T6_MCA_MY2020_Tx" SG_ 947 DimmingLvlEvnt_No_Actl 1;
BA_ "U_CD542_MY2021_Tx" SG_ 947 DimmingLvlEvnt_No_Actl 1;
BA_ "U_U55X_MY2022_Tx" SG_ 947 DimmingLvlEvnt_No_Actl 1;
BA_ "U_CD764_MY2022_Tx" SG_ 947 DimmingLvlEvnt_No_Actl 1;
BA_ "GenSigSendType" SG_ 947 DrStatDrvErrCnt_B_Stat 3;
BA_ "U_CX727_MY2021_Tx" SG_ 947 DrStatDrvErrCnt_B_Stat 1;
BA_ "U_P702_MY2021_Tx" SG_ 947 DrStatDrvErrCnt_B_Stat 1;
BA_ "U_T6_MCA_MY2020_Tx" SG_ 947 DrStatDrvErrCnt_B_Stat 1;
BA_ "U_CD542_MY2021_Tx" SG_ 947 DrStatDrvErrCnt_B_Stat 1;
BA_ "U_U55X_MY2022_Tx" SG_ 947 DrStatDrvErrCnt_B_Stat 1;
BA_ "U_CD764_MY2022_Tx" SG_ 947 DrStatDrvErrCnt_B_Stat 1;
BA_ "WakeupSignal" SG_ 947 TurnLghtRight_D_Rq 1;
BA_ "GenSigSendType" SG_ 947 TurnLghtRight_D_Rq 3;
BA_ "U_CX727_MY2021_Tx" SG_ 947 TurnLghtRight_D_Rq 1;
BA_ "U_P702_MY2021_Tx" SG_ 947 TurnLghtRight_D_Rq 1;
BA_ "U_T6_MCA_MY2020_Tx" SG_ 947 TurnLghtRight_D_Rq 1;
BA_ "U_CD542_MY2021_Tx" SG_ 947 TurnLghtRight_D_Rq 1;
BA_ "U_U55X_MY2022_Tx" SG_ 947 TurnLghtRight_D_Rq 1;
BA_ "U_CD764_MY2022_Tx" SG_ 947 TurnLghtRight_D_Rq 1;
BA_ "GenSigSendType" SG_ 947 TurnLghtRightOn_B_Stat 3;
BA_ "U_CX727_MY2021_Tx" SG_ 947 TurnLghtRightOn_B_Stat 1;
BA_ "U_P702_MY2021_Tx" SG_ 947 TurnLghtRightOn_B_Stat 1;
BA_ "U_T6_MCA_MY2020_Tx" SG_ 947 TurnLghtRightOn_B_Stat 1;
BA_ "U_CD542_MY2021_Tx" SG_ 947 TurnLghtRightOn_B_Stat 1;
BA_ "U_U55X_MY2022_Tx" SG_ 947 TurnLghtRightOn_B_Stat 1;
BA_ "U_CD764_MY2022_Tx" SG_ 947 TurnLghtRightOn_B_Stat 1;
BA_ "GenSigSendType" SG_ 947 TurnLghtLeftOn_B_Stat 3;
BA_ "U_CX727_MY2021_Tx" SG_ 947 TurnLghtLeftOn_B_Stat 1;
BA_ "U_P702_MY2021_Tx" SG_ 947 TurnLghtLeftOn_B_Stat 1;
BA_ "U_T6_MCA_MY2020_Tx" SG_ 947 TurnLghtLeftOn_B_Stat 1;
BA_ "U_CD542_MY2021_Tx" SG_ 947 TurnLghtLeftOn_B_Stat 1;
BA_ "U_U55X_MY2022_Tx" SG_ 947 TurnLghtLeftOn_B_Stat 1;
BA_ "U_CD764_MY2022_Tx" SG_ 947 TurnLghtLeftOn_B_Stat 1;
BA_ "GenSigSendType" SG_ 947 FogLghtRearOn_B_Stat 3;
BA_ "U_T6_MCA_MY2020_Rx" SG_ 947 FogLghtRearOn_B_Stat 1;
BA_ "ECGUsedRxSignal" SG_ 947 FogLghtRearOn_B_Stat 1;
BA_ "U_CD542_MY2021_Rx" SG_ 947 FogLghtRearOn_B_Stat 1;
BA_ "U_U55X_MY2022_Rx" SG_ 947 FogLghtRearOn_B_Stat 1;
BA_ "U_CD764_MY2022_Rx" SG_ 947 FogLghtRearOn_B_Stat 1;
BA_ "U_CX727_MY2021_Tx" SG_ 947 FogLghtRearOn_B_Stat 1;
BA_ "U_P702_MY2021_Tx" SG_ 947 FogLghtRearOn_B_Stat 1;
BA_ "U_T6_MCA_MY2020_Tx" SG_ 947 FogLghtRearOn_B_Stat 1;
BA_ "U_CD542_MY2021_Tx" SG_ 947 FogLghtRearOn_B_Stat 1;
BA_ "U_U55X_MY2022_Tx" SG_ 947 FogLghtRearOn_B_Stat 1;
BA_ "U_CD764_MY2022_Tx" SG_ 947 FogLghtRearOn_B_Stat 1;
BA_ "WakeupSignal" SG_ 947 Backlit_LED_Status 1;
BA_ "GenSigSendType" SG_ 947 Backlit_LED_Status 3;
BA_ "U_CX727_MY2021_Tx" SG_ 947 Backlit_LED_Status 1;
BA_ "U_P702_MY2021_Tx" SG_ 947 Backlit_LED_Status 1;
BA_ "U_T6_MCA_MY2020_Tx" SG_ 947 Backlit_LED_Status 1;
BA_ "U_CD542_MY2021_Tx" SG_ 947 Backlit_LED_Status 1;
BA_ "U_U55X_MY2022_Tx" SG_ 947 Backlit_LED_Status 1;
BA_ "U_CD764_MY2022_Tx" SG_ 947 Backlit_LED_Status 1;
BA_ "WakeupSignal" SG_ 947 TurnLghtLeft_D_Rq 1;
BA_ "GenSigSendType" SG_ 947 TurnLghtLeft_D_Rq 3;
BA_ "U_CX727_MY2021_Tx" SG_ 947 TurnLghtLeft_D_Rq 1;
BA_ "U_P702_MY2021_Tx" SG_ 947 TurnLghtLeft_D_Rq 1;
BA_ "U_T6_MCA_MY2020_Tx" SG_ 947 TurnLghtLeft_D_Rq 1;
BA_ "U_CD542_MY2021_Tx" SG_ 947 TurnLghtLeft_D_Rq 1;
BA_ "U_U55X_MY2022_Tx" SG_ 947 TurnLghtLeft_D_Rq 1;
BA_ "U_CD764_MY2022_Tx" SG_ 947 TurnLghtLeft_D_Rq 1;
BA_ "GenSigSendType" SG_ 947 FogLghtFrontOn_B_Stat 3;
BA_ "U_T6_MCA_MY2020_Rx" SG_ 947 FogLghtFrontOn_B_Stat 1;
BA_ "ECGUsedRxSignal" SG_ 947 FogLghtFrontOn_B_Stat 1;
BA_ "U_CD542_MY2021_Rx" SG_ 947 FogLghtFrontOn_B_Stat 1;
BA_ "U_U55X_MY2022_Rx" SG_ 947 FogLghtFrontOn_B_Stat 1;
BA_ "U_CD764_MY2022_Rx" SG_ 947 FogLghtFrontOn_B_Stat 1;
BA_ "U_CX727_MY2021_Tx" SG_ 947 FogLghtFrontOn_B_Stat 1;
BA_ "U_P702_MY2021_Tx" SG_ 947 FogLghtFrontOn_B_Stat 1;
BA_ "U_T6_MCA_MY2020_Tx" SG_ 947 FogLghtFrontOn_B_Stat 1;
BA_ "U_CD542_MY2021_Tx" SG_ 947 FogLghtFrontOn_B_Stat 1;
BA_ "U_U55X_MY2022_Tx" SG_ 947 FogLghtFrontOn_B_Stat 1;
BA_ "U_CD764_MY2022_Tx" SG_ 947 FogLghtFrontOn_B_Stat 1;
BA_ "GenSigStartValueInteger" SG_ 947 IgnKeyType_D_Actl 14;
BA_ "GenSigStartValue" SG_ 947 IgnKeyType_D_Actl 14;
BA_ "GenSigSendType" SG_ 947 IgnKeyType_D_Actl 3;
BA_ "U_CX727_MY2021_Tx" SG_ 947 IgnKeyType_D_Actl 1;
BA_ "U_P702_MY2021_Tx" SG_ 947 IgnKeyType_D_Actl 1;
BA_ "U_T6_MCA_MY2020_Tx" SG_ 947 IgnKeyType_D_Actl 1;
BA_ "U_CD542_MY2021_Tx" SG_ 947 IgnKeyType_D_Actl 1;
BA_ "U_U55X_MY2022_Tx" SG_ 947 IgnKeyType_D_Actl 1;
BA_ "U_CD764_MY2022_Tx" SG_ 947 IgnKeyType_D_Actl 1;
BA_ "WakeupSignal" SG_ 947 Parklamp_Status 1;
BA_ "GenSigStartValueInteger" SG_ 947 Parklamp_Status 1;
BA_ "GenSigStartValue" SG_ 947 Parklamp_Status 1;
BA_ "GenSigSendType" SG_ 947 Parklamp_Status 3;
BA_ "U_T6_MCA_MY2020_Rx" SG_ 947 Parklamp_Status 1;
BA_ "ECGUsedRxSignal" SG_ 947 Parklamp_Status 1;
BA_ "U_CD542_MY2021_Rx" SG_ 947 Parklamp_Status 1;
BA_ "U_U55X_MY2022_Rx" SG_ 947 Parklamp_Status 1;
BA_ "U_CD764_MY2022_Rx" SG_ 947 Parklamp_Status 1;
BA_ "U_CX727_MY2021_Tx" SG_ 947 Parklamp_Status 1;
BA_ "U_P702_MY2021_Tx" SG_ 947 Parklamp_Status 1;
BA_ "U_T6_MCA_MY2020_Tx" SG_ 947 Parklamp_Status 1;
BA_ "U_CD542_MY2021_Tx" SG_ 947 Parklamp_Status 1;
BA_ "U_U55X_MY2022_Tx" SG_ 947 Parklamp_Status 1;
BA_ "U_CD764_MY2022_Tx" SG_ 947 Parklamp_Status 1;
BA_ "WakeupSignal" SG_ 947 Litval 1;
BA_ "GenSigSendType" SG_ 947 Litval 3;
BA_ "U_CX727_MY2021_Tx" SG_ 947 Litval 1;
BA_ "U_P702_MY2021_Tx" SG_ 947 Litval 1;
BA_ "U_T6_MCA_MY2020_Tx" SG_ 947 Litval 1;
BA_ "U_CD542_MY2021_Tx" SG_ 947 Litval 1;
BA_ "U_U55X_MY2022_Tx" SG_ 947 Litval 1;
BA_ "U_CD764_MY2022_Tx" SG_ 947 Litval 1;
BA_ "WakeupSignal" SG_ 947 Key_In_Ignition_Stat 1;
BA_ "GenSigSendType" SG_ 947 Key_In_Ignition_Stat 3;
BA_ "U_CX727_MY2021_Tx" SG_ 947 Key_In_Ignition_Stat 1;
BA_ "U_P702_MY2021_Tx" SG_ 947 Key_In_Ignition_Stat 1;
BA_ "U_T6_MCA_MY2020_Tx" SG_ 947 Key_In_Ignition_Stat 1;
BA_ "U_CD542_MY2021_Tx" SG_ 947 Key_In_Ignition_Stat 1;
BA_ "U_U55X_MY2022_Tx" SG_ 947 Key_In_Ignition_Stat 1;
BA_ "U_CD764_MY2022_Tx" SG_ 947 Key_In_Ignition_Stat 1;
BA_ "WakeupSignal" SG_ 947 Ignition_Status 1;
BA_ "GenSigSendType" SG_ 947 Ignition_Status 3;
BA_ "U_CX727_MY2021_Rx" SG_ 947 Ignition_Status 1;
BA_ "U_P702_MY2021_Rx" SG_ 947 Ignition_Status 1;
BA_ "U_CD542_MY2021_Rx" SG_ 947 Ignition_Status 1;
BA_ "U_U55X_MY2022_Rx" SG_ 947 Ignition_Status 1;
BA_ "U_T6_MCA_MY2020_Rx" SG_ 947 Ignition_Status 1;
BA_ "U_CD764_MY2022_Rx" SG_ 947 Ignition_Status 1;
BA_ "ECGUsedRxSignal" SG_ 947 Ignition_Status 1;
BA_ "U_CX727_MY2021_Tx" SG_ 947 Ignition_Status 1;
BA_ "U_P702_MY2021_Tx" SG_ 947 Ignition_Status 1;
BA_ "U_T6_MCA_MY2020_Tx" SG_ 947 Ignition_Status 1;
BA_ "U_CD542_MY2021_Tx" SG_ 947 Ignition_Status 1;
BA_ "U_U55X_MY2022_Tx" SG_ 947 Ignition_Status 1;
BA_ "U_CD764_MY2022_Tx" SG_ 947 Ignition_Status 1;
BA_ "WakeupSignal" SG_ 947 Dimming_Lvl 1;
BA_ "GenSigStartValueInteger" SG_ 947 Dimming_Lvl 12;
BA_ "GenSigStartValue" SG_ 947 Dimming_Lvl 12;
BA_ "GenSigSendType" SG_ 947 Dimming_Lvl 3;
BA_ "U_P702_MY2021_Rx" SG_ 947 Dimming_Lvl 1;
BA_ "U_CX727_MY2021_Tx" SG_ 947 Dimming_Lvl 1;
BA_ "U_P702_MY2021_Tx" SG_ 947 Dimming_Lvl 1;
BA_ "U_T6_MCA_MY2020_Tx" SG_ 947 Dimming_Lvl 1;
BA_ "U_CD542_MY2021_Tx" SG_ 947 Dimming_Lvl 1;
BA_ "U_U55X_MY2022_Tx" SG_ 947 Dimming_Lvl 1;
BA_ "U_CD764_MY2022_Tx" SG_ 947 Dimming_Lvl 1;
BA_ "WakeupSignal" SG_ 947 Day_Night_Status 1;
BA_ "GenSigSendType" SG_ 947 Day_Night_Status 3;
BA_ "U_CX727_MY2021_Rx" SG_ 947 Day_Night_Status 1;
BA_ "U_CD542_MY2021_Rx" SG_ 947 Day_Night_Status 1;
BA_ "U_CX727_MY2021_Tx" SG_ 947 Day_Night_Status 1;
BA_ "U_P702_MY2021_Tx" SG_ 947 Day_Night_Status 1;
BA_ "U_T6_MCA_MY2020_Tx" SG_ 947 Day_Night_Status 1;
BA_ "U_CD542_MY2021_Tx" SG_ 947 Day_Night_Status 1;
BA_ "U_U55X_MY2022_Tx" SG_ 947 Day_Night_Status 1;
BA_ "U_CD764_MY2022_Tx" SG_ 947 Day_Night_Status 1;
BA_ "WakeupSignal" SG_ 947 Remote_Start_Status 1;
BA_ "GenSigSendType" SG_ 947 Remote_Start_Status 3;
BA_ "U_CX727_MY2021_Rx" SG_ 947 Remote_Start_Status 1;
BA_ "U_P702_MY2021_Rx" SG_ 947 Remote_Start_Status 1;
BA_ "U_T6_MCA_MY2020_Rx" SG_ 947 Remote_Start_Status 1;
BA_ "U_CD542_MY2021_Rx" SG_ 947 Remote_Start_Status 1;
BA_ "U_U55X_MY2022_Rx" SG_ 947 Remote_Start_Status 1;
BA_ "U_CD764_MY2022_Rx" SG_ 947 Remote_Start_Status 1;
BA_ "U_CX727_MY2021_Tx" SG_ 947 Remote_Start_Status 1;
BA_ "U_P702_MY2021_Tx" SG_ 947 Remote_Start_Status 1;
BA_ "U_T6_MCA_MY2020_Tx" SG_ 947 Remote_Start_Status 1;
BA_ "U_CD542_MY2021_Tx" SG_ 947 Remote_Start_Status 1;
BA_ "U_U55X_MY2022_Tx" SG_ 947 Remote_Start_Status 1;
BA_ "U_CD764_MY2022_Tx" SG_ 947 Remote_Start_Status 1;
BA_ "WakeupSignal" SG_ 947 DrStatTgate_B_Actl 1;
BA_ "GenSigSendType" SG_ 947 DrStatTgate_B_Actl 3;
BA_ "U_T6_MCA_MY2020_Rx" SG_ 947 DrStatTgate_B_Actl 1;
BA_ "ECGUsedRxSignal" SG_ 947 DrStatTgate_B_Actl 1;
BA_ "U_CD542_MY2021_Rx" SG_ 947 DrStatTgate_B_Actl 1;
BA_ "U_U55X_MY2022_Rx" SG_ 947 DrStatTgate_B_Actl 1;
BA_ "U_CD764_MY2022_Rx" SG_ 947 DrStatTgate_B_Actl 1;
BA_ "U_CX727_MY2021_Tx" SG_ 947 DrStatTgate_B_Actl 1;
BA_ "U_P702_MY2021_Tx" SG_ 947 DrStatTgate_B_Actl 1;
BA_ "U_T6_MCA_MY2020_Tx" SG_ 947 DrStatTgate_B_Actl 1;
BA_ "U_CD542_MY2021_Tx" SG_ 947 DrStatTgate_B_Actl 1;
BA_ "U_U55X_MY2022_Tx" SG_ 947 DrStatTgate_B_Actl 1;
BA_ "U_CD764_MY2022_Tx" SG_ 947 DrStatTgate_B_Actl 1;
BA_ "WakeupSignal" SG_ 947 DrStatRr_B_Actl 1;
BA_ "GenSigSendType" SG_ 947 DrStatRr_B_Actl 3;
BA_ "U_T6_MCA_MY2020_Rx" SG_ 947 DrStatRr_B_Actl 1;
BA_ "ECGUsedRxSignal" SG_ 947 DrStatRr_B_Actl 1;
BA_ "U_CD542_MY2021_Rx" SG_ 947 DrStatRr_B_Actl 1;
BA_ "U_U55X_MY2022_Rx" SG_ 947 DrStatRr_B_Actl 1;
BA_ "U_CD764_MY2022_Rx" SG_ 947 DrStatRr_B_Actl 1;
BA_ "U_CX727_MY2021_Tx" SG_ 947 DrStatRr_B_Actl 1;
BA_ "U_P702_MY2021_Tx" SG_ 947 DrStatRr_B_Actl 1;
BA_ "U_T6_MCA_MY2020_Tx" SG_ 947 DrStatRr_B_Actl 1;
BA_ "U_CD542_MY2021_Tx" SG_ 947 DrStatRr_B_Actl 1;
BA_ "U_U55X_MY2022_Tx" SG_ 947 DrStatRr_B_Actl 1;
BA_ "U_CD764_MY2022_Tx" SG_ 947 DrStatRr_B_Actl 1;
BA_ "WakeupSignal" SG_ 947 DrStatRl_B_Actl 1;
BA_ "GenSigSendType" SG_ 947 DrStatRl_B_Actl 3;
BA_ "U_T6_MCA_MY2020_Rx" SG_ 947 DrStatRl_B_Actl 1;
BA_ "ECGUsedRxSignal" SG_ 947 DrStatRl_B_Actl 1;
BA_ "U_CD542_MY2021_Rx" SG_ 947 DrStatRl_B_Actl 1;
BA_ "U_U55X_MY2022_Rx" SG_ 947 DrStatRl_B_Actl 1;
BA_ "U_CD764_MY2022_Rx" SG_ 947 DrStatRl_B_Actl 1;
BA_ "U_CX727_MY2021_Tx" SG_ 947 DrStatRl_B_Actl 1;
BA_ "U_P702_MY2021_Tx" SG_ 947 DrStatRl_B_Actl 1;
BA_ "U_T6_MCA_MY2020_Tx" SG_ 947 DrStatRl_B_Actl 1;
BA_ "U_CD542_MY2021_Tx" SG_ 947 DrStatRl_B_Actl 1;
BA_ "U_U55X_MY2022_Tx" SG_ 947 DrStatRl_B_Actl 1;
BA_ "U_CD764_MY2022_Tx" SG_ 947 DrStatRl_B_Actl 1;
BA_ "WakeupSignal" SG_ 947 DrStatPsngr_B_Actl 1;
BA_ "GenSigSendType" SG_ 947 DrStatPsngr_B_Actl 3;
BA_ "U_T6_MCA_MY2020_Rx" SG_ 947 DrStatPsngr_B_Actl 1;
BA_ "ECGUsedRxSignal" SG_ 947 DrStatPsngr_B_Actl 1;
BA_ "U_CD542_MY2021_Rx" SG_ 947 DrStatPsngr_B_Actl 1;
BA_ "U_U55X_MY2022_Rx" SG_ 947 DrStatPsngr_B_Actl 1;
BA_ "U_CD764_MY2022_Rx" SG_ 947 DrStatPsngr_B_Actl 1;
BA_ "U_CX727_MY2021_Tx" SG_ 947 DrStatPsngr_B_Actl 1;
BA_ "U_P702_MY2021_Tx" SG_ 947 DrStatPsngr_B_Actl 1;
BA_ "U_T6_MCA_MY2020_Tx" SG_ 947 DrStatPsngr_B_Actl 1;
BA_ "U_CD542_MY2021_Tx" SG_ 947 DrStatPsngr_B_Actl 1;
BA_ "U_U55X_MY2022_Tx" SG_ 947 DrStatPsngr_B_Actl 1;
BA_ "U_CD764_MY2022_Tx" SG_ 947 DrStatPsngr_B_Actl 1;
BA_ "WakeupSignal" SG_ 947 DrStatInnrTgate_B_Actl 1;
BA_ "GenSigSendType" SG_ 947 DrStatInnrTgate_B_Actl 3;
BA_ "U_T6_MCA_MY2020_Rx" SG_ 947 DrStatInnrTgate_B_Actl 1;
BA_ "ECGUsedRxSignal" SG_ 947 DrStatInnrTgate_B_Actl 1;
BA_ "U_CD542_MY2021_Rx" SG_ 947 DrStatInnrTgate_B_Actl 1;
BA_ "U_U55X_MY2022_Rx" SG_ 947 DrStatInnrTgate_B_Actl 1;
BA_ "U_CD764_MY2022_Rx" SG_ 947 DrStatInnrTgate_B_Actl 1;
BA_ "U_CX727_MY2021_Tx" SG_ 947 DrStatInnrTgate_B_Actl 1;
BA_ "U_P702_MY2021_Tx" SG_ 947 DrStatInnrTgate_B_Actl 1;
BA_ "U_T6_MCA_MY2020_Tx" SG_ 947 DrStatInnrTgate_B_Actl 1;
BA_ "U_CD542_MY2021_Tx" SG_ 947 DrStatInnrTgate_B_Actl 1;
BA_ "U_U55X_MY2022_Tx" SG_ 947 DrStatInnrTgate_B_Actl 1;
BA_ "U_CD764_MY2022_Tx" SG_ 947 DrStatInnrTgate_B_Actl 1;
BA_ "WakeupSignal" SG_ 947 DrStatHood_B_Actl 1;
BA_ "GenSigSendType" SG_ 947 DrStatHood_B_Actl 3;
BA_ "U_T6_MCA_MY2020_Rx" SG_ 947 DrStatHood_B_Actl 1;
BA_ "ECGUsedRxSignal" SG_ 947 DrStatHood_B_Actl 1;
BA_ "U_CD542_MY2021_Rx" SG_ 947 DrStatHood_B_Actl 1;
BA_ "U_U55X_MY2022_Rx" SG_ 947 DrStatHood_B_Actl 1;
BA_ "U_CD764_MY2022_Rx" SG_ 947 DrStatHood_B_Actl 1;
BA_ "U_CX727_MY2021_Tx" SG_ 947 DrStatHood_B_Actl 1;
BA_ "U_P702_MY2021_Tx" SG_ 947 DrStatHood_B_Actl 1;
BA_ "U_T6_MCA_MY2020_Tx" SG_ 947 DrStatHood_B_Actl 1;
BA_ "U_CD542_MY2021_Tx" SG_ 947 DrStatHood_B_Actl 1;
BA_ "U_U55X_MY2022_Tx" SG_ 947 DrStatHood_B_Actl 1;
BA_ "U_CD764_MY2022_Tx" SG_ 947 DrStatHood_B_Actl 1;
BA_ "WakeupSignal" SG_ 947 DrStatDrv_B_Actl 1;
BA_ "GenSigSendType" SG_ 947 DrStatDrv_B_Actl 3;
BA_ "U_T6_MCA_MY2020_Rx" SG_ 947 DrStatDrv_B_Actl 1;
BA_ "ECGUsedRxSignal" SG_ 947 DrStatDrv_B_Actl 1;
BA_ "U_CD542_MY2021_Rx" SG_ 947 DrStatDrv_B_Actl 1;
BA_ "U_U55X_MY2022_Rx" SG_ 947 DrStatDrv_B_Actl 1;
BA_ "U_CD764_MY2022_Rx" SG_ 947 DrStatDrv_B_Actl 1;
BA_ "U_CX727_MY2021_Tx" SG_ 947 DrStatDrv_B_Actl 1;
BA_ "U_P702_MY2021_Tx" SG_ 947 DrStatDrv_B_Actl 1;
BA_ "U_T6_MCA_MY2020_Tx" SG_ 947 DrStatDrv_B_Actl 1;
BA_ "U_CD542_MY2021_Tx" SG_ 947 DrStatDrv_B_Actl 1;
BA_ "U_U55X_MY2022_Tx" SG_ 947 DrStatDrv_B_Actl 1;
BA_ "U_CD764_MY2022_Tx" SG_ 947 DrStatDrv_B_Actl 1;
BA_ "WakeupSignal" SG_ 947 PrkBrkActv_B_Actl 1;
BA_ "ContentDependant" SG_ 947 PrkBrkActv_B_Actl 1;
BA_ "GenSigSendType" SG_ 947 PrkBrkActv_B_Actl 3;
BA_ "U_T6_MCA_MY2020_Rx" SG_ 947 PrkBrkActv_B_Actl 1;
BA_ "ECGUsedRxSignal" SG_ 947 PrkBrkActv_B_Actl 1;
BA_ "U_CD542_MY2021_Rx" SG_ 947 PrkBrkActv_B_Actl 1;
BA_ "U_U55X_MY2022_Rx" SG_ 947 PrkBrkActv_B_Actl 1;
BA_ "U_CD764_MY2022_Rx" SG_ 947 PrkBrkActv_B_Actl 1;
BA_ "U_CX727_MY2021_Tx" SG_ 947 PrkBrkActv_B_Actl 1;
BA_ "U_P702_MY2021_Tx" SG_ 947 PrkBrkActv_B_Actl 1;
BA_ "U_T6_MCA_MY2020_Tx" SG_ 947 PrkBrkActv_B_Actl 1;
BA_ "U_CD542_MY2021_Tx" SG_ 947 PrkBrkActv_B_Actl 1;
BA_ "U_U55X_MY2022_Tx" SG_ 947 PrkBrkActv_B_Actl 1;
BA_ "U_CD764_MY2022_Tx" SG_ 947 PrkBrkActv_B_Actl 1;
BA_ "GenSigSendType" SG_ 947 LifeCycMde_D_Actl 3;
BA_ "U_CX727_MY2021_Rx" SG_ 947 LifeCycMde_D_Actl 1;
BA_ "U_P702_MY2021_Rx" SG_ 947 LifeCycMde_D_Actl 1;
BA_ "U_CD542_MY2021_Rx" SG_ 947 LifeCycMde_D_Actl 1;
BA_ "U_T6_MCA_MY2020_Rx" SG_ 947 LifeCycMde_D_Actl 1;
BA_ "U_U55X_MY2022_Rx" SG_ 947 LifeCycMde_D_Actl 1;
BA_ "U_CD764_MY2022_Rx" SG_ 947 LifeCycMde_D_Actl 1;
BA_ "ECGUsedRxSignal" SG_ 947 LifeCycMde_D_Actl 1;
BA_ "U_CX727_MY2021_Tx" SG_ 947 LifeCycMde_D_Actl 1;
BA_ "U_P702_MY2021_Tx" SG_ 947 LifeCycMde_D_Actl 1;
BA_ "U_T6_MCA_MY2020_Tx" SG_ 947 LifeCycMde_D_Actl 1;
BA_ "U_CD542_MY2021_Tx" SG_ 947 LifeCycMde_D_Actl 1;
BA_ "U_U55X_MY2022_Tx" SG_ 947 LifeCycMde_D_Actl 1;
BA_ "U_CD764_MY2022_Tx" SG_ 947 LifeCycMde_D_Actl 1;
BA_ "WakeupSignal" SG_ 947 Delay_Accy 1;
BA_ "GenSigSendType" SG_ 947 Delay_Accy 3;
BA_ "U_T6_MCA_MY2020_Rx" SG_ 947 Delay_Accy 1;
BA_ "ECGUsedRxSignal" SG_ 947 Delay_Accy 1;
BA_ "U_CD542_MY2021_Rx" SG_ 947 Delay_Accy 1;
BA_ "U_U55X_MY2022_Rx" SG_ 947 Delay_Accy 1;
BA_ "U_CD764_MY2022_Rx" SG_ 947 Delay_Accy 1;
BA_ "U_CX727_MY2021_Tx" SG_ 947 Delay_Accy 1;
BA_ "U_P702_MY2021_Tx" SG_ 947 Delay_Accy 1;
BA_ "U_T6_MCA_MY2020_Tx" SG_ 947 Delay_Accy 1;
BA_ "U_CD542_MY2021_Tx" SG_ 947 Delay_Accy 1;
BA_ "U_U55X_MY2022_Tx" SG_ 947 Delay_Accy 1;
BA_ "U_CD764_MY2022_Tx" SG_ 947 Delay_Accy 1;
BA_ "WakeupSignal" SG_ 947 CrashEvnt_D_Stat 1;
BA_ "GenSigStartValueInteger" SG_ 947 CrashEvnt_D_Stat 3;
BA_ "GenSigStartValue" SG_ 947 CrashEvnt_D_Stat 3;
BA_ "GenSigSendType" SG_ 947 CrashEvnt_D_Stat 3;
BA_ "U_CX727_MY2021_Tx" SG_ 947 CrashEvnt_D_Stat 1;
BA_ "U_P702_MY2021_Tx" SG_ 947 CrashEvnt_D_Stat 1;
BA_ "U_T6_MCA_MY2020_Tx" SG_ 947 CrashEvnt_D_Stat 1;
BA_ "U_CD542_MY2021_Tx" SG_ 947 CrashEvnt_D_Stat 1;
BA_ "U_U55X_MY2022_Tx" SG_ 947 CrashEvnt_D_Stat 1;
BA_ "U_CD764_MY2022_Tx" SG_ 947 CrashEvnt_D_Stat 1;
BA_ "GenSigSendType" SG_ 947 FuelPmpInhbt_B_Stat 3;
BA_ "U_CX727_MY2021_Tx" SG_ 947 FuelPmpInhbt_B_Stat 1;
BA_ "U_P702_MY2021_Tx" SG_ 947 FuelPmpInhbt_B_Stat 1;
BA_ "U_T6_MCA_MY2020_Tx" SG_ 947 FuelPmpInhbt_B_Stat 1;
BA_ "U_CD542_MY2021_Tx" SG_ 947 FuelPmpInhbt_B_Stat 1;
BA_ "U_U55X_MY2022_Tx" SG_ 947 FuelPmpInhbt_B_Stat 1;
BA_ "U_CD764_MY2022_Tx" SG_ 947 FuelPmpInhbt_B_Stat 1;
BA_ "GenSigSendType" SG_ 947 BodySrvcRqd_B_Rq 3;
BA_ "U_CX727_MY2021_Tx" SG_ 947 BodySrvcRqd_B_Rq 1;
BA_ "U_P702_MY2021_Tx" SG_ 947 BodySrvcRqd_B_Rq 1;
BA_ "U_T6_MCA_MY2020_Tx" SG_ 947 BodySrvcRqd_B_Rq 1;
BA_ "U_CD542_MY2021_Tx" SG_ 947 BodySrvcRqd_B_Rq 1;
BA_ "U_U55X_MY2022_Tx" SG_ 947 BodySrvcRqd_B_Rq 1;
BA_ "U_CD764_MY2022_Tx" SG_ 947 BodySrvcRqd_B_Rq 1;
BA_ "GenSigStartValue" SG_ 986 Trlr_M_Rq 2046;
BA_ "U_CX727_MY2021_Rx" SG_ 986 LightAmbIntsty_No_Rq 1;
BA_ "U_P702_MY2021_Rx" SG_ 986 LightAmbIntsty_No_Rq 1;
BA_ "U_T6_MCA_MY2020_Rx" SG_ 986 LightAmbIntsty_No_Rq 1;
BA_ "U_CD542_MY2021_Rx" SG_ 986 LightAmbIntsty_No_Rq 1;
BA_ "U_U55X_MY2022_Rx" SG_ 986 LightAmbIntsty_No_Rq 1;
BA_ "U_CD764_MY2022_Rx" SG_ 986 LightAmbIntsty_No_Rq 1;
BA_ "U_CX727_MY2021_Rx" SG_ 986 LightAmbColor_No_Rq 1;
BA_ "U_P702_MY2021_Rx" SG_ 986 LightAmbColor_No_Rq 1;
BA_ "U_T6_MCA_MY2020_Rx" SG_ 986 LightAmbColor_No_Rq 1;
BA_ "U_CD542_MY2021_Rx" SG_ 986 LightAmbColor_No_Rq 1;
BA_ "U_U55X_MY2022_Rx" SG_ 986 LightAmbColor_No_Rq 1;
BA_ "U_CD764_MY2022_Rx" SG_ 986 LightAmbColor_No_Rq 1;
BA_ "GenSigSendType" SG_ 995 KeyAssocCmplt_B_Rq 3;
BA_ "U_P702_MY2021_Tx" SG_ 995 KeyAssocCmplt_B_Rq 1;
BA_ "U_T6_MCA_MY2020_Tx" SG_ 995 KeyAssocCmplt_B_Rq 1;
BA_ "U_CD542_MY2021_Tx" SG_ 995 KeyAssocCmplt_B_Rq 1;
BA_ "U_U55X_MY2022_Tx" SG_ 995 KeyAssocCmplt_B_Rq 1;
BA_ "U_CD764_MY2022_Tx" SG_ 995 KeyAssocCmplt_B_Rq 1;
BA_ "GenSigSendType" SG_ 995 FobAssocChime_B_Rq 3;
BA_ "U_CX727_MY2021_Tx" SG_ 995 FobAssocChime_B_Rq 1;
BA_ "U_P702_MY2021_Tx" SG_ 995 FobAssocChime_B_Rq 1;
BA_ "U_T6_MCA_MY2020_Tx" SG_ 995 FobAssocChime_B_Rq 1;
BA_ "U_CD542_MY2021_Tx" SG_ 995 FobAssocChime_B_Rq 1;
BA_ "U_U55X_MY2022_Tx" SG_ 995 FobAssocChime_B_Rq 1;
BA_ "U_CD764_MY2022_Tx" SG_ 995 FobAssocChime_B_Rq 1;
BA_ "GenSigSendType" SG_ 995 LightAmbIntsty_No_Actl 3;
BA_ "U_CX727_MY2021_Tx" SG_ 995 LightAmbIntsty_No_Actl 1;
BA_ "U_P702_MY2021_Tx" SG_ 995 LightAmbIntsty_No_Actl 1;
BA_ "U_T6_MCA_MY2020_Tx" SG_ 995 LightAmbIntsty_No_Actl 1;
BA_ "U_CD542_MY2021_Tx" SG_ 995 LightAmbIntsty_No_Actl 1;
BA_ "U_U55X_MY2022_Tx" SG_ 995 LightAmbIntsty_No_Actl 1;
BA_ "U_CD764_MY2022_Tx" SG_ 995 LightAmbIntsty_No_Actl 1;
BA_ "GenSigStartValueInteger" SG_ 995 PersIndexBcm_D_Actl 4;
BA_ "GenSigStartValue" SG_ 995 PersIndexBcm_D_Actl 4;
BA_ "GenSigSendType" SG_ 995 PersIndexBcm_D_Actl 3;
BA_ "U_CX727_MY2021_Tx" SG_ 995 PersIndexBcm_D_Actl 1;
BA_ "U_P702_MY2021_Tx" SG_ 995 PersIndexBcm_D_Actl 1;
BA_ "U_T6_MCA_MY2020_Tx" SG_ 995 PersIndexBcm_D_Actl 1;
BA_ "U_CD542_MY2021_Tx" SG_ 995 PersIndexBcm_D_Actl 1;
BA_ "U_U55X_MY2022_Tx" SG_ 995 PersIndexBcm_D_Actl 1;
BA_ "U_CD764_MY2022_Tx" SG_ 995 PersIndexBcm_D_Actl 1;
BA_ "GenSigSendType" SG_ 995 FeatNoBcm_No_Actl 3;
BA_ "U_CX727_MY2021_Tx" SG_ 995 FeatNoBcm_No_Actl 1;
BA_ "U_P702_MY2021_Tx" SG_ 995 FeatNoBcm_No_Actl 1;
BA_ "U_T6_MCA_MY2020_Tx" SG_ 995 FeatNoBcm_No_Actl 1;
BA_ "U_CD542_MY2021_Tx" SG_ 995 FeatNoBcm_No_Actl 1;
BA_ "U_U55X_MY2022_Tx" SG_ 995 FeatNoBcm_No_Actl 1;
BA_ "U_CD764_MY2022_Tx" SG_ 995 FeatNoBcm_No_Actl 1;
BA_ "GenSigSendType" SG_ 995 FeatConfigBcmActl 3;
BA_ "U_CX727_MY2021_Tx" SG_ 995 FeatConfigBcmActl 1;
BA_ "U_P702_MY2021_Tx" SG_ 995 FeatConfigBcmActl 1;
BA_ "U_T6_MCA_MY2020_Tx" SG_ 995 FeatConfigBcmActl 1;
BA_ "U_CD542_MY2021_Tx" SG_ 995 FeatConfigBcmActl 1;
BA_ "U_U55X_MY2022_Tx" SG_ 995 FeatConfigBcmActl 1;
BA_ "U_CD764_MY2022_Tx" SG_ 995 FeatConfigBcmActl 1;
BA_ "GenSigSendType" SG_ 995 LightAmbColor_No_Actl 3;
BA_ "U_CX727_MY2021_Tx" SG_ 995 LightAmbColor_No_Actl 1;
BA_ "U_P702_MY2021_Tx" SG_ 995 LightAmbColor_No_Actl 1;
BA_ "U_T6_MCA_MY2020_Tx" SG_ 995 LightAmbColor_No_Actl 1;
BA_ "U_CD542_MY2021_Tx" SG_ 995 LightAmbColor_No_Actl 1;
BA_ "U_U55X_MY2022_Tx" SG_ 995 LightAmbColor_No_Actl 1;
BA_ "U_CD764_MY2022_Tx" SG_ 995 LightAmbColor_No_Actl 1;
BA_ "GenSigSendType" SG_ 963 Illuminated_Entry_Stat 3;
BA_ "U_CX727_MY2021_Tx" SG_ 963 Illuminated_Entry_Stat 1;
BA_ "U_P702_MY2021_Tx" SG_ 963 Illuminated_Entry_Stat 1;
BA_ "U_T6_MCA_MY2020_Tx" SG_ 963 Illuminated_Entry_Stat 1;
BA_ "U_CD542_MY2021_Tx" SG_ 963 Illuminated_Entry_Stat 1;
BA_ "U_U55X_MY2022_Tx" SG_ 963 Illuminated_Entry_Stat 1;
BA_ "U_CD764_MY2022_Tx" SG_ 963 Illuminated_Entry_Stat 1;
BA_ "GenSigSendType" SG_ 963 Dr_Courtesy_Light_Stat 3;
BA_ "U_CX727_MY2021_Tx" SG_ 963 Dr_Courtesy_Light_Stat 1;
BA_ "U_P702_MY2021_Tx" SG_ 963 Dr_Courtesy_Light_Stat 1;
BA_ "U_T6_MCA_MY2020_Tx" SG_ 963 Dr_Courtesy_Light_Stat 1;
BA_ "U_CD542_MY2021_Tx" SG_ 963 Dr_Courtesy_Light_Stat 1;
BA_ "U_U55X_MY2022_Tx" SG_ 963 Dr_Courtesy_Light_Stat 1;
BA_ "U_CD764_MY2022_Tx" SG_ 963 Dr_Courtesy_Light_Stat 1;
BA_ "GenSigSendType" SG_ 963 Courtesy_Delay_Status 3;
BA_ "U_CX727_MY2021_Tx" SG_ 963 Courtesy_Delay_Status 1;
BA_ "U_P702_MY2021_Tx" SG_ 963 Courtesy_Delay_Status 1;
BA_ "U_T6_MCA_MY2020_Tx" SG_ 963 Courtesy_Delay_Status 1;
BA_ "U_CD542_MY2021_Tx" SG_ 963 Courtesy_Delay_Status 1;
BA_ "U_U55X_MY2022_Tx" SG_ 963 Courtesy_Delay_Status 1;
BA_ "U_CD764_MY2022_Tx" SG_ 963 Courtesy_Delay_Status 1;
BA_ "WakeupSignal" SG_ 963 ImpactEvntFdbck_D_Stat 1;
BA_ "GenSigSendType" SG_ 963 ImpactEvntFdbck_D_Stat 3;
BA_ "U_CX727_MY2021_Tx" SG_ 963 ImpactEvntFdbck_D_Stat 1;
BA_ "U_P702_MY2021_Tx" SG_ 963 ImpactEvntFdbck_D_Stat 1;
BA_ "U_T6_MCA_MY2020_Tx" SG_ 963 ImpactEvntFdbck_D_Stat 1;
BA_ "U_CD542_MY2021_Tx" SG_ 963 ImpactEvntFdbck_D_Stat 1;
BA_ "U_U55X_MY2022_Tx" SG_ 963 ImpactEvntFdbck_D_Stat 1;
BA_ "U_CD764_MY2022_Tx" SG_ 963 ImpactEvntFdbck_D_Stat 1;
BA_ "GenSigSendType" SG_ 963 WrlssAcsyChrgInhbt_B_Rq 3;
BA_ "U_CX727_MY2021_Tx" SG_ 963 WrlssAcsyChrgInhbt_B_Rq 1;
BA_ "U_P702_MY2021_Tx" SG_ 963 WrlssAcsyChrgInhbt_B_Rq 1;
BA_ "U_T6_MCA_MY2020_Tx" SG_ 963 WrlssAcsyChrgInhbt_B_Rq 1;
BA_ "U_CD542_MY2021_Tx" SG_ 963 WrlssAcsyChrgInhbt_B_Rq 1;
BA_ "U_U55X_MY2022_Tx" SG_ 963 WrlssAcsyChrgInhbt_B_Rq 1;
BA_ "U_CD764_MY2022_Tx" SG_ 963 WrlssAcsyChrgInhbt_B_Rq 1;
BA_ "GenSigSendType" SG_ 963 PudLampPsngr_D_Rq 3;
BA_ "U_CX727_MY2021_Tx" SG_ 963 PudLampPsngr_D_Rq 1;
BA_ "U_P702_MY2021_Tx" SG_ 963 PudLampPsngr_D_Rq 1;
BA_ "U_T6_MCA_MY2020_Tx" SG_ 963 PudLampPsngr_D_Rq 1;
BA_ "U_CD542_MY2021_Tx" SG_ 963 PudLampPsngr_D_Rq 1;
BA_ "U_U55X_MY2022_Tx" SG_ 963 PudLampPsngr_D_Rq 1;
BA_ "U_CD764_MY2022_Tx" SG_ 963 PudLampPsngr_D_Rq 1;
BA_ "GenSigSendType" SG_ 963 HeadLampLoOut_B_Stat 3;
BA_ "U_CX727_MY2021_Tx" SG_ 963 HeadLampLoOut_B_Stat 1;
BA_ "U_P702_MY2021_Tx" SG_ 963 HeadLampLoOut_B_Stat 1;
BA_ "U_T6_MCA_MY2020_Tx" SG_ 963 HeadLampLoOut_B_Stat 1;
BA_ "U_CD542_MY2021_Tx" SG_ 963 HeadLampLoOut_B_Stat 1;
BA_ "U_U55X_MY2022_Tx" SG_ 963 HeadLampLoOut_B_Stat 1;
BA_ "U_CD764_MY2022_Tx" SG_ 963 HeadLampLoOut_B_Stat 1;
BA_ "GenSigSendType" SG_ 963 CrnrLghtRight_Pc_Rq 3;
BA_ "U_CX727_MY2021_Tx" SG_ 963 CrnrLghtRight_Pc_Rq 1;
BA_ "U_P702_MY2021_Tx" SG_ 963 CrnrLghtRight_Pc_Rq 1;
BA_ "U_T6_MCA_MY2020_Tx" SG_ 963 CrnrLghtRight_Pc_Rq 1;
BA_ "U_CD542_MY2021_Tx" SG_ 963 CrnrLghtRight_Pc_Rq 1;
BA_ "U_U55X_MY2022_Tx" SG_ 963 CrnrLghtRight_Pc_Rq 1;
BA_ "U_CD764_MY2022_Tx" SG_ 963 CrnrLghtRight_Pc_Rq 1;
BA_ "GenSigSendType" SG_ 963 CrnrLghtLeft_Pc_Rq 3;
BA_ "U_CX727_MY2021_Tx" SG_ 963 CrnrLghtLeft_Pc_Rq 1;
BA_ "U_P702_MY2021_Tx" SG_ 963 CrnrLghtLeft_Pc_Rq 1;
BA_ "U_T6_MCA_MY2020_Tx" SG_ 963 CrnrLghtLeft_Pc_Rq 1;
BA_ "U_CD542_MY2021_Tx" SG_ 963 CrnrLghtLeft_Pc_Rq 1;
BA_ "U_U55X_MY2022_Tx" SG_ 963 CrnrLghtLeft_Pc_Rq 1;
BA_ "U_CD764_MY2022_Tx" SG_ 963 CrnrLghtLeft_Pc_Rq 1;
BA_ "GenSigSendType" SG_ 963 HeadLghtHiFdbck_D_Stat 3;
BA_ "U_CX727_MY2021_Tx" SG_ 963 HeadLghtHiFdbck_D_Stat 1;
BA_ "U_P702_MY2021_Tx" SG_ 963 HeadLghtHiFdbck_D_Stat 1;
BA_ "U_T6_MCA_MY2020_Tx" SG_ 963 HeadLghtHiFdbck_D_Stat 1;
BA_ "U_CD542_MY2021_Tx" SG_ 963 HeadLghtHiFdbck_D_Stat 1;
BA_ "U_U55X_MY2022_Tx" SG_ 963 HeadLghtHiFdbck_D_Stat 1;
BA_ "U_CD764_MY2022_Tx" SG_ 963 HeadLghtHiFdbck_D_Stat 1;
BA_ "GenSigSendType" SG_ 963 PudLampDrv_D_Rq 3;
BA_ "U_CX727_MY2021_Tx" SG_ 963 PudLampDrv_D_Rq 1;
BA_ "U_P702_MY2021_Tx" SG_ 963 PudLampDrv_D_Rq 1;
BA_ "U_T6_MCA_MY2020_Tx" SG_ 963 PudLampDrv_D_Rq 1;
BA_ "U_CD542_MY2021_Tx" SG_ 963 PudLampDrv_D_Rq 1;
BA_ "U_U55X_MY2022_Tx" SG_ 963 PudLampDrv_D_Rq 1;
BA_ "U_CD764_MY2022_Tx" SG_ 963 PudLampDrv_D_Rq 1;
BA_ "GenSigSendType" SG_ 963 TrnNotInPrkChime_B_Rq 3;
BA_ "U_CX727_MY2021_Tx" SG_ 963 TrnNotInPrkChime_B_Rq 1;
BA_ "U_P702_MY2021_Tx" SG_ 963 TrnNotInPrkChime_B_Rq 1;
BA_ "U_T6_MCA_MY2020_Tx" SG_ 963 TrnNotInPrkChime_B_Rq 1;
BA_ "U_CD542_MY2021_Tx" SG_ 963 TrnNotInPrkChime_B_Rq 1;
BA_ "U_U55X_MY2022_Tx" SG_ 963 TrnNotInPrkChime_B_Rq 1;
BA_ "U_CD764_MY2022_Tx" SG_ 963 TrnNotInPrkChime_B_Rq 1;
BA_ "GenSigSendType" SG_ 963 PrkLightChime_B_Rq 3;
BA_ "U_CX727_MY2021_Tx" SG_ 963 PrkLightChime_B_Rq 1;
BA_ "U_P702_MY2021_Tx" SG_ 963 PrkLightChime_B_Rq 1;
BA_ "U_T6_MCA_MY2020_Tx" SG_ 963 PrkLightChime_B_Rq 1;
BA_ "U_CD542_MY2021_Tx" SG_ 963 PrkLightChime_B_Rq 1;
BA_ "U_U55X_MY2022_Tx" SG_ 963 PrkLightChime_B_Rq 1;
BA_ "U_CD764_MY2022_Tx" SG_ 963 PrkLightChime_B_Rq 1;
BA_ "WakeupSignal" SG_ 963 KeyInIgnWarn_B_Cmd 1;
BA_ "GenSigSendType" SG_ 963 KeyInIgnWarn_B_Cmd 3;
BA_ "U_CX727_MY2021_Tx" SG_ 963 KeyInIgnWarn_B_Cmd 1;
BA_ "U_P702_MY2021_Tx" SG_ 963 KeyInIgnWarn_B_Cmd 1;
BA_ "U_T6_MCA_MY2020_Tx" SG_ 963 KeyInIgnWarn_B_Cmd 1;
BA_ "U_CD542_MY2021_Tx" SG_ 963 KeyInIgnWarn_B_Cmd 1;
BA_ "U_U55X_MY2022_Tx" SG_ 963 KeyInIgnWarn_B_Cmd 1;
BA_ "U_CD764_MY2022_Tx" SG_ 963 KeyInIgnWarn_B_Cmd 1;
BA_ "WakeupSignal" SG_ 963 HomeSafeLtChime_B_Rq 1;
BA_ "GenSigSendType" SG_ 963 HomeSafeLtChime_B_Rq 3;
BA_ "U_CX727_MY2021_Tx" SG_ 963 HomeSafeLtChime_B_Rq 1;
BA_ "U_P702_MY2021_Tx" SG_ 963 HomeSafeLtChime_B_Rq 1;
BA_ "U_T6_MCA_MY2020_Tx" SG_ 963 HomeSafeLtChime_B_Rq 1;
BA_ "U_CD542_MY2021_Tx" SG_ 963 HomeSafeLtChime_B_Rq 1;
BA_ "U_U55X_MY2022_Tx" SG_ 963 HomeSafeLtChime_B_Rq 1;
BA_ "U_CD764_MY2022_Tx" SG_ 963 HomeSafeLtChime_B_Rq 1;
BA_ "WakeupSignal" SG_ 963 StopLghtOn_B_Stat 1;
BA_ "GenSigSendType" SG_ 963 StopLghtOn_B_Stat 3;
BA_ "U_CX727_MY2021_Tx" SG_ 963 StopLghtOn_B_Stat 1;
BA_ "U_P702_MY2021_Tx" SG_ 963 StopLghtOn_B_Stat 1;
BA_ "U_T6_MCA_MY2020_Tx" SG_ 963 StopLghtOn_B_Stat 1;
BA_ "U_CD542_MY2021_Tx" SG_ 963 StopLghtOn_B_Stat 1;
BA_ "U_U55X_MY2022_Tx" SG_ 963 StopLghtOn_B_Stat 1;
BA_ "U_CD764_MY2022_Tx" SG_ 963 StopLghtOn_B_Stat 1;
BA_ "GenSigSendType" SG_ 963 RvrseLghtOn_B_Stat 3;
BA_ "U_T6_MCA_MY2020_Rx" SG_ 963 RvrseLghtOn_B_Stat 1;
BA_ "ECGUsedRxSignal" SG_ 963 RvrseLghtOn_B_Stat 1;
BA_ "U_CD542_MY2021_Rx" SG_ 963 RvrseLghtOn_B_Stat 1;
BA_ "U_U55X_MY2022_Rx" SG_ 963 RvrseLghtOn_B_Stat 1;
BA_ "U_CD764_MY2022_Rx" SG_ 963 RvrseLghtOn_B_Stat 1;
BA_ "U_CX727_MY2021_Tx" SG_ 963 RvrseLghtOn_B_Stat 1;
BA_ "U_P702_MY2021_Tx" SG_ 963 RvrseLghtOn_B_Stat 1;
BA_ "U_T6_MCA_MY2020_Tx" SG_ 963 RvrseLghtOn_B_Stat 1;
BA_ "U_CD542_MY2021_Tx" SG_ 963 RvrseLghtOn_B_Stat 1;
BA_ "U_U55X_MY2022_Tx" SG_ 963 RvrseLghtOn_B_Stat 1;
BA_ "U_CD764_MY2022_Tx" SG_ 963 RvrseLghtOn_B_Stat 1;
BA_ "WakeupSignal" SG_ 963 PrkLght_D_Stat 1;
BA_ "GenSigSendType" SG_ 963 PrkLght_D_Stat 3;
BA_ "U_CX727_MY2021_Tx" SG_ 963 PrkLght_D_Stat 1;
BA_ "U_P702_MY2021_Tx" SG_ 963 PrkLght_D_Stat 1;
BA_ "U_T6_MCA_MY2020_Tx" SG_ 963 PrkLght_D_Stat 1;
BA_ "U_CD542_MY2021_Tx" SG_ 963 PrkLght_D_Stat 1;
BA_ "U_U55X_MY2022_Tx" SG_ 963 PrkLght_D_Stat 1;
BA_ "U_CD764_MY2022_Tx" SG_ 963 PrkLght_D_Stat 1;
BA_ "WakeupSignal" SG_ 963 HeadLghtSwtch_D_Stat 1;
BA_ "GenSigStartValueInteger" SG_ 963 HeadLghtSwtch_D_Stat 2;
BA_ "GenSigStartValue" SG_ 963 HeadLghtSwtch_D_Stat 2;
BA_ "GenSigSendType" SG_ 963 HeadLghtSwtch_D_Stat 3;
BA_ "U_CX727_MY2021_Tx" SG_ 963 HeadLghtSwtch_D_Stat 1;
BA_ "U_P702_MY2021_Tx" SG_ 963 HeadLghtSwtch_D_Stat 1;
BA_ "U_T6_MCA_MY2020_Tx" SG_ 963 HeadLghtSwtch_D_Stat 1;
BA_ "U_CD542_MY2021_Tx" SG_ 963 HeadLghtSwtch_D_Stat 1;
BA_ "U_U55X_MY2022_Tx" SG_ 963 HeadLghtSwtch_D_Stat 1;
BA_ "U_CD764_MY2022_Tx" SG_ 963 HeadLghtSwtch_D_Stat 1;
BA_ "GenSigStartValueInteger" SG_ 963 HeadLampLoFrOn_B_Stat 1;
BA_ "GenSigStartValue" SG_ 963 HeadLampLoFrOn_B_Stat 1;
BA_ "GenSigSendType" SG_ 963 HeadLampLoFrOn_B_Stat 3;
BA_ "U_CX727_MY2021_Tx" SG_ 963 HeadLampLoFrOn_B_Stat 1;
BA_ "U_P702_MY2021_Tx" SG_ 963 HeadLampLoFrOn_B_Stat 1;
BA_ "U_T6_MCA_MY2020_Tx" SG_ 963 HeadLampLoFrOn_B_Stat 1;
BA_ "U_CD542_MY2021_Tx" SG_ 963 HeadLampLoFrOn_B_Stat 1;
BA_ "U_U55X_MY2022_Tx" SG_ 963 HeadLampLoFrOn_B_Stat 1;
BA_ "U_CD764_MY2022_Tx" SG_ 963 HeadLampLoFrOn_B_Stat 1;
BA_ "GenSigStartValueInteger" SG_ 963 HeadLampLoFlOn_B_Stat 1;
BA_ "GenSigStartValue" SG_ 963 HeadLampLoFlOn_B_Stat 1;
BA_ "GenSigSendType" SG_ 963 HeadLampLoFlOn_B_Stat 3;
BA_ "U_CX727_MY2021_Tx" SG_ 963 HeadLampLoFlOn_B_Stat 1;
BA_ "U_P702_MY2021_Tx" SG_ 963 HeadLampLoFlOn_B_Stat 1;
BA_ "U_T6_MCA_MY2020_Tx" SG_ 963 HeadLampLoFlOn_B_Stat 1;
BA_ "U_CD542_MY2021_Tx" SG_ 963 HeadLampLoFlOn_B_Stat 1;
BA_ "U_U55X_MY2022_Tx" SG_ 963 HeadLampLoFlOn_B_Stat 1;
BA_ "U_CD764_MY2022_Tx" SG_ 963 HeadLampLoFlOn_B_Stat 1;
BA_ "GenSigStartValueInteger" SG_ 963 HeadLampLoActv_B_Stat 1;
BA_ "GenSigStartValue" SG_ 963 HeadLampLoActv_B_Stat 1;
BA_ "GenSigSendType" SG_ 963 HeadLampLoActv_B_Stat 3;
BA_ "U_T6_MCA_MY2020_Rx" SG_ 963 HeadLampLoActv_B_Stat 1;
BA_ "ECGUsedRxSignal" SG_ 963 HeadLampLoActv_B_Stat 1;
BA_ "U_CD542_MY2021_Rx" SG_ 963 HeadLampLoActv_B_Stat 1;
BA_ "U_U55X_MY2022_Rx" SG_ 963 HeadLampLoActv_B_Stat 1;
BA_ "U_CD764_MY2022_Rx" SG_ 963 HeadLampLoActv_B_Stat 1;
BA_ "U_CX727_MY2021_Tx" SG_ 963 HeadLampLoActv_B_Stat 1;
BA_ "U_P702_MY2021_Tx" SG_ 963 HeadLampLoActv_B_Stat 1;
BA_ "U_T6_MCA_MY2020_Tx" SG_ 963 HeadLampLoActv_B_Stat 1;
BA_ "U_CD542_MY2021_Tx" SG_ 963 HeadLampLoActv_B_Stat 1;
BA_ "U_U55X_MY2022_Tx" SG_ 963 HeadLampLoActv_B_Stat 1;
BA_ "U_CD764_MY2022_Tx" SG_ 963 HeadLampLoActv_B_Stat 1;
BA_ "WakeupSignal" SG_ 963 Headlamp_On_Wrning_Cmd 1;
BA_ "GenSigSendType" SG_ 963 Headlamp_On_Wrning_Cmd 3;
BA_ "U_CX727_MY2021_Tx" SG_ 963 Headlamp_On_Wrning_Cmd 1;
BA_ "U_P702_MY2021_Tx" SG_ 963 Headlamp_On_Wrning_Cmd 1;
BA_ "U_T6_MCA_MY2020_Tx" SG_ 963 Headlamp_On_Wrning_Cmd 1;
BA_ "U_CD542_MY2021_Tx" SG_ 963 Headlamp_On_Wrning_Cmd 1;
BA_ "U_U55X_MY2022_Tx" SG_ 963 Headlamp_On_Wrning_Cmd 1;
BA_ "U_CD764_MY2022_Tx" SG_ 963 Headlamp_On_Wrning_Cmd 1;
BA_ "GenSigSendType" SG_ 963 Park_Brake_Chime_Rqst 3;
BA_ "U_CX727_MY2021_Tx" SG_ 963 Park_Brake_Chime_Rqst 1;
BA_ "U_P702_MY2021_Tx" SG_ 963 Park_Brake_Chime_Rqst 1;
BA_ "U_T6_MCA_MY2020_Tx" SG_ 963 Park_Brake_Chime_Rqst 1;
BA_ "U_CD542_MY2021_Tx" SG_ 963 Park_Brake_Chime_Rqst 1;
BA_ "U_U55X_MY2022_Tx" SG_ 963 Park_Brake_Chime_Rqst 1;
BA_ "U_CD764_MY2022_Tx" SG_ 963 Park_Brake_Chime_Rqst 1;
BA_ "WakeupSignal" SG_ 963 HeadLghtHiOn_B_Stat 1;
BA_ "GenSigSendType" SG_ 963 HeadLghtHiOn_B_Stat 3;
BA_ "U_T6_MCA_MY2020_Rx" SG_ 963 HeadLghtHiOn_B_Stat 1;
BA_ "ECGUsedRxSignal" SG_ 963 HeadLghtHiOn_B_Stat 1;
BA_ "U_CD542_MY2021_Rx" SG_ 963 HeadLghtHiOn_B_Stat 1;
BA_ "U_U55X_MY2022_Rx" SG_ 963 HeadLghtHiOn_B_Stat 1;
BA_ "U_CD764_MY2022_Rx" SG_ 963 HeadLghtHiOn_B_Stat 1;
BA_ "U_CX727_MY2021_Tx" SG_ 963 HeadLghtHiOn_B_Stat 1;
BA_ "U_P702_MY2021_Tx" SG_ 963 HeadLghtHiOn_B_Stat 1;
BA_ "U_T6_MCA_MY2020_Tx" SG_ 963 HeadLghtHiOn_B_Stat 1;
BA_ "U_CD542_MY2021_Tx" SG_ 963 HeadLghtHiOn_B_Stat 1;
BA_ "U_U55X_MY2022_Tx" SG_ 963 HeadLghtHiOn_B_Stat 1;
BA_ "U_CD764_MY2022_Tx" SG_ 963 HeadLghtHiOn_B_Stat 1;
BA_ "GenSigSendType" SG_ 963 BrkWarnInd_B_Rq 3;
BA_ "U_CX727_MY2021_Tx" SG_ 963 BrkWarnInd_B_Rq 1;
BA_ "U_P702_MY2021_Tx" SG_ 963 BrkWarnInd_B_Rq 1;
BA_ "U_T6_MCA_MY2020_Tx" SG_ 963 BrkWarnInd_B_Rq 1;
BA_ "U_CD542_MY2021_Tx" SG_ 963 BrkWarnInd_B_Rq 1;
BA_ "U_U55X_MY2022_Tx" SG_ 963 BrkWarnInd_B_Rq 1;
BA_ "U_CD764_MY2022_Tx" SG_ 963 BrkWarnInd_B_Rq 1;
BA_ "GenSigSendType" SG_ 963 Brk_Fluid_Lvl_Low 3;
BA_ "U_CX727_MY2021_Tx" SG_ 963 Brk_Fluid_Lvl_Low 1;
BA_ "U_P702_MY2021_Tx" SG_ 963 Brk_Fluid_Lvl_Low 1;
BA_ "U_T6_MCA_MY2020_Tx" SG_ 963 Brk_Fluid_Lvl_Low 1;
BA_ "U_CD542_MY2021_Tx" SG_ 963 Brk_Fluid_Lvl_Low 1;
BA_ "U_U55X_MY2022_Tx" SG_ 963 Brk_Fluid_Lvl_Low 1;
BA_ "U_CD764_MY2022_Tx" SG_ 963 Brk_Fluid_Lvl_Low 1;
BA_ "GenSigSendType" SG_ 963 ReducedGuard_D_Stat 3;
BA_ "U_CX727_MY2021_Tx" SG_ 963 ReducedGuard_D_Stat 1;
BA_ "U_P702_MY2021_Tx" SG_ 963 ReducedGuard_D_Stat 1;
BA_ "U_T6_MCA_MY2020_Tx" SG_ 963 ReducedGuard_D_Stat 1;
BA_ "U_CD542_MY2021_Tx" SG_ 963 ReducedGuard_D_Stat 1;
BA_ "U_U55X_MY2022_Tx" SG_ 963 ReducedGuard_D_Stat 1;
BA_ "U_CD764_MY2022_Tx" SG_ 963 ReducedGuard_D_Stat 1;
BA_ "WakeupSignal" SG_ 963 Perimeter_Alarm_Status 1;
BA_ "GenSigSendType" SG_ 963 Perimeter_Alarm_Status 3;
BA_ "U_P702_MY2021_Rx" SG_ 963 Perimeter_Alarm_Status 1;
BA_ "U_T6_MCA_MY2020_Rx" SG_ 963 Perimeter_Alarm_Status 1;
BA_ "ECGUsedRxSignal" SG_ 963 Perimeter_Alarm_Status 1;
BA_ "U_CD542_MY2021_Rx" SG_ 963 Perimeter_Alarm_Status 1;
BA_ "U_U55X_MY2022_Rx" SG_ 963 Perimeter_Alarm_Status 1;
BA_ "U_CD764_MY2022_Rx" SG_ 963 Perimeter_Alarm_Status 1;
BA_ "U_CX727_MY2021_Tx" SG_ 963 Perimeter_Alarm_Status 1;
BA_ "U_P702_MY2021_Tx" SG_ 963 Perimeter_Alarm_Status 1;
BA_ "U_T6_MCA_MY2020_Tx" SG_ 963 Perimeter_Alarm_Status 1;
BA_ "U_CD542_MY2021_Tx" SG_ 963 Perimeter_Alarm_Status 1;
BA_ "U_U55X_MY2022_Tx" SG_ 963 Perimeter_Alarm_Status 1;
BA_ "U_CD764_MY2022_Tx" SG_ 963 Perimeter_Alarm_Status 1;
BA_ "WakeupSignal" SG_ 963 Courtesy_BSave_Stat 1;
BA_ "GenSigStartValueInteger" SG_ 963 Courtesy_BSave_Stat 1;
BA_ "GenSigStartValue" SG_ 963 Courtesy_BSave_Stat 1;
BA_ "GenSigSendType" SG_ 963 Courtesy_BSave_Stat 3;
BA_ "U_P702_MY2021_Rx" SG_ 963 Courtesy_BSave_Stat 1;
BA_ "U_T6_MCA_MY2020_Rx" SG_ 963 Courtesy_BSave_Stat 1;
BA_ "U_CD542_MY2021_Rx" SG_ 963 Courtesy_BSave_Stat 1;
BA_ "U_U55X_MY2022_Rx" SG_ 963 Courtesy_BSave_Stat 1;
BA_ "U_CD764_MY2022_Rx" SG_ 963 Courtesy_BSave_Stat 1;
BA_ "U_CX727_MY2021_Tx" SG_ 963 Courtesy_BSave_Stat 1;
BA_ "U_P702_MY2021_Tx" SG_ 963 Courtesy_BSave_Stat 1;
BA_ "U_T6_MCA_MY2020_Tx" SG_ 963 Courtesy_BSave_Stat 1;
BA_ "U_CD542_MY2021_Tx" SG_ 963 Courtesy_BSave_Stat 1;
BA_ "U_U55X_MY2022_Tx" SG_ 963 Courtesy_BSave_Stat 1;
BA_ "U_CD764_MY2022_Tx" SG_ 963 Courtesy_BSave_Stat 1;
BA_ "GenSigSendType" SG_ 963 DrTgateLck_D_Stat 3;
BA_ "U_CX727_MY2021_Tx" SG_ 963 DrTgateLck_D_Stat 1;
BA_ "U_P702_MY2021_Tx" SG_ 963 DrTgateLck_D_Stat 1;
BA_ "U_T6_MCA_MY2020_Tx" SG_ 963 DrTgateLck_D_Stat 1;
BA_ "U_CD542_MY2021_Tx" SG_ 963 DrTgateLck_D_Stat 1;
BA_ "U_U55X_MY2022_Tx" SG_ 963 DrTgateLck_D_Stat 1;
BA_ "U_CD764_MY2022_Tx" SG_ 963 DrTgateLck_D_Stat 1;
BA_ "WakeupSignal" SG_ 963 WndwGlbl_D_Cmd 1;
BA_ "GenSigSendType" SG_ 963 WndwGlbl_D_Cmd 3;
BA_ "U_CX727_MY2021_Tx" SG_ 963 WndwGlbl_D_Cmd 1;
BA_ "U_P702_MY2021_Tx" SG_ 963 WndwGlbl_D_Cmd 1;
BA_ "U_T6_MCA_MY2020_Tx" SG_ 963 WndwGlbl_D_Cmd 1;
BA_ "U_CD542_MY2021_Tx" SG_ 963 WndwGlbl_D_Cmd 1;
BA_ "U_U55X_MY2022_Tx" SG_ 963 WndwGlbl_D_Cmd 1;
BA_ "U_CD764_MY2022_Tx" SG_ 963 WndwGlbl_D_Cmd 1;
BA_ "WakeupSignal" SG_ 963 PudLamp_D_Rq 1;
BA_ "GenSigSendType" SG_ 963 PudLamp_D_Rq 3;
BA_ "U_T6_MCA_MY2020_Rx" SG_ 963 PudLamp_D_Rq 1;
BA_ "ECGUsedRxSignal" SG_ 963 PudLamp_D_Rq 1;
BA_ "U_CD542_MY2021_Rx" SG_ 963 PudLamp_D_Rq 1;
BA_ "U_U55X_MY2022_Rx" SG_ 963 PudLamp_D_Rq 1;
BA_ "U_CD764_MY2022_Rx" SG_ 963 PudLamp_D_Rq 1;
BA_ "U_CX727_MY2021_Tx" SG_ 963 PudLamp_D_Rq 1;
BA_ "U_P702_MY2021_Tx" SG_ 963 PudLamp_D_Rq 1;
BA_ "U_T6_MCA_MY2020_Tx" SG_ 963 PudLamp_D_Rq 1;
BA_ "U_CD542_MY2021_Tx" SG_ 963 PudLamp_D_Rq 1;
BA_ "U_U55X_MY2022_Tx" SG_ 963 PudLamp_D_Rq 1;
BA_ "U_CD764_MY2022_Tx" SG_ 963 PudLamp_D_Rq 1;
BA_ "GenSigSendType" SG_ 963 DayRnngLampOn_B_Stat 3;
BA_ "ECGUsedRxSignal" SG_ 963 DayRnngLampOn_B_Stat 1;
BA_ "U_CD764_MY2022_Rx" SG_ 963 DayRnngLampOn_B_Stat 1;
BA_ "U_CX727_MY2021_Tx" SG_ 963 DayRnngLampOn_B_Stat 1;
BA_ "U_P702_MY2021_Tx" SG_ 963 DayRnngLampOn_B_Stat 1;
BA_ "U_T6_MCA_MY2020_Tx" SG_ 963 DayRnngLampOn_B_Stat 1;
BA_ "U_CD542_MY2021_Tx" SG_ 963 DayRnngLampOn_B_Stat 1;
BA_ "U_U55X_MY2022_Tx" SG_ 963 DayRnngLampOn_B_Stat 1;
BA_ "U_CD764_MY2022_Tx" SG_ 963 DayRnngLampOn_B_Stat 1;
BA_ "WakeupSignal" SG_ 963 PerimeterAlarmChimeRq 1;
BA_ "GenSigSendType" SG_ 963 PerimeterAlarmChimeRq 3;
BA_ "U_CX727_MY2021_Tx" SG_ 963 PerimeterAlarmChimeRq 1;
BA_ "U_P702_MY2021_Tx" SG_ 963 PerimeterAlarmChimeRq 1;
BA_ "U_T6_MCA_MY2020_Tx" SG_ 963 PerimeterAlarmChimeRq 1;
BA_ "U_CD542_MY2021_Tx" SG_ 963 PerimeterAlarmChimeRq 1;
BA_ "U_U55X_MY2022_Tx" SG_ 963 PerimeterAlarmChimeRq 1;
BA_ "U_CD764_MY2022_Tx" SG_ 963 PerimeterAlarmChimeRq 1;
BA_ "WakeupSignal" SG_ 909 IgnPsswrdDsply_B_Rq 1;
BA_ "GenSigSendType" SG_ 909 IgnPsswrdDsply_B_Rq 3;
BA_ "U_CX727_MY2021_Tx" SG_ 909 IgnPsswrdDsply_B_Rq 1;
BA_ "U_P702_MY2021_Tx" SG_ 909 IgnPsswrdDsply_B_Rq 1;
BA_ "U_T6_MCA_MY2020_Tx" SG_ 909 IgnPsswrdDsply_B_Rq 1;
BA_ "U_CD542_MY2021_Tx" SG_ 909 IgnPsswrdDsply_B_Rq 1;
BA_ "U_U55X_MY2022_Tx" SG_ 909 IgnPsswrdDsply_B_Rq 1;
BA_ "U_CD764_MY2022_Tx" SG_ 909 IgnPsswrdDsply_B_Rq 1;
BA_ "WakeupSignal" SG_ 909 ElPwPoint_D_Rq 1;
BA_ "GenSigSendType" SG_ 909 ElPwPoint_D_Rq 3;
BA_ "U_P702_MY2021_Rx" SG_ 909 ElPwPoint_D_Rq 1;
BA_ "U_T6_MCA_MY2020_Rx" SG_ 909 ElPwPoint_D_Rq 1;
BA_ "U_CD542_MY2021_Rx" SG_ 909 ElPwPoint_D_Rq 1;
BA_ "U_U55X_MY2022_Rx" SG_ 909 ElPwPoint_D_Rq 1;
BA_ "U_CD764_MY2022_Rx" SG_ 909 ElPwPoint_D_Rq 1;
BA_ "U_P702_MY2021_Tx" SG_ 909 ElPwPoint_D_Rq 1;
BA_ "U_T6_MCA_MY2020_Tx" SG_ 909 ElPwPoint_D_Rq 1;
BA_ "U_CD542_MY2021_Tx" SG_ 909 ElPwPoint_D_Rq 1;
BA_ "U_U55X_MY2022_Tx" SG_ 909 ElPwPoint_D_Rq 1;
BA_ "U_CD764_MY2022_Tx" SG_ 909 ElPwPoint_D_Rq 1;
BA_ "GenSigSendType" SG_ 909 PoliceIdlMde_D_Stat 3;
BA_ "U_CX727_MY2021_Tx" SG_ 909 PoliceIdlMde_D_Stat 1;
BA_ "U_P702_MY2021_Tx" SG_ 909 PoliceIdlMde_D_Stat 1;
BA_ "U_T6_MCA_MY2020_Tx" SG_ 909 PoliceIdlMde_D_Stat 1;
BA_ "U_CD542_MY2021_Tx" SG_ 909 PoliceIdlMde_D_Stat 1;
BA_ "U_U55X_MY2022_Tx" SG_ 909 PoliceIdlMde_D_Stat 1;
BA_ "U_CD764_MY2022_Tx" SG_ 909 PoliceIdlMde_D_Stat 1;
BA_ "GenSigSendType" SG_ 909 DrLatchMsgTxt_D_Rq 3;
BA_ "U_CX727_MY2021_Tx" SG_ 909 DrLatchMsgTxt_D_Rq 1;
BA_ "U_P702_MY2021_Tx" SG_ 909 DrLatchMsgTxt_D_Rq 1;
BA_ "U_T6_MCA_MY2020_Tx" SG_ 909 DrLatchMsgTxt_D_Rq 1;
BA_ "U_CD542_MY2021_Tx" SG_ 909 DrLatchMsgTxt_D_Rq 1;
BA_ "U_U55X_MY2022_Tx" SG_ 909 DrLatchMsgTxt_D_Rq 1;
BA_ "U_CD764_MY2022_Tx" SG_ 909 DrLatchMsgTxt_D_Rq 1;
BA_ "WakeupSignal" SG_ 909 HazrdLght_B_Stat 1;
BA_ "GenSigSendType" SG_ 909 HazrdLght_B_Stat 3;
BA_ "U_T6_MCA_MY2020_Rx" SG_ 909 HazrdLght_B_Stat 1;
BA_ "ECGUsedRxSignal" SG_ 909 HazrdLght_B_Stat 1;
BA_ "U_CD542_MY2021_Rx" SG_ 909 HazrdLght_B_Stat 1;
BA_ "U_U55X_MY2022_Rx" SG_ 909 HazrdLght_B_Stat 1;
BA_ "U_CD764_MY2022_Rx" SG_ 909 HazrdLght_B_Stat 1;
BA_ "U_P702_MY2021_Tx" SG_ 909 HazrdLght_B_Stat 1;
BA_ "U_T6_MCA_MY2020_Tx" SG_ 909 HazrdLght_B_Stat 1;
BA_ "U_CD542_MY2021_Tx" SG_ 909 HazrdLght_B_Stat 1;
BA_ "U_U55X_MY2022_Tx" SG_ 909 HazrdLght_B_Stat 1;
BA_ "U_CD764_MY2022_Tx" SG_ 909 HazrdLght_B_Stat 1;
BA_ "GenSigSendType" SG_ 909 SecurityMsgTxt_D_Rq 3;
BA_ "U_CX727_MY2021_Tx" SG_ 909 SecurityMsgTxt_D_Rq 1;
BA_ "U_P702_MY2021_Tx" SG_ 909 SecurityMsgTxt_D_Rq 1;
BA_ "U_T6_MCA_MY2020_Tx" SG_ 909 SecurityMsgTxt_D_Rq 1;
BA_ "U_CD542_MY2021_Tx" SG_ 909 SecurityMsgTxt_D_Rq 1;
BA_ "U_U55X_MY2022_Tx" SG_ 909 SecurityMsgTxt_D_Rq 1;
BA_ "U_CD764_MY2022_Tx" SG_ 909 SecurityMsgTxt_D_Rq 1;
BA_ "GenSigSendType" SG_ 909 PrmtrAlrmEvnt_D_Stat 3;
BA_ "U_T6_MCA_MY2020_Rx" SG_ 909 PrmtrAlrmEvnt_D_Stat 1;
BA_ "ECGUsedRxSignal" SG_ 909 PrmtrAlrmEvnt_D_Stat 1;
BA_ "U_CD542_MY2021_Rx" SG_ 909 PrmtrAlrmEvnt_D_Stat 1;
BA_ "U_U55X_MY2022_Rx" SG_ 909 PrmtrAlrmEvnt_D_Stat 1;
BA_ "U_CD764_MY2022_Rx" SG_ 909 PrmtrAlrmEvnt_D_Stat 1;
BA_ "U_CX727_MY2021_Tx" SG_ 909 PrmtrAlrmEvnt_D_Stat 1;
BA_ "U_P702_MY2021_Tx" SG_ 909 PrmtrAlrmEvnt_D_Stat 1;
BA_ "U_T6_MCA_MY2020_Tx" SG_ 909 PrmtrAlrmEvnt_D_Stat 1;
BA_ "U_CD542_MY2021_Tx" SG_ 909 PrmtrAlrmEvnt_D_Stat 1;
BA_ "U_U55X_MY2022_Tx" SG_ 909 PrmtrAlrmEvnt_D_Stat 1;
BA_ "U_CD764_MY2022_Tx" SG_ 909 PrmtrAlrmEvnt_D_Stat 1;
BA_ "GenSigStartValueInteger" SG_ 909 HeadLghtHiPrmsn_D_Stat 3;
BA_ "GenSigStartValue" SG_ 909 HeadLghtHiPrmsn_D_Stat 3;
BA_ "GenSigSendType" SG_ 909 HeadLghtHiPrmsn_D_Stat 3;
BA_ "U_CX727_MY2021_Tx" SG_ 909 HeadLghtHiPrmsn_D_Stat 1;
BA_ "U_P702_MY2021_Tx" SG_ 909 HeadLghtHiPrmsn_D_Stat 1;
BA_ "U_T6_MCA_MY2020_Tx" SG_ 909 HeadLghtHiPrmsn_D_Stat 1;
BA_ "U_CD542_MY2021_Tx" SG_ 909 HeadLghtHiPrmsn_D_Stat 1;
BA_ "U_U55X_MY2022_Tx" SG_ 909 HeadLghtHiPrmsn_D_Stat 1;
BA_ "U_CD764_MY2022_Tx" SG_ 909 HeadLghtHiPrmsn_D_Stat 1;
BA_ "GenSigSendType" SG_ 909 SteWhlLckMsgTxt_D_Rq 3;
BA_ "U_CX727_MY2021_Tx" SG_ 909 SteWhlLckMsgTxt_D_Rq 1;
BA_ "U_P702_MY2021_Tx" SG_ 909 SteWhlLckMsgTxt_D_Rq 1;
BA_ "U_T6_MCA_MY2020_Tx" SG_ 909 SteWhlLckMsgTxt_D_Rq 1;
BA_ "U_CD542_MY2021_Tx" SG_ 909 SteWhlLckMsgTxt_D_Rq 1;
BA_ "U_U55X_MY2022_Tx" SG_ 909 SteWhlLckMsgTxt_D_Rq 1;
BA_ "U_CD764_MY2022_Tx" SG_ 909 SteWhlLckMsgTxt_D_Rq 1;
BA_ "WakeupSignal" SG_ 909 immoMsgTxt_D_Rq 1;
BA_ "GenSigSendType" SG_ 909 immoMsgTxt_D_Rq 3;
BA_ "U_CX727_MY2021_Tx" SG_ 909 immoMsgTxt_D_Rq 1;
BA_ "U_P702_MY2021_Tx" SG_ 909 immoMsgTxt_D_Rq 1;
BA_ "U_T6_MCA_MY2020_Tx" SG_ 909 immoMsgTxt_D_Rq 1;
BA_ "U_CD542_MY2021_Tx" SG_ 909 immoMsgTxt_D_Rq 1;
BA_ "U_U55X_MY2022_Tx" SG_ 909 immoMsgTxt_D_Rq 1;
BA_ "U_CD764_MY2022_Tx" SG_ 909 immoMsgTxt_D_Rq 1;
BA_ "WakeupSignal" SG_ 909 PrsnlDevcChrgEnbl_B_Rq 1;
BA_ "GenSigSendType" SG_ 909 PrsnlDevcChrgEnbl_B_Rq 3;
BA_ "U_P702_MY2021_Tx" SG_ 909 PrsnlDevcChrgEnbl_B_Rq 1;
BA_ "U_T6_MCA_MY2020_Tx" SG_ 909 PrsnlDevcChrgEnbl_B_Rq 1;
BA_ "U_CD542_MY2021_Tx" SG_ 909 PrsnlDevcChrgEnbl_B_Rq 1;
BA_ "U_U55X_MY2022_Tx" SG_ 909 PrsnlDevcChrgEnbl_B_Rq 1;
BA_ "U_CD764_MY2022_Tx" SG_ 909 PrsnlDevcChrgEnbl_B_Rq 1;
BA_ "GenSigSendType" SG_ 909 TracKeyMde_D_Stat 3;
BA_ "U_CX727_MY2021_Tx" SG_ 909 TracKeyMde_D_Stat 1;
BA_ "U_P702_MY2021_Tx" SG_ 909 TracKeyMde_D_Stat 1;
BA_ "U_T6_MCA_MY2020_Tx" SG_ 909 TracKeyMde_D_Stat 1;
BA_ "U_CD542_MY2021_Tx" SG_ 909 TracKeyMde_D_Stat 1;
BA_ "U_U55X_MY2022_Tx" SG_ 909 TracKeyMde_D_Stat 1;
BA_ "U_CD764_MY2022_Tx" SG_ 909 TracKeyMde_D_Stat 1;
BA_ "GenSigSendType" SG_ 909 PEBackupSlot_Stats 3;
BA_ "U_CX727_MY2021_Tx" SG_ 909 PEBackupSlot_Stats 1;
BA_ "U_P702_MY2021_Tx" SG_ 909 PEBackupSlot_Stats 1;
BA_ "U_T6_MCA_MY2020_Tx" SG_ 909 PEBackupSlot_Stats 1;
BA_ "U_CD542_MY2021_Tx" SG_ 909 PEBackupSlot_Stats 1;
BA_ "U_U55X_MY2022_Tx" SG_ 909 PEBackupSlot_Stats 1;
BA_ "U_CD764_MY2022_Tx" SG_ 909 PEBackupSlot_Stats 1;
BA_ "MetaData" SG_ 909 KeyMykeyTot_No_Cnt 1;
BA_ "GenSigSendType" SG_ 909 KeyMykeyTot_No_Cnt 3;
BA_ "U_CX727_MY2021_Tx" SG_ 909 KeyMykeyTot_No_Cnt 1;
BA_ "U_P702_MY2021_Tx" SG_ 909 KeyMykeyTot_No_Cnt 1;
BA_ "U_T6_MCA_MY2020_Tx" SG_ 909 KeyMykeyTot_No_Cnt 1;
BA_ "U_CD542_MY2021_Tx" SG_ 909 KeyMykeyTot_No_Cnt 1;
BA_ "U_U55X_MY2022_Tx" SG_ 909 KeyMykeyTot_No_Cnt 1;
BA_ "U_CD764_MY2022_Tx" SG_ 909 KeyMykeyTot_No_Cnt 1;
BA_ "GenSigSendType" SG_ 909 Keycode_Status 3;
BA_ "U_CX727_MY2021_Tx" SG_ 909 Keycode_Status 1;
BA_ "U_P702_MY2021_Tx" SG_ 909 Keycode_Status 1;
BA_ "U_T6_MCA_MY2020_Tx" SG_ 909 Keycode_Status 1;
BA_ "U_CD542_MY2021_Tx" SG_ 909 Keycode_Status 1;
BA_ "U_U55X_MY2022_Tx" SG_ 909 Keycode_Status 1;
BA_ "U_CD764_MY2022_Tx" SG_ 909 Keycode_Status 1;
BA_ "MetaData" SG_ 909 KeyAdmnTot_No_Cnt 1;
BA_ "GenSigSendType" SG_ 909 KeyAdmnTot_No_Cnt 3;
BA_ "U_CX727_MY2021_Tx" SG_ 909 KeyAdmnTot_No_Cnt 1;
BA_ "U_P702_MY2021_Tx" SG_ 909 KeyAdmnTot_No_Cnt 1;
BA_ "U_T6_MCA_MY2020_Tx" SG_ 909 KeyAdmnTot_No_Cnt 1;
BA_ "U_CD542_MY2021_Tx" SG_ 909 KeyAdmnTot_No_Cnt 1;
BA_ "U_U55X_MY2022_Tx" SG_ 909 KeyAdmnTot_No_Cnt 1;
BA_ "U_CD764_MY2022_Tx" SG_ 909 KeyAdmnTot_No_Cnt 1;
BA_ "U_CX727_MY2021_Rx" SG_ 936 ApaSteScanMde_D_Stat 1;
BA_ "U_P702_MY2021_Rx" SG_ 936 ApaSteScanMde_D_Stat 1;
BA_ "U_T6_MCA_MY2020_Rx" SG_ 936 ApaSteScanMde_D_Stat 1;
BA_ "U_CD542_MY2021_Rx" SG_ 936 ApaSteScanMde_D_Stat 1;
BA_ "U_U55X_MY2022_Rx" SG_ 936 ApaSteScanMde_D_Stat 1;
BA_ "U_CD764_MY2022_Rx" SG_ 936 ApaSteScanMde_D_Stat 1;
BA_ "U_CX727_MY2021_Rx" SG_ 936 SAPPStatusCoding 1;
BA_ "U_P702_MY2021_Rx" SG_ 936 SAPPStatusCoding 1;
BA_ "U_T6_MCA_MY2020_Rx" SG_ 936 SAPPStatusCoding 1;
BA_ "U_CD542_MY2021_Rx" SG_ 936 SAPPStatusCoding 1;
BA_ "U_U55X_MY2022_Rx" SG_ 936 SAPPStatusCoding 1;
BA_ "U_CD764_MY2022_Rx" SG_ 936 SAPPStatusCoding 1;
BA_ "U_CX727_MY2021_Rx" SG_ 936 EPASExtAngleStatReq 1;
BA_ "U_P702_MY2021_Rx" SG_ 936 EPASExtAngleStatReq 1;
BA_ "U_T6_MCA_MY2020_Rx" SG_ 936 EPASExtAngleStatReq 1;
BA_ "U_CD542_MY2021_Rx" SG_ 936 EPASExtAngleStatReq 1;
BA_ "U_U55X_MY2022_Rx" SG_ 936 EPASExtAngleStatReq 1;
BA_ "U_CD764_MY2022_Rx" SG_ 936 EPASExtAngleStatReq 1;
BA_ "U_CX727_MY2021_Tx" SG_ 951 TirePress_Info_MaxInd 1;
BA_ "U_P702_MY2021_Tx" SG_ 951 TirePress_Info_MaxInd 1;
BA_ "U_T6_MCA_MY2020_Tx" SG_ 951 TirePress_Info_MaxInd 1;
BA_ "U_CD542_MY2021_Tx" SG_ 951 TirePress_Info_MaxInd 1;
BA_ "U_U55X_MY2022_Tx" SG_ 951 TirePress_Info_MaxInd 1;
BA_ "U_CD764_MY2022_Tx" SG_ 951 TirePress_Info_MaxInd 1;
BA_ "U_CX727_MY2021_Tx" SG_ 951 TirePress_Info_Index 1;
BA_ "U_P702_MY2021_Tx" SG_ 951 TirePress_Info_Index 1;
BA_ "U_T6_MCA_MY2020_Tx" SG_ 951 TirePress_Info_Index 1;
BA_ "U_CD542_MY2021_Tx" SG_ 951 TirePress_Info_Index 1;
BA_ "U_U55X_MY2022_Tx" SG_ 951 TirePress_Info_Index 1;
BA_ "U_CD764_MY2022_Tx" SG_ 951 TirePress_Info_Index 1;
BA_ "U_CX727_MY2021_Tx" SG_ 951 TirePress_Info_ID 1;
BA_ "U_P702_MY2021_Tx" SG_ 951 TirePress_Info_ID 1;
BA_ "U_T6_MCA_MY2020_Tx" SG_ 951 TirePress_Info_ID 1;
BA_ "U_CD542_MY2021_Tx" SG_ 951 TirePress_Info_ID 1;
BA_ "U_U55X_MY2022_Tx" SG_ 951 TirePress_Info_ID 1;
BA_ "U_CD764_MY2022_Tx" SG_ 951 TirePress_Info_ID 1;
BA_ "U_CX727_MY2021_Tx" SG_ 950 RemoteKey_Info_MaxInd 1;
BA_ "U_P702_MY2021_Tx" SG_ 950 RemoteKey_Info_MaxInd 1;
BA_ "U_T6_MCA_MY2020_Tx" SG_ 950 RemoteKey_Info_MaxInd 1;
BA_ "U_CD542_MY2021_Tx" SG_ 950 RemoteKey_Info_MaxInd 1;
BA_ "U_U55X_MY2022_Tx" SG_ 950 RemoteKey_Info_MaxInd 1;
BA_ "U_CD764_MY2022_Tx" SG_ 950 RemoteKey_Info_MaxInd 1;
BA_ "U_CX727_MY2021_Tx" SG_ 950 RemoteKey_Info_Index 1;
BA_ "U_P702_MY2021_Tx" SG_ 950 RemoteKey_Info_Index 1;
BA_ "U_T6_MCA_MY2020_Tx" SG_ 950 RemoteKey_Info_Index 1;
BA_ "U_CD542_MY2021_Tx" SG_ 950 RemoteKey_Info_Index 1;
BA_ "U_U55X_MY2022_Tx" SG_ 950 RemoteKey_Info_Index 1;
BA_ "U_CD764_MY2022_Tx" SG_ 950 RemoteKey_Info_Index 1;
BA_ "U_CX727_MY2021_Tx" SG_ 950 RemoteKey_Info_Ctrl 1;
BA_ "U_P702_MY2021_Tx" SG_ 950 RemoteKey_Info_Ctrl 1;
BA_ "U_T6_MCA_MY2020_Tx" SG_ 950 RemoteKey_Info_Ctrl 1;
BA_ "U_CD542_MY2021_Tx" SG_ 950 RemoteKey_Info_Ctrl 1;
BA_ "U_U55X_MY2022_Tx" SG_ 950 RemoteKey_Info_Ctrl 1;
BA_ "U_CD764_MY2022_Tx" SG_ 950 RemoteKey_Info_Ctrl 1;
BA_ "U_CX727_MY2021_Tx" SG_ 950 RemoteKey_Info_TIC 1;
BA_ "U_P702_MY2021_Tx" SG_ 950 RemoteKey_Info_TIC 1;
BA_ "U_T6_MCA_MY2020_Tx" SG_ 950 RemoteKey_Info_TIC 1;
BA_ "U_CD542_MY2021_Tx" SG_ 950 RemoteKey_Info_TIC 1;
BA_ "U_U55X_MY2022_Tx" SG_ 950 RemoteKey_Info_TIC 1;
BA_ "U_CD764_MY2022_Tx" SG_ 950 RemoteKey_Info_TIC 1;
BA_ "U_CX727_MY2021_Tx" SG_ 950 Modulation_Ctrl 1;
BA_ "U_P702_MY2021_Tx" SG_ 950 Modulation_Ctrl 1;
BA_ "U_T6_MCA_MY2020_Tx" SG_ 950 Modulation_Ctrl 1;
BA_ "U_CD542_MY2021_Tx" SG_ 950 Modulation_Ctrl 1;
BA_ "U_U55X_MY2022_Tx" SG_ 950 Modulation_Ctrl 1;
BA_ "U_CD764_MY2022_Tx" SG_ 950 Modulation_Ctrl 1;
BA_ "GenSigStartValueInteger" SG_ 950 TirePress_Filter_Ctrl 2;
BA_ "GenSigStartValue" SG_ 950 TirePress_Filter_Ctrl 2;
BA_ "GenSigSendType" SG_ 950 TirePress_Filter_Ctrl 3;
BA_ "U_CX727_MY2021_Tx" SG_ 950 TirePress_Filter_Ctrl 1;
BA_ "U_P702_MY2021_Tx" SG_ 950 TirePress_Filter_Ctrl 1;
BA_ "U_T6_MCA_MY2020_Tx" SG_ 950 TirePress_Filter_Ctrl 1;
BA_ "U_CD542_MY2021_Tx" SG_ 950 TirePress_Filter_Ctrl 1;
BA_ "U_U55X_MY2022_Tx" SG_ 950 TirePress_Filter_Ctrl 1;
BA_ "U_CD764_MY2022_Tx" SG_ 950 TirePress_Filter_Ctrl 1;
BA_ "U_CX727_MY2021_Rx" SG_ 71 immoTarget1Status 1;
BA_ "U_P702_MY2021_Rx" SG_ 71 immoTarget1Status 1;
BA_ "U_T6_MCA_MY2020_Rx" SG_ 71 immoTarget1Status 1;
BA_ "U_CD542_MY2021_Rx" SG_ 71 immoTarget1Status 1;
BA_ "U_U55X_MY2022_Rx" SG_ 71 immoTarget1Status 1;
BA_ "U_CD764_MY2022_Rx" SG_ 71 immoTarget1Status 1;
BA_ "U_CX727_MY2021_Rx" SG_ 71 immoTarget1Data 1;
BA_ "U_P702_MY2021_Rx" SG_ 71 immoTarget1Data 1;
BA_ "U_T6_MCA_MY2020_Rx" SG_ 71 immoTarget1Data 1;
BA_ "U_CD542_MY2021_Rx" SG_ 71 immoTarget1Data 1;
BA_ "U_U55X_MY2022_Rx" SG_ 71 immoTarget1Data 1;
BA_ "U_CD764_MY2022_Rx" SG_ 71 immoTarget1Data 1;
BA_ "U_CX727_MY2021_Rx" SG_ 71 immoTarget1Cmd 1;
BA_ "U_P702_MY2021_Rx" SG_ 71 immoTarget1Cmd 1;
BA_ "U_T6_MCA_MY2020_Rx" SG_ 71 immoTarget1Cmd 1;
BA_ "U_CD542_MY2021_Rx" SG_ 71 immoTarget1Cmd 1;
BA_ "U_U55X_MY2022_Rx" SG_ 71 immoTarget1Cmd 1;
BA_ "U_CD764_MY2022_Rx" SG_ 71 immoTarget1Cmd 1;
VAL_ 1069 SlMde_D_Stat 3 "IsaNotConfigured" 2 "Manual_Mode" 1 "Auto_Mode" 0 "Null" ;
VAL_ 1069 SlMde_D_RqDsply 3 "NotUsed" 2 "ManualSpeed_LimiterSymbol" 1 "AutoSpeed_LimiterSymbol" 0 "NoSpeed_LimiterSymbol" ;
VAL_ 1069 IsaOffst_D_Stat 15 "Faulty" 14 "Null" 13 "Thirteen" 12 "Twelve" 11 "Eleven" 10 "Ten" 9 "Nine" 8 "Eight" 7 "Seven" 6 "Six" 5 "Five" 4 "Four" 3 "Three" 2 "Two" 1 "One" 0 "Zero" ;
VAL_ 1069 ReFuelSysStat_D_Dsply 7 "NotUsed3" 6 "NotUsed2" 5 "NotUsed1" 4 "Refuel_Err" 3 "Close_Fuel_Door" 2 "Refuel_Ready" 1 "Wait_To_Fuel" 0 "Null" ;
VAL_ 1069 ULoSrcOnPlg_B_Cmd 1 "Activate" 0 "Deactivate" ;
VAL_ 1069 EngOilMaint_B_Stat 1 "On" 0 "Off" ;
VAL_ 1069 GrllShtrPos_D_Cmd 15 "Fully_Open" 14 "Position14" 13 "Position13" 12 "Position12" 11 "Position11" 10 "Position10" 9 "Position9" 8 "Position8" 7 "Position7" 6 "Position6" 5 "Position5" 4 "Position4" 3 "Position3" 2 "Position2" 1 "Position1" 0 "Fully_Closed" ;
VAL_ 1069 GrllShtrPos_B_Falt 1 "Fault" 0 "No_Fault" ;
VAL_ 1069 ObdWarmUp_B_Complt 1 "Yes" 0 "No" ;
VAL_ 1069 EngMsgTxt_D_Rq 3 "Undefined_2" 2 "Undefined_1" 1 "Power_Reduced_to_LowerTemp" 0 "No_Message" ;
VAL_ 1069 EngAirIn_Te_Actl 1023 "Fault" 1022 "Unknown" ;
VAL_ 1069 TracKeyMdeEnbl_B_Stat 1 "On" 0 "Off" ;
VAL_ 878 PwBedPnlEnblScnd_B_Rq 1 "Enable" 0 "Disable" ;
VAL_ 878 DcacSysScnd_B_Falt 1 "Yes" 0 "No" ;
VAL_ 878 DcacOnScnd_B_Rq 1 "Enable" 0 "Disable" ;
VAL_ 878 DcacGfciTestScnd_B_Rq 1 "Pressed" 0 "Not_Pressed" ;
VAL_ 878 EngExhMdeHrStrt_D_Stat 31 "NotUsed_7" 30 "NotUsed_6" 29 "NotUsed_5" 28 "NotUsed_4" 27 "NotUsed_3" 26 "NotUsed_2" 25 "NotUsed_1" 24 "Hour23_11pm" 23 "Hour22_10pm" 22 "Hour21_9pm" 21 "Hour20_8pm" 20 "Hour19_7pm" 19 "Hour18_6pm" 18 "Hour17_5pm" 17 "Hour16_4pm" 16 "Hour15_3pm" 15 "Hour14_2pm" 14 "Hour13_1pm" 13 "Hour12_12pm" 12 "Hour11_11am" 11 "Hour10_10am" 10 "Hour9_9am" 9 "Hour8_8am" 8 "Hour7_7am" 7 "Hour6_6am" 6 "Hour5_5am" 5 "Hour4_4am" 4 "Hour3_3am" 3 "Hour2_2am" 2 "Hour1_1am" 1 "Hour0_12am" 0 "Null" ;
VAL_ 878 EngExhMdeHrEnd_D_Stat 31 "NotUsed_7" 30 "NotUsed_6" 29 "NotUsed_5" 28 "NotUsed_4" 27 "NotUsed_3" 26 "NotUsed_2" 25 "NotUsed_1" 24 "Hour23_11pm" 23 "Hour22_10pm" 22 "Hour21_9pm" 21 "Hour20_8pm" 20 "Hour19_7pm" 19 "Hour18_6pm" 18 "Hour17_5pm" 17 "Hour16_4pm" 16 "Hour15_3pm" 15 "Hour14_2pm" 14 "Hour13_1pm" 13 "Hour12_12pm" 12 "Hour11_11am" 11 "Hour10_10am" 10 "Hour9_9am" 9 "Hour8_8am" 8 "Hour7_7am" 7 "Hour6_6am" 6 "Hour5_5am" 5 "Hour4_4am" 4 "Hour3_3am" 3 "Hour2_2am" 2 "Hour1_1am" 1 "Hour0_12am" 0 "Null" ;
VAL_ 878 EngExhMdeHrEnbl_D_Stat 3 "NotUsed" 2 "Enabled" 1 "Disabled" 0 "Null" ;
VAL_ 878 DcacGfciTest_B_Rq 1 "Pressed" 0 "Not_Pressed" ;
VAL_ 878 DcacOut_Pw_DsplyMx 1023 "Faulty" ;
VAL_ 878 DcacOut1_Pw_Dsply 63 "Faulty" ;
VAL_ 878 DcacOut2_Pw_Dsply 63 "Faulty" ;
VAL_ 878 DcacHw_D_Confg 15 "NotUsed_11" 14 "NotUsed_10" 13 "NotUsed_9" 12 "NotUsed_8" 11 "NotUsed_7" 10 "NotUsed_6" 9 "NotUsed_5" 8 "NotUsed_4" 7 "NotUsed_3" 6 "NotUsed_2" 5 "NotUsed_1" 4 "Power_2300W" 3 "Power_7200W" 2 "Power_2400W" 1 "Power_2000W" 0 "NoDcacHardware" ;
VAL_ 878 DcacFaltMsgTxt_D_Rq 15 "HvacOn" 14 "OvercurrentLP" 13 "EngineRun" 12 "Service" 11 "NotAvailable" 10 "PlugWarn" 9 "PlugWarnDrive" 8 "BreakerC" 7 "BreakerB" 6 "BreakerA" 5 "FuelLow" 4 "AcOnOutput" 3 "Temperature" 2 "Gfci" 1 "Overcurrent" 0 "Ok" ;
VAL_ 878 DcacLoFuelMsgTxt_D_Rq 31 "Minute_31" 30 "Minute_30" 29 "Minute_29" 28 "Minute_28" 27 "Minute_27" 26 "Minute_26" 25 "Minute_25" 24 "Minute_24" 23 "Minute_23" 22 "Minute_22" 21 "Minute_21" 20 "Minute_20" 19 "Minute_19" 18 "Minute_18" 17 "Minute_17" 16 "Minute_16" 15 "Minute_15" 14 "Minute_14" 13 "Minute_13" 12 "Minute_12" 11 "Minute_11" 10 "Minute_10" 9 "Minute_9" 8 "Minute_8" 7 "Minute_7" 6 "Minute_6" 5 "Minute_5" 4 "Minute_4" 3 "Minute_3" 2 "Minute_2" 1 "Minute_1" 0 "Ok" ;
VAL_ 878 DcacEngOnMsgTxt_D_Rq 3 "NotUsed" 2 "DisplayQuestion" 1 "DisplayWarning" 0 "Ok" ;
VAL_ 878 DcacElPw_D_Stat 3 "NotUsed" 2 "High" 1 "Low" 0 "Off" ;
VAL_ 878 PwBedPnlEnbl_B_Rq 1 "Enable" 0 "Disable" ;
VAL_ 878 DcacOn_B_Rq 1 "Enable" 0 "Disable" ;
VAL_ 878 DcacSys_B_Falt 1 "Yes" 0 "No" ;
VAL_ 878 DcacLedCtl_D_Rq 3 "Fast_Flash" 2 "Slow_Flash" 1 "On" 0 "Off" ;
VAL_ 1200 BrkHold_D_Stat 7 "NotUsed_3" 6 "NotUsed_2" 5 "NotUsed_1" 4 "HeldSecondary" 3 "HeldSecure" 2 "Held" 1 "Inactive" 0 "Off" ;
VAL_ 1200 BrkRearPCorrltn_B_Stat 1 "Yes" 0 "No" ;
VAL_ 1200 HsaStat_D_Dsply 7 "NotUsed3" 6 "NotUsed2" 5 "NotUsed1" 4 "NotAvailable" 3 "SlowReleaseWithChime" 2 "SlowReleaseWithoutChime" 1 "Active" 0 "Inactive" ;
VAL_ 1200 HsaTrnAout_Tq_Rq 65535 "Fault" 65534 "Unknown" ;
VAL_ 1200 BrkBstrVac_P_Actl 127 "Invalid" ;
VAL_ 1200 YawStabilityIndex 511 "Fault" 510 "NoDataExists" ;
VAL_ 1200 BrkTot_Tq_RqDrv 8191 "Fault" ;
VAL_ 376 GasPrtc_D_RqDsply 7 "NotUsed_5" 6 "NotUsed_4" 5 "NotUsed_3" 4 "NotUsed_2" 3 "NotUsed_1" 2 "GpfOverLimit" 1 "GpfAtLimit" 0 "NormalOperation" ;
VAL_ 376 LnchCtlSys_D_Stat 7 "NotUsed3" 6 "NotUsed2" 5 "NotUsed1" 4 "On_LC_Unavailable_TC_On" 3 "On_LC_Unavailable" 2 "On_LC_Available" 1 "On_LC_Active" 0 "LC_OFF" ;
VAL_ 376 DynoMde_B_Cmd 1 "DynomometerMode" 0 "NormalOperation" ;
VAL_ 376 AslIconDsply_D_Rq 3 "On_Passive_Overridden" 2 "On_Active" 1 "On_Passive" 0 "Off" ;
VAL_ 376 AslChime_B_Rq 1 "Yes" 0 "No" ;
VAL_ 376 HvacHtrCore2_Te_Actl 1023 "Faulty" ;
VAL_ 376 PtcHtr_D_Cmd 3 "TurnOn" 2 "AutoMode" 1 "TurnOff" 0 "NoDecision_Initializing" ;
VAL_ 376 EcssLamp_D_RqDsply 3 "Not_Used" 2 "Flash" 1 "On" 0 "Off" ;
VAL_ 376 AirAmbTe_D_Qf 3 "OK" 2 "Not_Within_Specifications" 1 "No_Data_Exists" 0 "Faulty" ;
VAL_ 376 AirAmb_P_Actl 63 "Fault" 62 "NoDataExists" ;
VAL_ 516 EngAoutNActl_D_QF 3 "OK" 2 "Not_Within_Specifications" 1 "No_Data_Exists" 0 "Faulty" ;
VAL_ 516 EngAout3_N_Actl 65535 "Invalid" ;
VAL_ 516 ApedPos_PcRate_ActlArb 255 "Fault" 254 "Unknown" ;
VAL_ 516 ApedPosPcActl_D_Qf 3 "OK" 2 "Not_Within_Specifications" 1 "No_Data_Exists" 0 "Faulty" ;
VAL_ 377 HvacAirFullOut_B_Rq 1 "Yes" 0 "No" ;
VAL_ 377 TrnManShif_D_IndDrv 7 "Undefined_3" 6 "Undefined_2" 5 "Shift_to_Neutral" 4 "Downshift_Recommendation" 3 "Upshift_Warning" 2 "Upshift_Performance" 1 "Upshift_Fuel_Economy" 0 "No_Indication" ;
VAL_ 377 TrnManShifGear_D_IndDrv 7 "Indicate_Reverse_Gear" 6 "Indicate_Gear6" 5 "Indicate_Gear5" 4 "Indicate_Gear4" 3 "Indicate_Gear3" 2 "Indicate_Gear2" 1 "Indicate_Gear1" 0 "No_Indication" ;
VAL_ 377 EngFuelCutFull_B_Inhbt 1 "Inhibit_DFSO" 0 "Normal" ;
VAL_ 377 EngDecelFuelCut_B_Allw 1 "Yes" 0 "No" ;
VAL_ 377 FuelFillInlet_B_Dsply 1 "Yes" 0 "No" ;
VAL_ 377 EngSrvcRqd_B_Rq 1 "Engine_Service_Required" 0 "No_engine_service_required" ;
VAL_ 377 OdoCount 255 "Invalid" ;
VAL_ 377 TrnKickDown_B_RqDrv 1 "Yes" 0 "No" ;
VAL_ 377 FuelFilterLamp_B_Dsply 1 "On" 0 "Off" ;
VAL_ 377 AirCondRec_B_Rq 1 "Yes" 0 "No" ;
VAL_ 377 AirCondClutch_B_Stats 1 "Yes" 0 "No" ;
VAL_ 377 EngAoutTqActl_D_Qf 3 "OK" 2 "Not_Within_Specifications" 1 "No_Data_Exists" 0 "Faulty" ;
VAL_ 76 RstrnPsngrOn_D_Stat 15 "Faulty" 14 "NotUsed_11" 13 "NotUsed_10" 12 "ConfiguredOff" 11 "NotUsed_9" 10 "On" 9 "NotUsed_8" 8 "NotUsed_7" 7 "NotUsed_6" 6 "NotUsed_5" 5 "Off" 4 "NotUsed_4" 3 "NotUsed_3" 2 "NotUsed_2" 1 "NotUsed_1" 0 "NoAction" ;
VAL_ 76 PsngrFmidDetct_D_Actl 3 "Unknown" 2 "Empty" 1 "Occupied" 0 "Fault" ;
VAL_ 76 FirstRowBuckleMid 3 "Unknown" 2 "Unbelted" 1 "Belted" 0 "Faulty" ;
VAL_ 76 ThirdRowBucklePsngr 3 "Unknown" 2 "Unbelted" 1 "Belted" 0 "Faulty" ;
VAL_ 76 ThirdRowBuckleMid 3 "Unknown" 2 "Unbelted" 1 "Belted" 0 "Faulty" ;
VAL_ 76 ThirdRowBuckleDriver 3 "Unknown" 2 "Unbelted" 1 "Belted" 0 "Faulty" ;
VAL_ 76 SecondRowBucklePsngr 3 "Unknown" 2 "Unbelted" 1 "Belted" 0 "Faulty" ;
VAL_ 76 SecondRowBuckleMid 3 "Unknown" 2 "Unbelted" 1 "Belted" 0 "Faulty" ;
VAL_ 76 SecondRowBuckleDriver 3 "Unknown" 2 "Unbelted" 1 "Belted" 0 "Faulty" ;
VAL_ 76 FirstRowBuckleDriver 3 "Unknown" 2 "Unbelted" 1 "Belted" 0 "Faulty" ;
VAL_ 76 RILReq 3 "Not_Used" 2 "Plant_Mode" 1 "On" 0 "Off" ;
VAL_ 76 FirstRowBucklePsngr 3 "Unknown" 2 "Unbelted" 1 "Belted" 0 "Faulty" ;
VAL_ 76 RstrnImpactEvntStatus 7 "Invalid" 6 "Not_Used_4" 5 "Threshold_2_Exceeded" 4 "Not_Used_3" 3 "Threshold_1_Exceeded" 2 "Not_Used_2" 1 "Not_Used_1" 0 "Normal" ;
VAL_ 76 PsngrFrntDetct_D_Actl 3 "Unknown" 2 "Empty" 0 "Faulty" 1 "Occupied" ;
VAL_ 76 EDRTriggerEvntSync 1 "Threshold_Exceeded" 0 "Normal" ;
VAL_ 76 PassRstrnInd_Req 3 "ABOnNotIllum_OffNotIllum" 2 "AirbagOnNot_Illum_OffIllum" 1 "AirbagOn_Illum_OffNotIllum" 0 "AirbagOn_Illum_Off_Illum" ;
VAL_ 967 CamraViewSplit_D_Actl 3 "NotUsed" 2 "Inactive" 1 "Active" 0 "Invalid" ;
VAL_ 967 CamraOvrlTow_D_Actl 3 "Not_Used" 2 "Inactive" 1 "Active" 0 "Invalid" ;
VAL_ 967 CamZoomActiveState 3 "Not_Used" 2 "Inactive" 1 "Active" 0 "Invalid" ;
VAL_ 967 CamraZoomMan_D_Actl 7 "Unknown" 6 "Invalid" 5 "Zoom_Level_V" 4 "Zoom_Level_IV" 3 "Zoom_Level_III" 2 "Zoom_Level_II" 1 "Zoom_Level_I" 0 "Off" ;
VAL_ 967 CamraOvrlStat_D_Actl 3 "Not_Used" 2 "Inactive" 1 "Active" 0 "Invalid" ;
VAL_ 967 CamraOvrlDyn_D_Actl 3 "Not_Used" 2 "Inactive" 1 "Active" 0 "Invalid" ;
VAL_ 967 CamPDCGuidStat 3 "Not_Used" 2 "Inactive" 1 "Active" 0 "Invalid" ;
VAL_ 949 Tire_Press_RR_ORR_Data 65535 "Not_Supported" 65534 "Invalid" 65533 "Unknown" ;
VAL_ 949 Tire_Press_LR_OLR_Data 65535 "Not_Supported" 65534 "Invalid" 65533 "Unknown" ;
VAL_ 949 Tire_Press_LF_Data 65535 "Not_Supported" 65534 "Invalid" 65533 "Unknown" ;
VAL_ 949 Tire_Press_RF_Data 65535 "Not_Supported" 65534 "Invalid" 65533 "Unknown" ;
VAL_ 948 Tire_Press_ILR_Stat 4 "Alert" 15 "Not_Supported" 3 "Fault" 2 "Low" 1 "Normal" 0 "Unknown" ;
VAL_ 948 Tire_Press_IRR_Stat 4 "Alert" 15 "Not_Supported" 3 "Fault" 2 "Low" 1 "Normal" 0 "Unknown" ;
VAL_ 948 Tire_Press_LR_OLR_Stat 4 "Alert" 15 "Not_Supported" 3 "Fault" 2 "Low" 1 "Normal" 0 "Unknown" ;
VAL_ 948 Tire_Press_RR_ORR_Stat 4 "Alert" 15 "Not_Supported" 3 "Fault" 2 "Low" 1 "Normal" 0 "Unknown" ;
VAL_ 948 Tire_Press_RF_Stat 4 "Alert" 15 "Not_Supported" 3 "Fault" 2 "Low" 1 "Normal" 0 "Unknown" ;
VAL_ 948 Tire_Press_LF_Stat 4 "Alert" 15 "Not_Supported" 3 "Fault" 2 "Low" 1 "Normal" 0 "Unknown" ;
VAL_ 948 Tire_Press_System_Stat 13 "Training_Complete" 12 "Train_InsideLeftRear_tire" 11 "Train_OutsideLeftRear_tire" 10 "Train_LeftRear_tire" 9 "Train_InsideRtRear_tire" 8 "Train_OutsideRtRear_tire" 7 "Train_RightRear_tire" 14 "Tires_not_trained" 6 "Train_RightFront_tire" 5 "Train_LeftFront_tire" 4 "Systm_Activ_Composite_Stat" 3 "Low_Composite_Stat" 2 "Sensr_Fault_Composite_Stat" 1 "Systm_Fault_Composite_Stat" 0 "Unknown_Composite_Stat" ;
VAL_ 948 Tire_Press_Telltale 3 "Not_Used" 2 "Flash" 1 "On" 0 "Off" ;
VAL_ 948 TirePReset_D_Stat 3 "Not_Used" 2 "Nack" 1 "Ack" 0 "Null" ;
VAL_ 1077 PrkLckCtlEnbl_D_RqIpc_UB 1 "Fresh_data" 0 "Unchanged_data" ;
VAL_ 1077 PrkLckCtlEnbl_D_RqIpc 3 "Rq_Towing" 2 "Rq_Enable" 1 "Rq_Disable" 0 "Null" ;
VAL_ 1077 FuelLvl_Pc_Dsply_UB 1 "Fresh_data" 0 "Unchanged_data" ;
VAL_ 1077 PtWakeupActv1_B_Rq 1 "Wake_up_Powertrain_via_HW" 0 "Don_t_Wake_Up_Powertrain" ;
VAL_ 1077 PtWakeupActv1_B_Rq_UB 1 "Fresh_data" 0 "Unchanged_data" ;
VAL_ 1077 Remote_Start_Req_UB 1 "Fresh_data" 0 "Unchanged_data" ;
VAL_ 1077 Remote_Start_Req 3 "Not_Used" 2 "Remote_Cancel" 1 "Remote_Start" 0 "No_Request" ;
VAL_ 1077 TurnLampTrlrRr_B_Stat_UB 1 "Fresh_data" 0 "Unchanged_data" ;
VAL_ 1077 DistanceBarSetting_UB 1 "Fresh_data" 0 "Unchanged_data" ;
VAL_ 1077 CamraZoomMan_D_Rq_UB 1 "Fresh_data" 0 "Unchanged_data" ;
VAL_ 1077 CamraOvrlStat_D_Rq_UB 1 "Fresh_data" 0 "Unchanged_data" ;
VAL_ 1077 CamraOvrlDyn_D_Rq_UB 1 "Fresh_data" 0 "Unchanged_data" ;
VAL_ 1077 CamAutoTowbarZoom_UB 1 "Fresh_data" 0 "Unchanged_data" ;
VAL_ 1077 DistanceBarSetting 1 "On" 0 "Off" ;
VAL_ 1077 CamraZoomMan_D_Rq 7 "Unknown" 6 "Invalid" 5 "Zoom_Level_V" 4 "Zoom_Level_IV" 3 "Zoom_Level_III" 2 "Zoom_Level_II" 1 "Zoom_Level_I" 0 "Off" ;
VAL_ 1077 CamraOvrlStat_D_Rq 1 "On" 0 "Off" ;
VAL_ 1077 CamraOvrlDyn_D_Rq 1 "On" 0 "Off" ;
VAL_ 1077 CamAutoTowbarZoom 1 "On" 0 "Off" ;
VAL_ 1077 PwLftgtIntSw_B_Stat_UB 1 "Fresh_data" 0 "Unchanged_data" ;
VAL_ 1077 PwLftgtIntSw_B_Stat 1 "Pressed" 0 "Null" ;
VAL_ 1077 TurnLampTrlrRl_B_Stat_UB 1 "Fresh_data" 0 "Unchanged_data" ;
VAL_ 1077 TurnLampTrlrRr_B_Stat 1 "Out" 0 "Null" ;
VAL_ 1077 TurnLampTrlrRl_B_Stat 1 "Out" 0 "Null" ;
VAL_ 862 EcoMde_D_RqDrv 3 "Faulty" 2 "On" 1 "Off" 0 "Null" ;
VAL_ 862 TwHlGrdAsst_B_RqTrn 1 "On" 0 "Off" ;
VAL_ 862 ApaSwtch_D_RqDrv 3 "NotUsed2" 2 "NotUsed1" 1 "Pressed" 0 "Not_Pressed" ;
VAL_ 862 HvacBlwrFront_D_Stat 31 "Not_Used" 20 "Full_On" 19 "95_Percent" 18 "90_Percent" 17 "85_Percent" 16 "80_Percent" 15 "75_Percent" 14 "70_Percent" 13 "65_Percent" 12 "60_Percent" 11 "55_Percent" 10 "50_Percent" 9 "45_Percent" 8 "40_Percent" 7 "35_Percent" 6 "30_Percent" 5 "25_Percent" 4 "20_Percent" 3 "15_Percent" 2 "10_Percent" 1 "5_Percent" 0 "Off" ;
VAL_ 862 HvacBlwrRear_D_Stat 31 "Not_Used" 20 "Full_On" 19 "95_Percent" 18 "90_Percent" 17 "85_Percent" 16 "80_Percent" 15 "75_Percent" 14 "70_Percent" 13 "65_Percent" 12 "60_Percent" 11 "55_Percent" 10 "50_Percent" 9 "45_Percent" 8 "40_Percent" 7 "35_Percent" 6 "30_Percent" 5 "25_Percent" 4 "20_Percent" 3 "15_Percent" 2 "10_Percent" 1 "5_Percent" 0 "Off" ;
VAL_ 862 CabnAmb_Te_Actl 255 "Fault" ;
VAL_ 862 ClimtThrmlLoad_No_Actl 255 "Fault" ;
VAL_ 862 CamraDefog_B_Actl 1 "On" 0 "Off" ;
VAL_ 862 AutoStpHvacDelta_I_Est 255 "Fault" ;
VAL_ 342 HtrLoop_B_Stat 1 "Fault" 0 "No_Fault" ;
VAL_ 342 TqmTerrMdeChng_D_Rdy 7 "Fault" 6 "Undefined_2" 5 "Undefined_1" 4 "ModeUnavailDrInputRqd" 3 "SpOpModes_NotSupported" 2 "ModeUnavailDynamicCond" 1 "Module_In_Initialization" 0 "Mode_Change_Available" ;
VAL_ 342 TqmTerrMde_D_Actl 7 "Fail_Safe_Default" 6 "Dynamic_Mode" 5 "Rock_Crawl_Mode" 4 "Mud_Ruts_Mode" 3 "Sand_Mode" 2 "Undefined" 1 "Low_Mu_Mode" 0 "Special_Operating_Mode_Off" ;
VAL_ 342 EngOvrhtMitgActv_D_Ind 3 "Undefined" 2 "Mode2" 1 "Mode1" 0 "Normal_Mode" ;
VAL_ 342 EngTeColdPrtct_B_Rq 1 "On" 0 "Off" ;
VAL_ 342 EngClntTe_D_Qf 3 "OK" 2 "Not_Within_Specifications" 1 "No_Data_Exists" 0 "Faulty" ;
VAL_ 342 EngAcsyArcPmp_Tq_Actl 255 "Fault" 254 "Unknown" ;
VAL_ 342 EngOilLvlDsply_D_Rq 15 "EngOil_LevelSys_CheckFault" 14 "Reserved_2" 13 "Reserved_1" 12 "Conditions_Unsuitable" 11 "Dipstick_Below_Minimum" 10 "Dipstick_Above_Maximum" 9 "Dipstick_Minimum" 8 "Dipstick_12_5_MinMaxRange" 7 "Dipstick_25_MinMaxRange" 6 "Dipstick_37_5_MinMaxRange" 5 "Dipstick_50_MinMaxRange" 4 "Dipstick_62_5_MinMaxRange" 3 "Dipstick_75_MinMaxRange" 2 "Dipstick_87_5_MinMaxRange" 1 "Dipstick_Maximum_Displayed" 0 "No_Message" ;
VAL_ 342 EngOil_Te_Actl 255 "Fault" 254 "Unknown" ;
VAL_ 992 MsgCntrPersIndex_D_Rq 7 "Unused_3" 6 "Unused_2" 5 "Unused_1" 4 "Vehicle" 3 "PERS_4" 2 "PERS_3" 1 "PERS_2" 0 "PERS_1" ;
VAL_ 992 MsgCntrDsplyOp_D_Rq 7 "Unused_2" 6 "Unused_1" 5 "Copy" 4 "Restore" 3 "Upload" 2 "Set" 1 "Query" 0 "Null" ;
VAL_ 994 PersCtaSplitView_D_Rq 3 "EnabledFull" 2 "Enabled_180SwitchOnly" 1 "Disabled" 0 "Null" ;
VAL_ 994 PersStore_D_Rq 7 "Unused_2" 6 "Unused_1" 5 "Vehicle" 4 "PERS_4" 3 "PERS_3" 2 "PERS_2" 1 "PERS_1" 0 "Null" ;
VAL_ 994 Pers4OptIn_B_Stats 1 "OPTED_IN" 0 "NOT_OPTED_IN" ;
VAL_ 994 Pers3OptIn_B_Stats 1 "OPTED_IN" 0 "NOT_OPTED_IN" ;
VAL_ 994 Pers2OptIn_B_Stats 1 "OPTED_IN" 0 "NOT_OPTED_IN" ;
VAL_ 994 Pers1OptIn_B_Stats 1 "OPTED_IN" 0 "NOT_OPTED_IN" ;
VAL_ 994 CtrStkPersIndex_D_Actl 7 "Unused_3" 6 "Unused_2" 5 "Unused_1" 4 "Vehicle" 3 "PERS_4" 2 "PERS_3" 1 "PERS_2" 0 "PERS_1" ;
VAL_ 994 CtrStkDsplyOp_D_Rq 7 "Unused_2" 6 "Unused_1" 5 "Copy" 4 "Restore" 3 "Upload" 2 "Set" 1 "Query" 0 "Null" ;
VAL_ 65 immoControlCmd_T1 0 "IDLE" 1 "MOTIVE_START_RQST" 2 "NONMOTIVE_START_RQST" 3 "RQST_TARGET1_IDBLOCK1" 4 "RQST_TARGET1_IDBLOCK2" 5 "LIMITEDMOTIVE_START_RQST" 6 "ECHO_TARGET1_IDBLOCK2" 7 "SHUTDOWN" ;
VAL_ 66 immoControlCmd_T2 0 "IDLE" 1 "MOTIVE_START_RQST" 2 "NONMOTIVE_START_RQST" 3 "RQST_TARGET2_IDBLOCK1" 4 "RQST_TARGET2_IDBLOCK2" 5 "LIMITEDMOTIVE_START_RQST" 6 "ECHO_TARGET2_IDBLOCK2" 7 "SHUTDOWN" ;
VAL_ 560 SelDrvMdeSwtch_D_Stat3 3 "Faulty" 2 "SwitchState2" 1 "SwitchState1" 0 "NotPressed" ;
VAL_ 560 TrnGbox_Rt_Actl 65535 "Fault" 65534 "Unknown" ;
VAL_ 560 TrnSrvcRqd_B_Rq 1 "On" 0 "Off" ;
VAL_ 560 TrnCnvtClu_D_Actl 3 "Transition_or_Micro_Slip" 2 "Lock_Up_Fixed" 1 "Lock_Up_Slip" 0 "No_Lock_Up" ;
VAL_ 560 TrnShifActv_B_Actl 1 "Active" 0 "Inactive" ;
VAL_ 560 RtmTerrMdeChng_D_Rdy 7 "Fault" 6 "Undefined_2" 5 "Undefined_1" 4 "ModeUnavailDrInputRqd" 3 "SpOpModes_NotSupported" 2 "ModeUnavailDynamicCond" 1 "Module_In_Initialization" 0 "Mode_Change_Available" ;
VAL_ 560 RtmTerrMde_D_Actl 7 "Fail_Safe_Default" 6 "Dynamic_Mode" 5 "Rock_Crawl_Mode" 4 "Mud_Ruts_Mode" 3 "Sand_Mode" 2 "Undefined" 1 "Low_Mu_Mode" 0 "Special_Operating_Mode_Off" ;
VAL_ 560 GearLvrPos_D_Actl 15 "Fault" 14 "Unknown_Position" 13 "Undefined_Treat_as__Fault" 12 "Undefined_Treat_as_Fault" 11 "sixth" 10 "fifth" 9 "fourth" 8 "third" 7 "second" 6 "first" 5 "Low" 4 "Sport_DriveSport" 3 "Drive" 2 "Neutral" 1 "Reverse" 0 "Park" ;
VAL_ 560 GboxOil_Te_Actl 255 "Faulty" 254 "NoDataExists" ;
VAL_ 357 BPedDrvAppl_D_QF 3 "OK" 2 "Not_Within_Specifications" 1 "No_Data_Exists" 0 "Faulty" ;
VAL_ 357 CmbbDeny_B_ActlPrpl 1 "Yes" 0 "No" ;
VAL_ 357 PrplTqMnSat_B_Actl 1 "Yes" 0 "No" ;
VAL_ 357 VehStrtStop_D_Rq 3 "NotUsed" 2 "Vehicle_Start_Request" 1 "Vehicle_Stop_Request" 0 "NoRequest" ;
VAL_ 357 BpedDrvAppl_D_Actl 3 "_Not_Allowed" 2 "Driver_Braking" 1 "Driver_Not_Braking" 0 "Not_Allowed" ;
VAL_ 357 CmbbEngTqMn_B_Actl 1 "Yes" 0 "No" ;
VAL_ 357 Veh_V_DsplyCcSet 255 "Fault" 254 "Unknown" ;
VAL_ 357 AccEngStat_D_Actl 7 "Undefined_2" 6 "Undefined_1" 5 "ACCSoonCancel_due_Low_Spd" 4 "Shift_Down_Recommendation" 3 "Shift_Up_Recommendation" 2 "ACCNotAllowedToBeActivated" 1 "ACCStandby_due_Auto_Cancel" 0 "Normal_Operation" ;
VAL_ 357 CcMde_D_Actl 7 "TapDownWaiting" 6 "TapUpWaiting" 5 "Resuming_Low" 4 "Resuming_High" 3 "Decelerating" 2 "Accelerating" 1 "Keeping_Speed" 0 "Not_Active" ;
VAL_ 357 CcStat_D_Actl 7 "Undefined_2" 6 "Undefined_1" 5 "Active" 4 "Active_Que_Assist" 3 "Standby" 2 "Standby_Denied" 1 "Denied" 0 "Off" ;
VAL_ 357 CcOvrrdActv_B_Actl 1 "Cruise_Overridden" 0 "Cruise_Req_Not_Overridden" ;
VAL_ 357 AccStopMde_D_Rq 3 "Stop_Mode_Active" 2 "EPBApplyOrBrakeReleaseWarn" 1 "Limit_Rolling_Speed" 0 "Stop_Mode_Not_Active" ;
VAL_ 1003 PersRecallSrc_D_Actl 7 "NotUsed_3" 6 "NotUsed_2" 5 "NotUsed_1" 4 "MemorySwitch" 3 "RemoteStart" 2 "KeyFob" 1 "CenterStack" 0 "Null" ;
VAL_ 1003 Pers4Key_D_Stat 3 "NotUsed_1" 2 "KeyUnAssociated" 1 "KeyAssociated" 0 "Null" ;
VAL_ 1003 Pers3Key_D_Stat 3 "NotUsed_1" 2 "KeyUnAssociated" 1 "KeyAssociated" 0 "Null" ;
VAL_ 1003 Pers2Key_D_Stat 3 "NotUsed_1" 2 "KeyUnAssociated" 1 "KeyAssociated" 0 "Null" ;
VAL_ 1003 Pers1Key_D_Stat 3 "NotUsed_1" 2 "KeyUnAssociated" 1 "KeyAssociated" 0 "Null" ;
VAL_ 1003 EmPrflNo_D_Stat 7 "NotUsed_3" 6 "NotUsed_2" 5 "NotUsed_1" 4 "Pers4" 3 "Pers3" 2 "Pers2" 1 "Pers1" 0 "Null" ;
VAL_ 1003 EmPrflKeyAssoc_D_Stat 7 "WrongDevice" 6 "KeyAssociateFailed" 5 "KeyAssociateSuccess" 4 "KeyAlreadyInUse" 3 "KeyDisassociated" 2 "KeyAssociationExited" 1 "KeyAssociationEntered" 0 "Null" ;
VAL_ 1003 VehKeyActv_D_Stat 15 "NotUsed7" 14 "NotUsed6" 13 "NotUsed5" 12 "NotUsed4" 11 "NotUsed3" 10 "NotUsed2" 9 "NotUsed1" 8 "Key8Active" 7 "Key7Active" 6 "Key6Active" 5 "Key5Active" 4 "Key4Active" 3 "Key3Active" 2 "Key2Active" 1 "Key1Active" 0 "NoKeyActive" ;
VAL_ 1003 PersNoPos_D_Actl 7 "Unused_3" 6 "Unused_2" 5 "Unused_1" 4 "Vehicle" 3 "PERS_4" 2 "PERS_3" 1 "PERS_2" 0 "PERS_1" ;
VAL_ 1003 PersSetupRestr_D_Actl 3 "Non_Moveable_Person" 2 "Moveable_Person" 1 "Vehicle" 0 "Factory" ;
VAL_ 1003 PersSetupAccessCtrl 1 "Limited" 0 "Full" ;
VAL_ 1003 PersConflict_D_Actl 1 "Conflict" 0 "No_Conflict" ;
VAL_ 1003 AssocConfirm_D_Actl 0 "None" 7 "Associate" 6 "Keycode_Rejected" 5 "Keycode_Accepted" 4 "In_Progress" 3 "Erase" 2 "Duplicate" 1 "Disassociate" ;
VAL_ 1003 PersNo_D_Actl 7 "Unused_3" 6 "Unused_2" 5 "NotDetermined" 4 "Vehicle" 3 "PERS_4" 2 "PERS_3" 1 "PERS_2" 0 "PERS_1" ;
VAL_ 1068 EngStrtInhbt_B_RqBatt 1 "Start_Inhibit" 0 "Dont_Care" ;
VAL_ 1068 BattULoChrg_D_Rq 3 "Low_Battery_Temperature" 2 "Charging_Requested" 1 "Chrg_Requested_HighCurrent" 0 "No_Request" ;
VAL_ 1068 PwSysULoFalt_D_Stat 15 "Not_Used_6" 14 "LowBatterySOC" 13 "PSS_Shed2_Contin" 12 "Not_Used_4" 11 "Not_Used_3" 10 "Not_Used_2" 9 "BattMonitoringSensorFault" 8 "LowBattVoltDuringPwSrcOn" 7 "LowBatt2_PowerSaveMode" 6 "LowBatt1_Warning" 5 "Overvoltage" 4 "Fault_NoOutput" 3 "Fault_ReducedOutput" 2 "Fault_Nonspecific" 1 "Cluster_Proveout" 0 "No_Fault" ;
VAL_ 1068 Shed_T_Eng_Off_B 1 "Active" 0 "Inactive" ;
VAL_ 1068 Shed_Feature_Group_ID 16 "PtcHeater" 30 "NotUsed_7" 29 "NotUsed_6" 28 "NotUsed_5" 27 "NotUsed_4" 26 "NotUsed_3" 25 "NotUsed_2" 24 "NotUsed_1" 23 "Dcac" 22 "UpFitter_6" 21 "UpFitter_5" 20 "UpFitter_4" 19 "UpFitter_3" 18 "UpFitter_2" 17 "UpFitter_1" 14 "HtdMirr" 13 "HvacRearBlwr_Third" 12 "HvacRearBlwr_Second" 11 "HvacRearBlwr_First" 31 "All LSHED1 Features" 10 "Htd_Windscrn" 9 "SpltHtdBcklight_HtdMirr" 8 "HtdBcklight_HtdMirr" 7 "HtdCoolSeat_FrtDriver" 6 "HtdCoolSeat_FrtPass" 5 "HtdCoolSeat_RearPass" 4 "HtdCoolSeat_RearDriver" 3 "SmartTrlrTowBattCharge" 2 "Htd_StrWhl" 1 "Htd_Washer_Fluid" 0 "No_LSHED1_Features" 15 "Engine_Coolant_Fan" ;
VAL_ 1068 Shed_Drain_Eng_Off_B 1 "Active" 0 "Inactive" ;
VAL_ 1068 Shed_Level_Req 7 "SHED3" 6 "Loads_On" 5 "SHED_ENG_OFF" 4 "SOON_ENG_OFF" 3 "SHED2_CONTIN" 2 "SHED2_TRANS" 1 "SHED1" 0 "NO_SHED" ;
VAL_ 1068 ULoRgenTestMde_B_Rq 1 "Request" 0 "NoRequest" ;
VAL_ 1068 ChargeMode 7 "Undefined_2" 6 "Undefined_1" 5 "Battery_Identify" 4 "Battery_Refresh" 3 "SlowRegenAllowNoDischarge" 2 "Fast_Regen_Allowed" 1 "Slow_Regen_Allowed" 0 "Conventional_Charging" ;
VAL_ 1068 IdleSpeedIncrease_El 1 "Yes" 0 "No" ;
VAL_ 1068 Batt_Lo_SoC_B 1 "Active" 0 "Inactive" ;
VAL_ 1068 PeriodicElLoad_B_Stat 1 "Active" 0 "Inactive" ;
VAL_ 1068 Batt_Crit_SoC_B 1 "Active" 0 "Inactive" ;
VAL_ 947 ValetMode_D_Mem 1 "On" 0 "Off" ;
VAL_ 947 DrStatDrvErrCnt_B_Stat 1 "Yes" 0 "No" ;
VAL_ 947 TurnLghtRight_D_Rq 3 "Seq" 2 "On" 1 "Off" 0 "Null" ;
VAL_ 947 TurnLghtRightOn_B_Stat 1 "On" 0 "Off" ;
VAL_ 947 TurnLghtLeftOn_B_Stat 1 "On" 0 "Off" ;
VAL_ 947 FogLghtRearOn_B_Stat 1 "On" 0 "Off" ;
VAL_ 947 Backlit_LED_Status 15 "Unused3" 14 "Unused2" 13 "Unused1" 12 "Night_12" 11 "Night_11" 10 "Night_10" 9 "Night_9" 8 "Night_8" 7 "Night_7" 6 "Night_6" 5 "Night_5" 4 "Night_4" 3 "Night_3" 2 "Night_2" 1 "Night_1" 0 "Off" ;
VAL_ 947 TurnLghtLeft_D_Rq 3 "Seq" 2 "On" 1 "Off" 0 "Null" ;
VAL_ 947 FogLghtFrontOn_B_Stat 1 "On" 0 "Off" ;
VAL_ 947 IgnKeyType_D_Actl 15 "Invalid" 14 "Unknown" 3 "Key_Not_Prgrm_Read_Failure" 2 "Key_In_Ign_My_Key" 1 "Key_In_Ign_Standard_Key" 0 "Key_Read_In_Progress" ;
VAL_ 947 Parklamp_Status 3 "Invalid" 2 "Unknown" 1 "On" 0 "Off" ;
VAL_ 947 Litval 255 "Invalid" 254 "Unknown" 5 "Day" 4 "Twilight_4" 3 "Twilight_3" 2 "Twilight_2" 1 "Twilight_1" 0 "Night" ;
VAL_ 947 Key_In_Ignition_Stat 1 "In" 0 "Out" ;
VAL_ 947 Ignition_Status 0 "Unknown" 1 "Off" 15 "Invalid" 8 "Start" 4 "Run" 2 "Accessory" ;
VAL_ 947 Dimming_Lvl 255 "Invalid" 254 "Unknown" 18 "Day_6" 17 "Day_5" 16 "Day_4" 15 "Day_3" 14 "Day_2" 13 "Day_1" 12 "Night_12" 11 "Night_11" 10 "Night_10" 9 "Night_9" 8 "Night_8" 7 "Night_7" 6 "Night_6" 5 "Night_5" 4 "Night_4" 3 "Night_3" 2 "Night_2" 1 "Night_1" 0 "Off" ;
VAL_ 947 Day_Night_Status 3 "NotUsed" 2 "Night" 1 "Day" 0 "Null" ;
VAL_ 947 Remote_Start_Status 3 "Invalid" 2 "Unknown" 1 "Remote" 0 "Null" ;
VAL_ 947 DrStatTgate_B_Actl 1 "Ajar" 0 "Closed" ;
VAL_ 947 DrStatRr_B_Actl 1 "Ajar" 0 "Closed" ;
VAL_ 947 DrStatRl_B_Actl 1 "Ajar" 0 "Closed" ;
VAL_ 947 DrStatPsngr_B_Actl 1 "Ajar" 0 "Closed" ;
VAL_ 947 DrStatInnrTgate_B_Actl 1 "Ajar" 0 "Closed" ;
VAL_ 947 DrStatHood_B_Actl 1 "Ajar" 0 "Closed" ;
VAL_ 947 DrStatDrv_B_Actl 1 "Ajar" 0 "Closed" ;
VAL_ 947 PrkBrkActv_B_Actl 1 "Active" 0 "Inactive" ;
VAL_ 947 LifeCycMde_D_Actl 3 "Transport" 2 "NotUsed" 1 "Factory" 0 "Normal" ;
VAL_ 947 Delay_Accy 1 "On" 0 "Off" ;
VAL_ 947 CrashEvnt_D_Stat 3 "Invalid" 2 "Fuel_Cutoff_Event" 1 "Deploy_Event" 0 "No_Event" ;
VAL_ 947 FuelPmpInhbt_B_Stat 1 "Inhibit" 0 "No_Inibit" ;
VAL_ 947 BodySrvcRqd_B_Rq 1 "Yes" 0 "No" ;
VAL_ 986 Trlr_M_Rq 2047 "Faulty" 2046 "NoDataExists" ;
VAL_ 986 TailLghtLoadMde_D_Rq 7 "NotUsed_3" 6 "NotUsed_2" 5 "NotUsed_1" 4 "DeactivateAll" 3 "ActivateFalrMode" 2 "ActivateHitchLoadMode" 1 "ActivatePayloadMode" 0 "NoCommand" ;
VAL_ 986 VehPayloadTare_D_Rq 1 "Request" 0 "NoRequest" ;
VAL_ 986 VehFalr_D_Rq 7 "NotUsed_3" 6 "NotUsed_2" 5 "NotUsed_1" 4 "NotComplete" 3 "Complete" 2 "RequestSecondMeasurement" 1 "RequestFirstMeasurement" 0 "NoRequest" ;
VAL_ 986 VehPayloadScrn_D_Rq 7 "CheckLoadScreenActive" 6 "WeightCarryScreenActive" 5 "GooseneckScreenActive" 4 "FifthWheelScreenActive" 3 "WeightDistScreenActive" 2 "AddMassEstScreenActive" 1 "PayloadEstScreenActive" 0 "ScaleScreenNotActive" ;
VAL_ 986 LightAmbIntsty_No_Rq 0 "Off" ;
VAL_ 995 KeyAssocCmplt_B_Rq 1 "Yes" 0 "No" ;
VAL_ 995 FobAssocChime_B_Rq 1 "On" 0 "Off" ;
VAL_ 995 LightAmbIntsty_No_Actl 0 "Off" ;
VAL_ 995 PersIndexBcm_D_Actl 7 "Unused_3" 6 "Unused_2" 5 "Unused_1" 4 "Vehicle" 3 "PERS_4" 2 "PERS_3" 1 "PERS_2" 0 "PERS_1" ;
VAL_ 963 Illuminated_Entry_Stat 3 "Invalid" 2 "Unknown" 1 "On" 0 "Off" ;
VAL_ 963 Dr_Courtesy_Light_Stat 3 "Invalid" 2 "Unknown" 1 "On" 0 "Off" ;
VAL_ 963 Courtesy_Delay_Status 3 "Invalid" 2 "Unknown" 1 "On" 0 "Off" ;
VAL_ 963 ImpactEvntFdbck_D_Stat 3 "NotUsed" 2 "EventComplete" 1 "EventInProgress" 0 "Normal" ;
VAL_ 963 WrlssAcsyChrgInhbt_B_Rq 1 "Yes" 0 "No" ;
VAL_ 963 PudLampPsngr_D_Rq 3 "Ramp_Down" 2 "Ramp_Up" 1 "On" 0 "Off" ;
VAL_ 963 HeadLampLoOut_B_Stat 1 "Out" 0 "Null" ;
VAL_ 963 HeadLghtHiFdbck_D_Stat 3 "NotUsed" 2 "Cancel" 1 "Hold" 0 "Allow_Change" ;
VAL_ 963 PudLampDrv_D_Rq 3 "Ramp_Down" 2 "Ramp_Up" 1 "On" 0 "Off" ;
VAL_ 963 TrnNotInPrkChime_B_Rq 1 "On" 0 "Off" ;
VAL_ 963 PrkLightChime_B_Rq 1 "On" 0 "Off" ;
VAL_ 963 KeyInIgnWarn_B_Cmd 1 "On" 0 "Off" ;
VAL_ 963 HomeSafeLtChime_B_Rq 1 "On" 0 "Off" ;
VAL_ 963 StopLghtOn_B_Stat 1 "On" 0 "Off" ;
VAL_ 963 RvrseLghtOn_B_Stat 1 "On" 0 "Off" ;
VAL_ 963 PrkLght_D_Stat 3 "Park_Both" 2 "Park_Right" 1 "Park_Left" 0 "Off" ;
VAL_ 963 HeadLghtSwtch_D_Stat 3 "Autolamp" 2 "Headlamp" 1 "Parklamp" 0 "Off" ;
VAL_ 963 HeadLampLoFrOn_B_Stat 1 "Low" 0 "Not_Low" ;
VAL_ 963 HeadLampLoFlOn_B_Stat 1 "Low" 0 "Not_Low" ;
VAL_ 963 HeadLampLoActv_B_Stat 1 "On" 0 "Off" ;
VAL_ 963 Headlamp_On_Wrning_Cmd 1 "On" 0 "Off" ;
VAL_ 963 Park_Brake_Chime_Rqst 1 "On" 0 "Off" ;
VAL_ 963 HeadLghtHiOn_B_Stat 1 "On" 0 "Off" ;
VAL_ 963 BrkWarnInd_B_Rq 1 "On" 0 "Off" ;
VAL_ 963 Brk_Fluid_Lvl_Low 3 "Invalid" 2 "Unknown" 1 "Low" 0 "OK" ;
VAL_ 963 ReducedGuard_D_Stat 3 "NotUsed" 2 "Alarm_On" 1 "Alarm_Off_Previously_On" 0 "Alarm_Off" ;
VAL_ 963 Perimeter_Alarm_Status 3 "Activated" 2 "Armed" 1 "Prearmed" 0 "Disarmed" ;
VAL_ 963 Courtesy_BSave_Stat 3 "Invalid" 2 "Unknown" 1 "No_Effect" 0 "Off" ;
VAL_ 963 DrTgateLck_D_Stat 3 "NotUsed" 2 "Unlock" 1 "Lock" 0 "Null" ;
VAL_ 963 WndwGlbl_D_Cmd 7 "NotUsed3" 6 "NotUsed2" 5 "NotUsed1" 4 "GLEARN" 3 "GCLOSE" 2 "GOPEN" 1 "GSTOP" 0 "Null" ;
VAL_ 963 PudLamp_D_Rq 3 "RAMP_DOWN" 2 "RAMP_UP" 1 "ON" 0 "OFF" ;
VAL_ 963 DayRnngLampOn_B_Stat 1 "On" 0 "Off" ;
VAL_ 963 PerimeterAlarmChimeRq 1 "On" 0 "Off" ;
VAL_ 909 IgnPsswrdDsply_B_Rq 1 "Active" 0 "Inactive" ;
VAL_ 909 ElPwPoint_D_Rq 3 "On" 2 "Off2" 1 "Off1" 0 "Null" ;
VAL_ 909 PoliceIdlMde_D_Stat 15 "NotUsed_7" 14 "NotUsed_6" 13 "NotUsed_5" 12 "NotUsed_4" 11 "NotUsed_3" 10 "UtilityIdleActive" 9 "PepsActive" 8 "Decommissioned" 7 "ActiveFault" 6 "ArmFault" 5 "PrearmedFault" 4 "OffFault" 3 "Active" 2 "Arm" 1 "Prearmed" 0 "Off" ;
VAL_ 909 DrLatchMsgTxt_D_Rq 7 "Message7" 6 "Message6" 5 "Message5" 4 "Message4" 3 "Message3" 2 "Message2" 1 "Message1" 0 "NoMessage" ;
VAL_ 909 HazrdLght_B_Stat 1 "On" 0 "Off" ;
VAL_ 909 SecurityMsgTxt_D_Rq 3 "Message3" 2 "Message2" 1 "Message1" 0 "NoMessage" ;
VAL_ 909 PrmtrAlrmEvnt_D_Stat 15 "Diag_Tamper" 14 "Trailer" 13 "Shock_Sensor" 12 "Post_Crash" 11 "Panic" 10 "Intrusion" 9 "Inclination" 8 "Ign_Tamper" 7 "LG_Door" 6 "Decklid" 5 "Hood" 4 "PR_Door" 3 "PF_Door" 2 "DR_Door" 1 "DF_Door" 0 "Null" ;
VAL_ 909 HeadLghtHiPrmsn_D_Stat 3 "CancelAndSuppress" 2 "Cancel" 1 "Hold" 0 "AllowChange" ;
VAL_ 909 SteWhlLckMsgTxt_D_Rq 3 "Message_3" 2 "Message_2" 1 "Message_1" 0 "No_Message" ;
VAL_ 909 immoMsgTxt_D_Rq 15 "Immo_Msg_15" 14 "Immo_Msg_14" 13 "Immo_Msg_13" 12 "Immo_Msg_12" 11 "Immo_Msg_11" 10 "Immo_Msg_10" 9 "Immo_Msg_9" 8 "Immo_Msg_8" 7 "Immo_Msg_7" 6 "Immo_Msg_6" 5 "Immo_Msg_5" 4 "Immo_Msg_4" 3 "Immo_Msg_3" 2 "Immo_Msg_2" 1 "Immo_Msg_1" 0 "Immo_Msg_0_Null" ;
VAL_ 909 PrsnlDevcChrgEnbl_B_Rq 1 "Active" 0 "Inactive" ;
VAL_ 909 TracKeyMde_D_Stat 3 "NotUsed" 2 "NotActive" 1 "Active" 0 "ModeNotDetermined" ;
VAL_ 909 PEBackupSlot_Stats 3 "No_Valid_FOB_In_Slot" 2 "MyKey_FOB_In_Slot" 1 "Standard_FOB_In_Slot" 0 "Null" ;
VAL_ 909 KeyMykeyTot_No_Cnt 13 "Thirteen" 12 "Twelve" 11 "Eleven" 10 "Ten" 9 "Nine" 8 "Eight" 7 "Seven" 6 "Six" 5 "Five" 4 "Four" 3 "Three" 2 "Two" 1 "One" 0 "Zero" 15 "Invalid" 14 "Unlimited" ;
VAL_ 909 KeyAdmnTot_No_Cnt 13 "Thirteen" 12 "Twelve" 11 "Eleven" 10 "Ten" 9 "Nine" 8 "Eight" 7 "Seven" 6 "Six" 5 "Five" 4 "Four" 3 "Three" 2 "Two" 1 "One" 0 "Zero" 15 "Invalid" 14 "Unlimited" ;
VAL_ 936 ApaButtnPrssd_B_Stat 1 "Pressed" 0 "Not_Pressed" ;
VAL_ 936 ApaSys_D_Stat 7 "Faulty" 6 "Finished" 5 "NotAccessible" 4 "ApaCancelled" 3 "Overspeed" 2 "On" 1 "Off" 0 "Null" ;
VAL_ 936 ApaSteWhl_D_RqDrv 3 "TakeControl" 2 "RemoveHands" 1 "NoRequest" 0 "Null" ;
VAL_ 936 ApaSteScanMde_D_Stat 3 "Steering" 2 "Scanning" 1 "NotScanning" 0 "Null" ;
VAL_ 936 ApaSelSapp_D_Stat 3 "NotConfigured" 2 "NotSelectable" 1 "Selectable" 0 "Null" ;
VAL_ 936 ApaSelPpa_D_Stat 3 "NotConfigured" 2 "NotSelectable" 1 "Selectable" 0 "Null" ;
VAL_ 936 ApaSelPoa_D_Stat 3 "NotConfigured" 2 "NotSelectable" 1 "Selectable" 0 "Null" ;
VAL_ 936 ApaScan_D_Stat 3 "ParkSlotReady" 2 "ParkSlotFound" 1 "NoParkSlot" 0 "Null" ;
VAL_ 936 ApaLongCtl_D_RqDrv 7 "NotUsed3" 6 "NotUsed2" 5 "ReleaseBrake" 4 "DriveBackward" 3 "DriveForward" 2 "Stop" 1 "NoRequest" 0 "Null" ;
VAL_ 936 ApaGearShif_D_RqDrv 7 "NotUSed2" 6 "NotUsed1" 5 "ShiftToP" 4 "ShiftToN" 3 "ShiftToD" 2 "ShiftToR" 1 "NoRequest" 0 "Null" ;
VAL_ 936 ApaActvSide2_D_Stat 3 "NoSide" 2 "Right" 1 "Left" 0 "Null" ;
VAL_ 936 ApaAcsy_D_RqDrv 7 "CloseDoor" 6 "SelectSideRight" 5 "SelectSideLeft" 4 "CheckForObject" 3 "PressApaButton" 2 "SelectSide" 1 "NoRequest" 0 "Null" ;
VAL_ 936 ApaTrgtDist_D_Stat 15 "Step15" 14 "Step14" 13 "Step13" 12 "Step12" 11 "Step11" 10 "Step10" 9 "Step9" 8 "Step8" 7 "Step7" 6 "Step6" 5 "Step5" 4 "Step4" 3 "Step3" 2 "Step2" 1 "Step1" 0 "Off" ;
VAL_ 936 ApaMsgTxt_D_Rq 15 "NotUsed_6" 14 "NotUsed_5" 13 "NotUsed_4" 12 "NotUsed_3" 11 "ReleaseEpb" 10 "TrailerFeatureNotAvailable" 9 "AccelPedalInactive" 8 "WrongDirection" 7 "SteeringInteraction" 6 "BrakingActive" 5 "HighInclination" 4 "SpeedLimitExceeded" 3 "TcsDisabled" 2 "WheelSlip" 1 "None" 0 "Null" ;
VAL_ 936 ApaChime_D_Rq 7 "NotUsed2" 6 "NotUsed1" 5 "Warning_Chime" 4 "Finish_Chime" 3 "Stop_Now_Chime" 2 "Spot_Ready_Chime" 1 "Spot_Found_Chime" 0 "No_Chime" ;
VAL_ 936 EPASExtAngleStatReq 1 "Request" 0 "NoRequest" ;
VAL_ 936 ExtSteeringAngleReq2 32767 "Invalid" 32766 "Unknown" ;
VAL_ 950 Modulation_Ctrl 3 "Unused" 2 "FSK" 1 "ASK_FSK" 0 "ASK" ;
VAL_ 950 TirePress_Filter_Ctrl 3 "Streaming" 2 "Filter" 1 "Not_Used" 0 "Null" ;
VAL_ 71 immoTarget1Status 7 "Unused4" 6 "Unused3" 5 "Unused2" 4 "ENABLED_LIMITEDMOTIVE_STAR" 3 "DISABLED_RESET   " 2 "ENABLED_NONMOTIVE_START" 1 "ENABLED_MOTIVE_START" 0 "DISABLED" ;
VAL_ 71 immoTarget1Cmd 7 "Unused4" 6 "Unused3" 5 "Unused2" 4 "Unused1" 3 "TARGET1_IDBLOCK2" 2 "TARGET1_IDBLOCK1" 1 "CHALLENGE" 0 "IDLE" ;
